VERSION ""

NS_ :

BS_:

BU_: SCCM RF_HUB PTS ORC OCM IC HCP HALF ETM ESM ESC EPS ECM EBCM DIAGNOST DASM CBC AirSusp TCM DTCM ELSDM

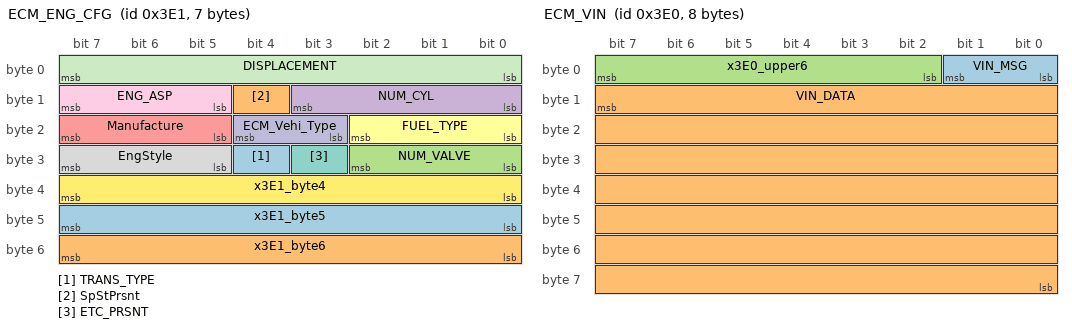
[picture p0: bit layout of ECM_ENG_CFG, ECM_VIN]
BO_ 993 ECM_ENG_CFG: 7 ECM
 SG_ TRANS_TYPE : 28|1@1+ (1,0) [0|0] "" Vector__XXX
 SG_ SpStPrsnt : 12|1@1+ (1,0) [0|0] ""  PTS,HALF,ESC,EPS,CBC
 SG_ NUM_VALVE : 24|3@1+ (1,0) [0|6] "valve-per-cylinder" Vector__XXX
 SG_ NUM_CYL : 8|4@1+ (1,0) [0|14] "cylinders"  IC,HALF,ESC
 SG_ Manufacture : 21|3@1+ (1,0) [0|0] "" Vector__XXX
 SG_ FUEL_TYPE : 16|3@1+ (1,0) [0|0] ""  ORC,IC,ESC,CBC
 SG_ ETC_PRSNT : 27|1@1+ (1,0) [0|0] "" Vector__XXX
 SG_ EngStyle : 29|3@1+ (1,0) [0|0] ""  ESC,CBC
 SG_ ENG_ASP : 13|3@1+ (1,0) [0|0] ""  ESC
 SG_ ECM_Vehi_Type : 19|2@1+ (1,0) [0|0] "" Vector__XXX
 SG_ DISPLACEMENT : 0|8@1+ (0.1,0) [0|25] "liters"  ORC,HALF,ESC
 SG_ x3E1_byte4 : 32|8@1+ (1,0) [0|0] "" Vector__XXX
 SG_ x3E1_byte5 : 40|8@1+ (1,0) [0|0] "" Vector__XXX
 SG_ x3E1_byte6 : 48|8@1+ (1,0) [0|0] "" Vector__XXX

BO_ 992 ECM_VIN: 8 ECM
 SG_ VIN_MSG : 0|2@1+ (1,0) [0|0] ""  EBCM,HCP,ETM,HALF,OCM,ORC,ESM,DASM,ESC,SCCM,EPS,PTS,IC,CBC,RF_HUB
 SG_ VIN_DATA : 15|56@0+ (1,0) [0|0] ""  SCCM,RF_HUB,PTS,ORC,OCM,IC,HCP,HALF,ETM,ESM,ESC,EPS,EBCM,DASM,CBC
 SG_ x3E0_upper6 : 2|6@1+ (1,0) [0|0] "" Vector__XXX

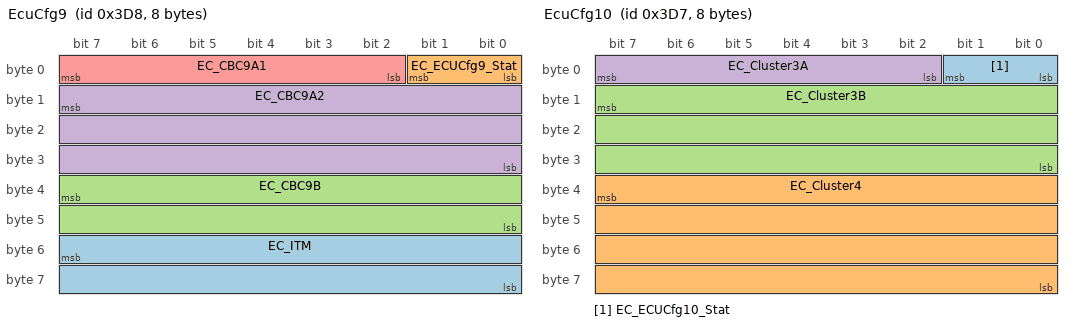
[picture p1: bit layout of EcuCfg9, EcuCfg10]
BO_ 984 EcuCfg9: 8 CBC
 SG_ EC_ITM : 55|16@0+ (1,0) [0|0] ""  RF_HUB
 SG_ EC_ECUCfg9_Stat : 0|2@1+ (1,0) [0|0] ""  RF_HUB
 SG_ EC_CBC9B : 39|16@0+ (1,0) [0|0] ""  RF_HUB
 SG_ EC_CBC9A2 : 15|24@0+ (1,0) [0|0] ""  RF_HUB
 SG_ EC_CBC9A1 : 2|6@1+ (1,0) [0|0] ""  RF_HUB

BO_ 983 EcuCfg10: 8 CBC
 SG_ EC_ECUCfg10_Stat : 0|2@1+ (1,0) [0|0] ""  IC,RF_HUB
 SG_ EC_Cluster4 : 39|32@0+ (1,0) [0|0] ""  RF_HUB
 SG_ EC_Cluster3B : 15|24@0+ (1,0) [0|0] ""  RF_HUB
 SG_ EC_Cluster3A : 2|6@1+ (1,0) [0|0] ""  RF_HUB

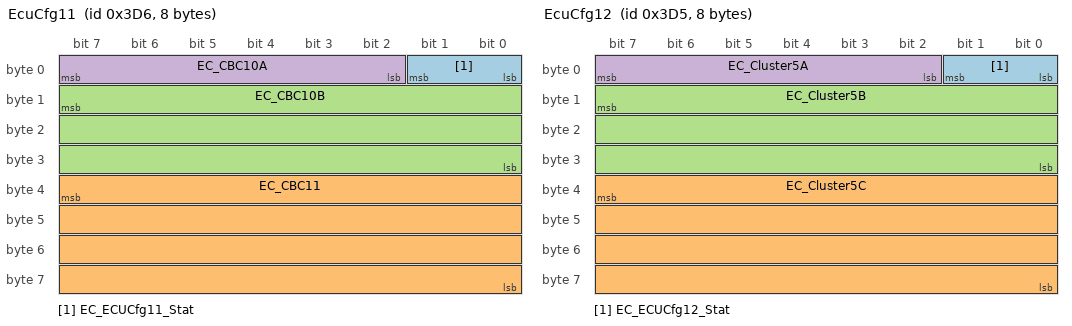
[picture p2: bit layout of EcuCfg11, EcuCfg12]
BO_ 982 EcuCfg11: 8 CBC
 SG_ EC_ECUCfg11_Stat : 0|2@1+ (1,0) [0|0] ""  RF_HUB
 SG_ EC_CBC11 : 39|32@0+ (1,0) [0|0] ""  RF_HUB
 SG_ EC_CBC10B : 15|24@0+ (1,0) [0|0] ""  RF_HUB
 SG_ EC_CBC10A : 2|6@1+ (1,0) [0|0] ""  RF_HUB

BO_ 981 EcuCfg12: 8 CBC
 SG_ EC_ECUCfg12_Stat : 0|2@1+ (1,0) [0|0] ""  IC,RF_HUB
 SG_ EC_Cluster5C : 39|32@0+ (1,0) [0|0] ""  RF_HUB
 SG_ EC_Cluster5B : 15|24@0+ (1,0) [0|0] ""  RF_HUB
 SG_ EC_Cluster5A : 2|6@1+ (1,0) [0|0] ""  RF_HUB

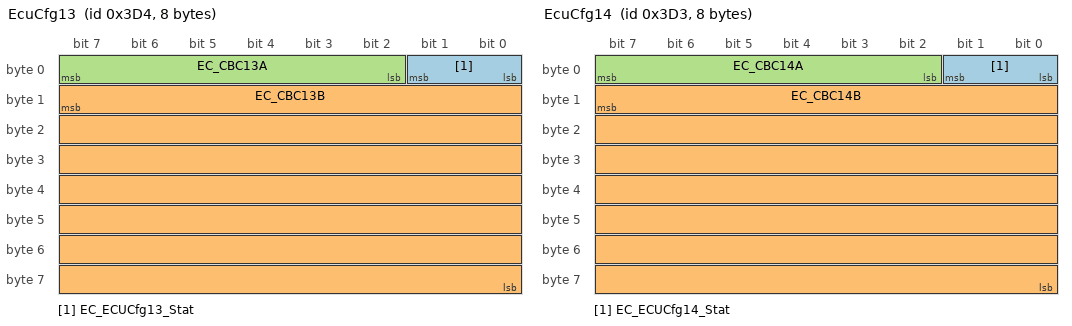
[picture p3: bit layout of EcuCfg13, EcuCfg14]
BO_ 980 EcuCfg13: 8 CBC
 SG_ EC_ECUCfg13_Stat : 0|2@1+ (1,0) [0|0] ""  RF_HUB
 SG_ EC_CBC13B : 15|56@0+ (1,0) [0|0] ""  RF_HUB
 SG_ EC_CBC13A : 2|6@1+ (1,0) [0|0] ""  RF_HUB

BO_ 979 EcuCfg14: 8 CBC
 SG_ EC_ECUCfg14_Stat : 0|2@1+ (1,0) [0|0] ""  RF_HUB
 SG_ EC_CBC14B : 15|56@0+ (1,0) [0|0] ""  RF_HUB
 SG_ EC_CBC14A : 2|6@1+ (1,0) [0|0] ""  RF_HUB

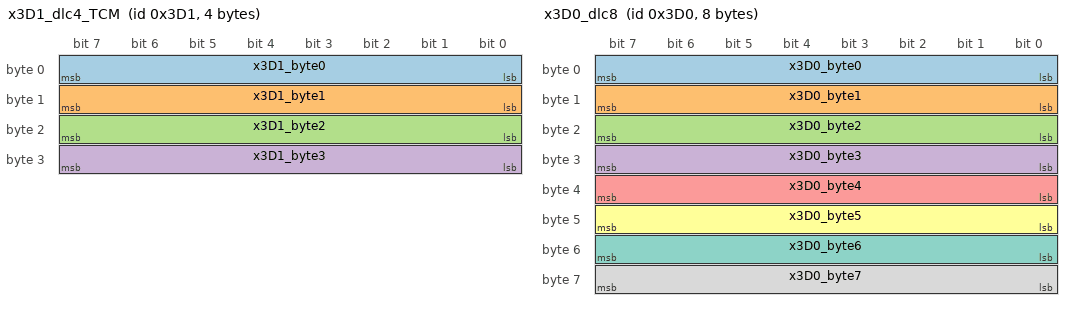
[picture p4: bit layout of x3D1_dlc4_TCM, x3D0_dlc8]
BO_ 977 x3D1_dlc4_TCM: 4 TCM
 SG_ x3D1_byte0 : 0|8@1+ (1,0) [0|255] "" Vector__XXX
 SG_ x3D1_byte1 : 8|8@1+ (1,0) [0|255] "" Vector__XXX
 SG_ x3D1_byte2 : 16|8@1+ (1,0) [0|255] "" Vector__XXX
 SG_ x3D1_byte3 : 24|8@1+ (1,0) [0|255] "" Vector__XXX

BO_ 976 x3D0_dlc8: 8 Vector__XXX
 SG_ x3D0_byte0 : 0|8@1+ (1,0) [0|255] "" Vector__XXX
 SG_ x3D0_byte1 : 8|8@1+ (1,0) [0|255] "" Vector__XXX
 SG_ x3D0_byte2 : 16|8@1+ (1,0) [0|255] "" Vector__XXX
 SG_ x3D0_byte3 : 24|8@1+ (1,0) [0|255] "" Vector__XXX
 SG_ x3D0_byte4 : 32|8@1+ (1,0) [0|255] "" Vector__XXX
 SG_ x3D0_byte5 : 40|8@1+ (1,0) [0|255] "" Vector__XXX
 SG_ x3D0_byte6 : 48|8@1+ (1,0) [0|255] "" Vector__XXX
 SG_ x3D0_byte7 : 56|8@1+ (1,0) [0|255] "" Vector__XXX

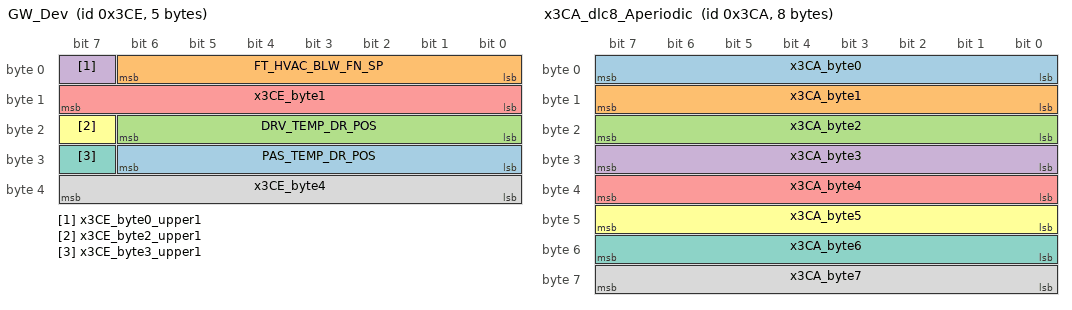
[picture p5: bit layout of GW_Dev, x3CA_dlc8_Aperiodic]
BO_ 974 GW_Dev: 5 CBC
 SG_ PAS_TEMP_DR_POS : 24|7@1+ (1,0) [0|100] "%"  HCP
 SG_ FT_HVAC_BLW_FN_SP : 0|7@1+ (1,0) [0|100] "Bars"  ECM
 SG_ DRV_TEMP_DR_POS : 16|7@1+ (1,0) [0|100] "%"  HCP,ECM
 SG_ x3CE_byte0_upper1 : 7|1@1+ (1,0) [0|1] "" Vector__XXX
 SG_ x3CE_byte1 : 8|8@1+ (1,0) [0|255] "" Vector__XXX
 SG_ x3CE_byte2_upper1 : 23|1@1+ (1,0) [0|1] "" Vector__XXX
 SG_ x3CE_byte3_upper1 : 31|1@1+ (1,0) [0|1] "" Vector__XXX
 SG_ x3CE_byte4 : 32|8@1+ (1,0) [0|255] "" Vector__XXX

BO_ 973 x3CD_dlc8_IC: 8 IC
 SG_ x3CD_byte0_lower6 : 0|6@1+ (1,0) [0|63] "" Vector__XXX
 SG_ x3CD_byte1 : 8|8@1+ (1,0) [0|255] "" Vector__XXX
 SG_ x3CD_byte2 : 16|8@1+ (1,0) [0|255] "" Vector__XXX
 SG_ x3CD_byte3 : 24|8@1+ (1,0) [0|255] "" Vector__XXX
 SG_ x3CD_byte4 : 32|8@1+ (1,0) [0|255] "" Vector__XXX
 SG_ x3CD_byte5 : 40|8@1+ (1,0) [0|255] "" Vector__XXX
 SG_ x3CD_byte6 : 48|8@1+ (1,0) [0|255] "" Vector__XXX
 SG_ x3CD_byte7 : 56|8@1+ (1,0) [0|255] "" Vector__XXX
 SG_ x3CD_IC_RedBRAKELampOn : 7|1@1+ (1,0) [0|1] "Bool" Vector__XXX
 SG_ x3CD_byte0_upper1 : 8|1@1+ (1,0) [0|1] "" Vector__XXX

BO_ 970 x3CA_dlc8_Aperiodic: 8 Vector__XXX
 SG_ x3CA_byte0 : 0|8@1+ (1,0) [0|255] "" Vector__XXX
 SG_ x3CA_byte1 : 8|8@1+ (1,0) [0|255] "" Vector__XXX
 SG_ x3CA_byte2 : 16|8@1+ (1,0) [0|255] "" Vector__XXX
 SG_ x3CA_byte3 : 24|8@1+ (1,0) [0|255] "" Vector__XXX
 SG_ x3CA_byte4 : 32|8@1+ (1,0) [0|255] "" Vector__XXX
 SG_ x3CA_byte5 : 40|8@1+ (1,0) [0|255] "" Vector__XXX
 SG_ x3CA_byte6 : 48|8@1+ (1,0) [0|255] "" Vector__XXX
 SG_ x3CA_byte7 : 56|8@1+ (1,0) [0|255] "" Vector__XXX

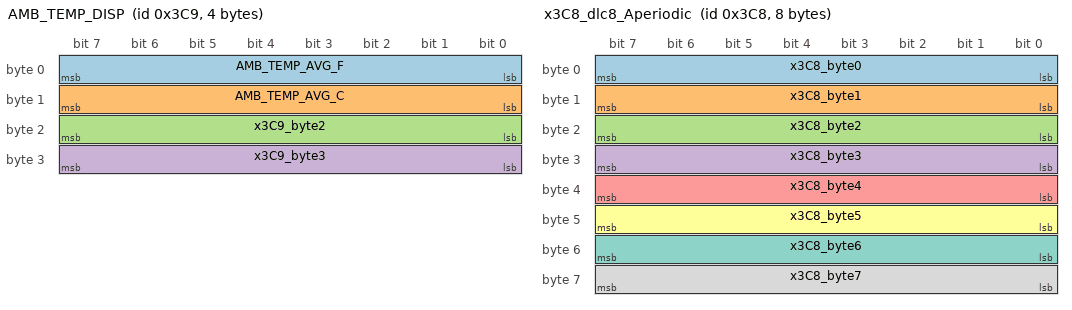
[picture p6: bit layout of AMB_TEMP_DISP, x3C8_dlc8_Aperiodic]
BO_ 969 AMB_TEMP_DISP: 4 CBC
 SG_ AMB_TEMP_AVG_F : 0|8@1+ (1,-40) [-40|210] "°F"  IC,HCP
 SG_ AMB_TEMP_AVG_C : 8|8@1+ (1,-40) [-40|210] "°C"  IC,ETM
 SG_ x3C9_byte2 : 16|8@1+ (1,0) [0|255] "" Vector__XXX
 SG_ x3C9_byte3 : 24|8@1+ (1,0) [0|255] "" Vector__XXX

BO_ 968 x3C8_dlc8_Aperiodic: 8 Vector__XXX
 SG_ x3C8_byte0 : 0|8@1+ (1,0) [0|255] "" Vector__XXX
 SG_ x3C8_byte1 : 8|8@1+ (1,0) [0|255] "" Vector__XXX
 SG_ x3C8_byte2 : 16|8@1+ (1,0) [0|255] "" Vector__XXX
 SG_ x3C8_byte3 : 24|8@1+ (1,0) [0|255] "" Vector__XXX
 SG_ x3C8_byte4 : 32|8@1+ (1,0) [0|255] "" Vector__XXX
 SG_ x3C8_byte5 : 40|8@1+ (1,0) [0|255] "" Vector__XXX
 SG_ x3C8_byte6 : 48|8@1+ (1,0) [0|255] "" Vector__XXX
 SG_ x3C8_byte7 : 56|8@1+ (1,0) [0|255] "" Vector__XXX

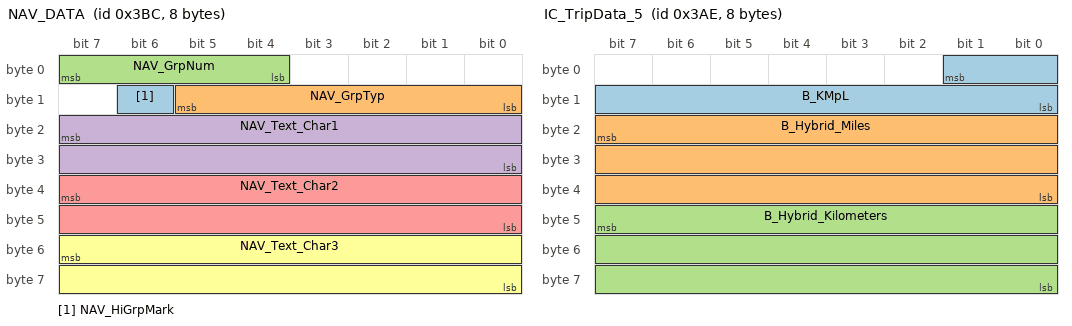
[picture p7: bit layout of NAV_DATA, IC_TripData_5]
BO_ 956 NAV_DATA: 8 CBC
 SG_ NAV_HiGrpMark : 14|1@1+ (1,0) [0|0] ""  IC
 SG_ NAV_GrpTyp : 8|6@1+ (1,0) [0|40] "Text"  IC
 SG_ NAV_GrpNum : 4|4@1+ (1,1) [1|16] "Group"  IC
 SG_ NAV_Text_Char1 : 23|16@0+ (1,0) [0|65535] "ascii" Vector__XXX
 SG_ NAV_Text_Char2 : 39|16@0+ (1,0) [0|65535] "ascii" Vector__XXX
 SG_ NAV_Text_Char3 : 55|16@0+ (1,0) [0|65535] "ascii" Vector__XXX

BO_ 948 VehCfgCSM2: 8 CBC
 SG_ VC_WHL_ALGN_CSO : 13|1@1+ (1,0) [0|0] ""  RF_HUB
 SG_ VC_VehCfgCSO2_Stat : 0|2@1+ (1,0) [0|0] ""  RF_HUB,IC
 SG_ VC_US_METRIC_CSO : 12|1@1+ (1,0) [0|0] ""  RF_HUB
 SG_ VC_TRNS_MD_CSO : 11|1@1+ (1,0) [0|0] ""  RF_HUB
 SG_ VC_TRLR_TYPE_CSO : 10|1@1+ (1,0) [0|0] ""  RF_HUB
 SG_ VC_TRLR_NAME_CSO : 9|1@1+ (1,0) [0|0] ""  RF_HUB
 SG_ VC_TRLR_CSO : 8|1@1+ (1,0) [0|0] ""  RF_HUB
 SG_ VC_TORQUE_CSO : 7|1@1+ (1,0) [0|0] ""  RF_HUB
 SG_ VC_TLT_MRR_CSO : 6|1@1+ (1,0) [0|0] ""  RF_HUB
 SG_ VC_TEMP_CSO : 15|1@1+ (1,0) [0|0] ""  RF_HUB
 SG_ VC_TEEN_SLD_DR_CHM_CSO : 38|1@1+ (1,0) [0|0] ""  RF_HUB
 SG_ VC_TEEN_SLD_DR_ALRT_CSO : 35|1@1+ (1,0) [0|0] ""  RF_HUB
 SG_ VC_TEEN_RR_PRK_VOL_CSO : 27|1@1+ (1,0) [0|0] ""  RF_HUB
 SG_ VC_TEEN_RAIN_WPR_CSO : 32|1@1+ (1,0) [0|0] ""  RF_HUB
 SG_ VC_TEEN_PRK_ASST_CSO : 25|1@1+ (1,0) [0|0] ""  RF_HUB
 SG_ VC_TEEN_PLG_CHIME_CSO : 36|1@1+ (1,0) [0|0] ""  RF_HUB
 SG_ VC_TEEN_MAX_SPEED_CSO : 28|1@1+ (1,0) [0|0] ""  RF_HUB
 SG_ VC_TEEN_LGHT_WPR_CSO : 34|1@1+ (1,0) [0|0] ""  RF_HUB
 SG_ VC_TEEN_FUEL_WRN_CSO : 29|1@1+ (1,0) [0|0] ""  RF_HUB
 SG_ VC_TEEN_FUEL_POPUP_CSO : 30|1@1+ (1,0) [0|0] ""  RF_HUB
 SG_ VC_TEEN_FT_PRK_VOL_CSO : 26|1@1+ (1,0) [0|0] ""  RF_HUB
 SG_ VC_TEEN_FCW_SENS_CSO : 23|1@1+ (1,0) [0|0] ""  RF_HUB
 SG_ VC_TEEN_FCW_BRK_CSO : 24|1@1+ (1,0) [0|0] ""  RF_HUB
 SG_ VC_TEEN_BLIND_SPOT_CSO : 31|1@1+ (1,0) [0|0] ""  RF_HUB
 SG_ VC_TEEN_AUTO_HB_CSO : 33|1@1+ (1,0) [0|0] ""  RF_HUB
 SG_ VC_SVC_GRIDLINES_CSO : 20|1@1+ (1,0) [0|0] ""  RF_HUB
 SG_ VC_SVC_DELAY_CSO : 21|1@1+ (1,0) [0|0] ""  RF_HUB
 SG_ VC_SPEED_WARNING_CSO : 41|2@1+ (1,0) [0|0] ""  RF_HUB
 SG_ VC_SPEED_CSO : 5|1@1+ (1,0) [0|0] ""  RF_HUB
 SG_ VC_SLD_DR_CHM_CSO : 37|1@1+ (1,0) [0|0] ""  RF_HUB
 SG_ VC_SLD_DR_ALRT_CSO : 22|1@1+ (1,0) [0|0] ""  RF_HUB
 SG_ VC_RKE_UNLK_CSO : 4|1@1+ (1,0) [0|0] ""  RF_HUB
 SG_ VC_RKE_MEM_CSO : 3|1@1+ (1,0) [0|0] ""  RF_HUB
 SG_ VC_REAR_CMRA_DLY_CSO : 2|1@1+ (1,0) [0|0] ""  RF_HUB
 SG_ VC_RDY_DRV_CSO : 55|1@1+ (1,0) [0|0] ""  RF_HUB
 SG_ VC_PWR_FLD_MRR_CSO : 17|1@1+ (1,0) [0|0] ""  RF_HUB
 SG_ VC_PRK_ASST_TYPE_CSO : 44|1@1+ (1,0) [0|0] ""  RF_HUB
 SG_ VC_PADDLE_SHIFT_CSO : 39|1@1+ (1,0) [0|0] ""  RF_HUB
 SG_ VC_LDW_ON_CSO : 43|1@1+ (1,0) [0|0] ""  RF_HUB
 SG_ VC_HOLD_N_GO_CSO : 16|1@1+ (1,0) [0|0] ""  RF_HUB
 SG_ VC_HANDS_FREE_SLDR_CSO : 19|1@1+ (1,0) [0|0] ""  RF_HUB
 SG_ VC_HANDS_FREE_LFT_CSO : 18|1@1+ (1,0) [0|0] ""  RF_HUB
 SG_ VC_FUEL_SAV_CSO : 14|1@1+ (1,0) [0|0] ""  RF_HUB
 SG_ VC_FLSH_LMP_SLDR_CSO : 40|1@1+ (1,0) [0|0] ""  RF_HUB
 SG_ VC_FCW_SW_CSO : 47|1@1+ (1,0) [0|0] ""  RF_HUB
 SG_ VC_EPB_ON_CSO : 45|1@1+ (1,0) [0|0] ""  RF_HUB
 SG_ VC_AIRBAG_ON_CSO : 46|1@1+ (1,0) [0|0] ""  RF_HUB
 SG_ x3B4_byte6_lower7 : 48|7@1+ (1,0) [0|127] "" Vector__XXX
 SG_ x3B4_byte7 : 56|8@1+ (1,0) [0|255] "" Vector__XXX

BO_ 947 VehCfgCSM1: 8 CBC
 SG_ VC_VehCfgCSO1_Stat : 0|2@1+ (1,0) [0|0] ""  RF_HUB,IC
 SG_ VC_REAR_CMRA_CSO : 63|1@1+ (1,0) [0|0] ""  RF_HUB
 SG_ VC_RAIN_WPR_CSO : 62|1@1+ (1,0) [0|0] ""  RF_HUB
 SG_ VC_PTO_CSO : 61|1@1+ (1,0) [0|0] ""  RF_HUB
 SG_ VC_PRK_RR_VOL_CSO : 6|1@1+ (1,0) [0|0] ""  RF_HUB
 SG_ VC_PRK_FT_VOL_CSO : 5|1@1+ (1,0) [0|0] ""  RF_HUB
 SG_ VC_PRK_AST_CSO : 2|2@1+ (1,0) [0|0] ""  RF_HUB
 SG_ VC_PRK_AST_BRK_CSO : 4|1@1+ (1,0) [0|0] ""  RF_HUB
 SG_ VC_PRESSURE_CSO : 60|1@1+ (1,0) [0|0] ""  RF_HUB
 SG_ VC_POWER_CSO : 59|1@1+ (1,0) [0|0] ""  RF_HUB
 SG_ VC_POLICE_PE_CSO : 23|1@1+ (1,0) [0|0] ""  RF_HUB
 SG_ VC_PLG_CHM_CSO : 58|1@1+ (1,0) [0|0] ""  RF_HUB
 SG_ VC_PER_SHFT_RPM_CSO : 57|1@1+ (1,0) [0|0] ""  RF_HUB
 SG_ VC_PER_SHFT_ENBL_CSO : 56|1@1+ (1,0) [0|0] ""  RF_HUB
 SG_ VC_PE_CSO : 55|1@1+ (1,0) [0|0] ""  RF_HUB
 SG_ VC_NAV_TRN_CSO : 54|1@1+ (1,0) [0|0] ""  RF_HUB
 SG_ VC_LGHT_RMT_LWR_CSO : 53|1@1+ (1,0) [0|0] ""  RF_HUB
 SG_ VC_LDW_WRN_CSO : 52|1@1+ (1,0) [0|0] ""  RF_HUB
 SG_ VC_LDW_TRQ_CSO : 51|1@1+ (1,0) [0|0] ""  RF_HUB
 SG_ VC_ILL_APPRCH_CSO : 50|1@1+ (1,0) [0|0] ""  RF_HUB
 SG_ VC_HSA_CSO : 49|1@1+ (1,0) [0|0] ""  RF_HUB
 SG_ VC_HRN_RMT_ST_CSO : 13|1@1+ (1,0) [0|0] ""  RF_HUB
 SG_ VC_HRN_RMT_LWR_CSO : 14|1@1+ (1,0) [0|0] ""  RF_HUB
 SG_ VC_HRN_RMT_LK_CSO : 11|2@1+ (1,0) [0|0] ""  RF_HUB
 SG_ VC_HL_WPR_CSO : 48|1@1+ (1,0) [0|0] ""  RF_HUB
 SG_ VC_HL_OFF_DLY_CSO : 47|1@1+ (1,0) [0|0] ""  RF_HUB
 SG_ VC_HL_DRP_CSO : 46|1@1+ (1,0) [0|0] ""  RF_HUB
 SG_ VC_FLSH_LMP_LK_CSO : 45|1@1+ (1,0) [0|0] ""  RF_HUB
 SG_ VC_FCW_CSO : 8|2@1+ (1,0) [0|0] ""  RF_HUB
 SG_ VC_FCW_BRK_CSO : 10|1@1+ (1,0) [0|0] ""  RF_HUB
 SG_ VC_EPS_CSO : 7|1@1+ (1,0) [0|0] ""  RF_HUB
 SG_ VC_EPB_SERV_CSO : 44|1@1+ (1,0) [0|0] ""  RF_HUB
 SG_ VC_ENTRY_EXIT_CSO : 43|1@1+ (1,0) [0|0] ""  RF_HUB
 SG_ VC_EASY_EXIT_CSO : 42|1@1+ (1,0) [0|0] ""  RF_HUB
 SG_ VC_DRL_CSO : 41|1@1+ (1,0) [0|0] ""  RF_HUB
 SG_ VC_DR_UNLK_CSO : 40|1@1+ (1,0) [0|0] ""  RF_HUB
 SG_ VC_DR_LK_CSO : 39|1@1+ (1,0) [0|0] ""  RF_HUB
 SG_ VC_DISTANCE_CSO : 38|1@1+ (1,0) [0|0] ""  RF_HUB
 SG_ VC_DCS_CSO : 16|2@1+ (1,0) [0|0] ""  RF_HUB
 SG_ VC_CONS_CSO : 37|1@1+ (1,0) [0|0] ""  RF_HUB
 SG_ VC_CMRA_GRDLNS_CSO : 20|2@1+ (1,0) [0|0] ""  RF_HUB
 SG_ VC_CMP_VAR_CSO : 36|1@1+ (1,0) [0|0] ""  RF_HUB
 SG_ VC_CMP_CAL_CSO : 35|1@1+ (1,0) [0|0] ""  RF_HUB
 SG_ VC_CLK_DSP_CSO : 34|1@1+ (1,0) [0|0] ""  RF_HUB
 SG_ VC_CHMSL_LINE_CSO : 15|1@1+ (1,0) [0|0] ""  RF_HUB
 SG_ VC_CAPACITY_CSO : 33|1@1+ (1,0) [0|0] ""  RF_HUB
 SG_ VC_BLIND_SPOT_CSO : 32|1@1+ (1,0) [0|0] ""  RF_HUB
 SG_ VC_AUX_SWS_CSO : 18|2@1+ (1,0) [0|0] ""  RF_HUB
 SG_ VC_AUTO_PRK_CSO : 31|1@1+ (1,0) [0|0] ""  RF_HUB
 SG_ VC_AUTO_HB_CSO : 30|1@1+ (1,0) [0|0] ""  RF_HUB
 SG_ VC_AUTO_AERO_CSO : 29|1@1+ (1,0) [0|0] ""  RF_HUB
 SG_ VC_ASCM_WRN_CSO : 28|1@1+ (1,0) [0|0] ""  RF_HUB
 SG_ VC_ASCM_TJ_CSO : 27|1@1+ (1,0) [0|0] ""  RF_HUB
 SG_ VC_AMB_DMR_CSO : 26|1@1+ (1,0) [0|0] ""  RF_HUB
 SG_ VC_AFLS_CSO : 25|1@1+ (1,0) [0|0] ""  RF_HUB
 SG_ VC_ACC_DLY_CSO : 24|1@1+ (1,0) [0|0] ""  RF_HUB
 SG_ x3B3_byte2_middle1 : 22|1@1+ (1,0) [0|1] "" Vector__XXX

BO_ 943 IC_TripData_6: 8 IC
 SG_ B_Total_Dist_Miles : 23|24@0+ (0.1,0) [0|9999.9] "Mile"  ETM
 SG_ B_Total_Dist_Kilometers : 47|24@0+ (0.1,0) [0|16093.3] "km"  ETM

BO_ 942 IC_TripData_5: 8 IC
 SG_ B_KMpL : 1|10@0+ (0.1,0) [0|99.9] "kmpl"  ETM
 SG_ B_Hybrid_Miles : 23|24@0+ (0.1,0) [0|9999.9] "Mile"  ETM
 SG_ B_Hybrid_Kilometers : 47|24@0+ (0.1,0) [0|16093.3] "km"  ETM

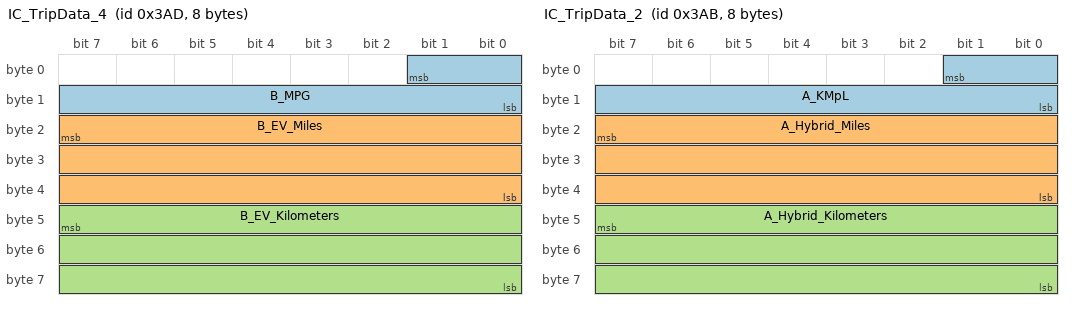
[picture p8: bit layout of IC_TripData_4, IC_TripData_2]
BO_ 941 IC_TripData_4: 8 IC
 SG_ B_MPG : 1|10@0+ (0.1,0) [0|99.9] "MPG"  ETM
 SG_ B_EV_Miles : 23|24@0+ (0.1,0) [0|9999.9] "Mile"  ETM
 SG_ B_EV_Kilometers : 47|24@0+ (0.1,0) [0|16093.3] "km"  ETM

BO_ 940 IC_TripData_3: 8 IC
 SG_ A_Total_Dist_Miles : 23|24@0+ (0.1,0) [0|9999.9] "Mile"  ETM
 SG_ A_Total_Dist_Kilometers : 47|24@0+ (0.1,0) [0|16093.3] "km"  ETM

BO_ 939 IC_TripData_2: 8 IC
 SG_ A_KMpL : 1|10@0+ (0.1,0) [0|99.9] "kmpl"  ETM
 SG_ A_Hybrid_Miles : 23|24@0+ (0.1,0) [0|9999.9] "Mile"  ETM
 SG_ A_Hybrid_Kilometers : 47|24@0+ (0.1,0) [0|16093.3] "km"  ETM

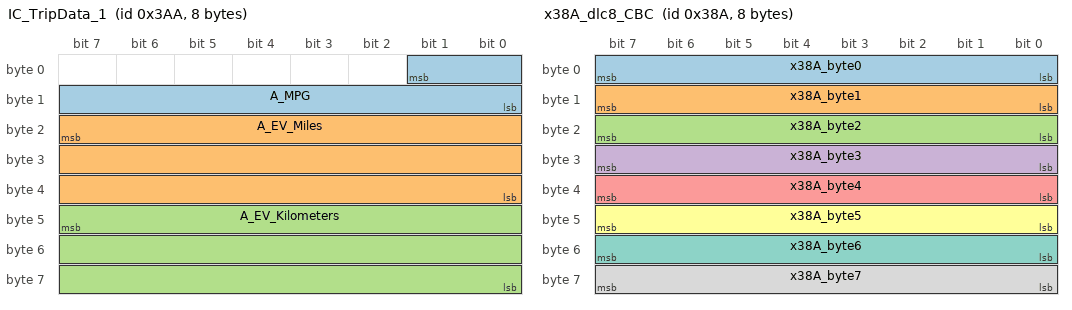
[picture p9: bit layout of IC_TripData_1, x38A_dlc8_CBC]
BO_ 938 IC_TripData_1: 8 IC
 SG_ A_MPG : 1|10@0+ (0.1,0) [0|99.9] "MPG"  ETM
 SG_ A_EV_Miles : 23|24@0+ (0.1,0) [0|9999.9] "Mile"  ETM
 SG_ A_EV_Kilometers : 47|24@0+ (0.1,0) [0|16093.3] "km"  ETM

BO_ 937 CBC_CFG1: 8 CBC
 SG_ SOUND_RS : 52|1@1+ (1,0) [0|0] "" Vector__XXX
 SG_ SOUND_LK_1ST_2ND : 56|2@1+ (1,0) [0|0] "" Vector__XXX
 SG_ SOUND_LK : 1|1@1+ (1,0) [0|0] "" Vector__XXX
 SG_ ILL_APRCH_TIME : 8|8@1+ (1,0) [0|254] "sec" Vector__XXX
 SG_ HL_WPR : 3|1@1+ (1,0) [0|0] "" Vector__XXX
 SG_ HL_DLY_TIME : 16|8@1+ (1,0) [0|254] "sec" Vector__XXX
 SG_ FLASH_LK : 2|1@1+ (1,0) [0|0] "" Vector__XXX
 SG_ DRL_ON : 40|1@1+ (1,0) [0|0] "" Vector__XXX
 SG_ CFG_AUTO_WPR : 7|1@1+ (1,0) [0|0] "" Vector__XXX
 SG_ x3A9_byte0_lower1 : 0|1@1+ (1,0) [0|1] "" Vector__XXX
 SG_ x3A9_byte0_middle3 : 4|3@1+ (1,0) [0|7] "" Vector__XXX
 SG_ x3A9_byte3 : 24|8@1+ (1,0) [0|255] "" Vector__XXX
 SG_ x3A9_byte4 : 32|8@1+ (1,0) [0|255] "" Vector__XXX
 SG_ x3A9_byte5_upper7 : 41|7@1+ (1,0) [0|127] "" Vector__XXX
 SG_ x3A9_byte6_lower4 : 48|4@1+ (1,0) [0|15] "" Vector__XXX
 SG_ x3A9_byte6_upper3 : 53|3@1+ (1,0) [0|7] "" Vector__XXX
 SG_ x3A9_byte7_upper6 : 58|6@1+ (1,0) [0|63] "" Vector__XXX

BO_ 924 x39C_RFHUB_A3: 8 RF_HUB
 SG_ MsgServPEKG : 2|2@1+ (1,0) [0|0] "" Vector__XXX
 SG_ MsgNotInPark : 6|2@1+ (1,0) [0|0] ""  IC
 SG_ MsgKG2 : 14|2@1+ (1,0) [0|0] ""  IC
 SG_ MsgKG1 : 12|2@1+ (1,0) [0|0] ""  IC
 SG_ MsgFobNotFnd : 4|2@1+ (1,0) [0|0] ""  IC
 SG_ MsgFobBattLow : 0|2@1+ (1,0) [0|0] ""  IC
 SG_ FOBinTRUNK : 19|1@1+ (1,0) [0|0] "" Vector__XXX
 SG_ FOBinINT : 20|1@1+ (1,0) [0|0] ""  CBC
 SG_ FOB_SrchRslt : 16|2@1+ (1,0) [0|0] ""  CBC
 SG_ FOB_SrchFLT : 18|1@1+ (1,0) [0|0] ""  CBC
 SG_ FOB_ExtRT : 21|1@1+ (1,0) [0|0] ""  CBC
 SG_ FOB_ExtRR : 23|1@1+ (1,0) [0|0] ""  CBC
 SG_ FOB_ExtLT : 22|1@1+ (1,0) [0|0] ""  CBC
 SG_ x39C_byte3 : 24|8@1+ (1,0) [0|255] "" Vector__XXX
 SG_ x39C_byte4 : 32|8@1+ (1,0) [0|255] "" Vector__XXX
 SG_ x39C_byte5 : 40|8@1+ (1,0) [0|255] "" Vector__XXX
 SG_ x39C_byte6 : 48|8@1+ (1,0) [0|255] "" Vector__XXX
 SG_ x39C_byte7 : 56|8@1+ (1,0) [0|255] "" Vector__XXX
 SG_ x39C_byte1_lower4 : 8|4@1+ (1,0) [0|15] "" Vector__XXX

BO_ 906 x38A_dlc8_CBC: 8 CBC
 SG_ x38A_byte0 : 0|8@1+ (1,0) [0|255] "" Vector__XXX
 SG_ x38A_byte1 : 8|8@1+ (1,0) [0|255] "" Vector__XXX
 SG_ x38A_byte2 : 16|8@1+ (1,0) [0|255] "" Vector__XXX
 SG_ x38A_byte3 : 24|8@1+ (1,0) [0|255] "" Vector__XXX
 SG_ x38A_byte4 : 32|8@1+ (1,0) [0|255] "" Vector__XXX
 SG_ x38A_byte5 : 40|8@1+ (1,0) [0|255] "" Vector__XXX
 SG_ x38A_byte6 : 48|8@1+ (1,0) [0|255] "" Vector__XXX
 SG_ x38A_byte7 : 56|8@1+ (1,0) [0|255] "" Vector__XXX

BO_ 897 VehCfg7: 8 CBC
 SG_ VC_VehCfg7_Stat : 0|2@1+ (1,0) [0|0] ""  RF_HUB,PTS,ORC,IC,HALF,ECM,DASM
 SG_ VC_TSBM_Prsnt : 39|1@1+ (1,0) [0|0] ""  RF_HUB
 SG_ VC_TrnsDrvMdPrsnt : 3|1@1+ (1,0) [0|0] ""  RF_HUB
 SG_ VC_TransType : 8|6@1+ (1,0) [0|0] ""  RF_HUB,IC,ESC
 SG_ VC_Trans_N_Hold_Prsnt : 23|1@1+ (1,0) [0|0] ""  RF_HUB
 SG_ VC_Trans_Equipped : 28|1@1+ (1,0) [0|0] ""  RF_HUB,PTS,ORC,IC,HALF,ESC,EPS
 SG_ VC_TPMS_Configuration : 32|3@1+ (1,0) [0|0] ""  RF_HUB,IC
 SG_ VC_TeenKey : 16|1@1+ (1,0) [0|0] ""  RF_HUB,PTS,IC,ECM,DASM
 SG_ VC_SVC_Prsnt : 17|1@1+ (1,0) [0|0] ""  RF_HUB
 SG_ VC_SuspPrsnt : 21|1@1+ (1,0) [0|0] ""  RF_HUB
 SG_ VC_SUNR_Prsnt : 47|1@1+ (1,0) [0|0] ""  RF_HUB
 SG_ VC_STP_PRSNT : 6|1@1+ (1,0) [0|0] ""  RF_HUB
 SG_ VC_RedKey : 24|1@1+ (1,0) [0|0] ""  RF_HUB
 SG_ VC_PdlsMdPrsnt : 4|1@1+ (1,0) [0|0] ""  RF_HUB
 SG_ VC_PBTyp : 29|3@1+ (1,0) [0|0] ""  RF_HUB,PTS,ORC,ESC
 SG_ VC_LDW : 2|1@1+ (1,0) [0|0] ""  RF_HUB,ORC,IC,HALF
 SG_ VC_HybridType : 36|3@1+ (1,0) [0|0] ""  RF_HUB,PTS,ORC,ESC,EPS,ECM,DASM
 SG_ VC_FullSpeedRange_FCW : 18|1@1+ (1,0) [0|0] ""  RF_HUB,HALF,ESC,DASM
 SG_ VC_eShifter_Prsnt : 7|1@1+ (1,0) [0|0] ""  RF_HUB,ESC
 SG_ VC_DST_Present : 5|1@1+ (1,0) [0|0] ""  RF_HUB,ESC,EPS
 SG_ VC_DampingPrsnt : 22|1@1+ (1,0) [0|0] ""  RF_HUB
 SG_ VC_AxleLockerPrsnt : 26|2@1+ (1,0) [0|0] ""  RF_HUB
 SG_ VC_AS_ERS : 14|2@1+ (1,0) [0|0] ""  RF_HUB
 SG_ VC_ACC_Type : 19|2@1+ (1,0) [0|0] ""  RF_HUB,PTS,ORC,IC,HALF,ESC,ECM,DASM
 SG_ VC_ABSM : 25|1@1+ (1,0) [0|0] ""  RF_HUB
 SG_ x381_byte4_middle1 : 35|1@1+ (1,0) [0|1] "" Vector__XXX
 SG_ x381_byte5_lower7 : 40|7@1+ (1,0) [0|127] "" Vector__XXX
 SG_ x381_byte6 : 48|8@1+ (1,0) [0|255] "" Vector__XXX
 SG_ x381_byte7 : 56|8@1+ (1,0) [0|255] "" Vector__XXX

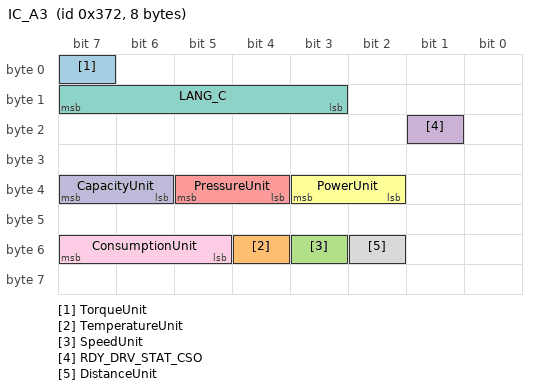
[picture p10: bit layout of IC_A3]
BO_ 882 IC_A3: 8 IC
 SG_ TorqueUnit : 7|1@1+ (1,0) [0|0] ""  CBC
 SG_ TemperatureUnit : 52|1@1+ (1,0) [0|0] ""  CBC
 SG_ SpeedUnit : 51|1@1+ (1,0) [0|0] ""  ECM,DASM,CBC
 SG_ RDY_DRV_STAT_CSO : 17|1@1+ (1,0) [0|0] ""  CBC
 SG_ PressureUnit : 36|2@1+ (1,0) [0|0] ""  CBC
 SG_ PowerUnit : 34|2@1+ (1,0) [0|0] ""  CBC
 SG_ LANG_C : 11|5@1+ (1,0) [0|0] ""  CBC
 SG_ DistanceUnit : 50|1@1+ (1,0) [0|0] ""  CBC
 SG_ ConsumptionUnit : 53|3@1+ (1,0) [0|0] ""  CBC
 SG_ CapacityUnit : 38|2@1+ (1,0) [0|0] ""  CBC

CM_ SG_ 993 TRANS_TYPE "Transmission type; [0] = manual, [1] = automatic";
CM_ SG_ 993 SpStPrsnt "Stop start feature present";
CM_ SG_ 993 NUM_VALVE "Number of valves per cylinder";
CM_ SG_ 993 NUM_CYL "Number of engine cylinders";
CM_ SG_ 993 Manufacture "Engine manufacture";
CM_ SG_ 993 FUEL_TYPE "Fuel type";
CM_ SG_ 993 ETC_PRSNT "Electronic throttle control";
CM_ SG_ 993 EngStyle "Engine output version";
CM_ SG_ 993 ENG_ASP "Engine aspiration method";
CM_ SG_ 993 ECM_Vehi_Type "Engine vehicle type";
CM_ SG_ 993 DISPLACEMENT "Engine displacement";
CM_ SG_ 992 VIN_MSG "VIN Message Information";
CM_ SG_ 992 VIN_DATA "VIN Digits (8 bit ascii encoded) - see Signal Description Doc for details";
CM_ SG_ 984 EC_ITM "ITM ecu configuration";
CM_ SG_ 984 EC_ECUCfg9_Stat "ECU Configuration messages status 9";
CM_ SG_ 984 EC_CBC9B "CBC configuration 9B";
CM_ SG_ 984 EC_CBC9A2 "CBC configuration 9A2";
CM_ SG_ 984 EC_CBC9A1 "CBC configuration 9A1";
CM_ SG_ 983 EC_ECUCfg10_Stat "ECU Configuration messages status 10";
CM_ SG_ 983 EC_Cluster4 "Instrument cluster ecu configuration 4";
CM_ SG_ 983 EC_Cluster3B "Instrument cluster ecu configuration 3B";
CM_ SG_ 983 EC_Cluster3A "Instrument cluster ecu configuration 3A";
CM_ SG_ 982 EC_ECUCfg11_Stat "ECU Configuration messages status 11";
CM_ SG_ 982 EC_CBC11 "CBC ecu configuration 11";
CM_ SG_ 982 EC_CBC10B "CBC ecu configuration 10B";
CM_ SG_ 982 EC_CBC10A "CBC ecu configuration 10A";
CM_ SG_ 981 EC_ECUCfg12_Stat "ECU Configuration messages status 12";
CM_ SG_ 981 EC_Cluster5C "Instrument cluster ecu configuration 5C";
CM_ SG_ 981 EC_Cluster5B "Instrument cluster ecu configuration 5B";
CM_ SG_ 981 EC_Cluster5A "Instrument cluster ecu configuration 5A";
CM_ SG_ 980 EC_ECUCfg13_Stat "ECU Configuration messages status 13";
CM_ SG_ 980 EC_CBC13B "CBC ecu configuration 13B";
CM_ SG_ 980 EC_CBC13A "CBC ecu configuration 13A";
CM_ SG_ 979 EC_ECUCfg14_Stat "ECU Configuration messages status 14";
CM_ SG_ 979 EC_CBC14B "CBC ecu configuration 14B";
CM_ SG_ 979 EC_CBC14A "CBC ecu configuration 14A";
CM_ BO_ 977 "Tx Rate: 493ms, Std Dev: 60.2ms";
CM_ BO_ 976 "Tx Rate: 493ms, Std Dev: 60.2ms";
CM_ SG_ 974 PAS_TEMP_DR_POS "Passenger temperature door postion";
CM_ SG_ 974 FT_HVAC_BLW_FN_SP "Front HVAC blower fan speed status in 'bars'";
CM_ SG_ 974 DRV_TEMP_DR_POS "Driver temperature door postion";
CM_ BO_ 973 "Tx Rate: 1778ms, Std Dev: 613.1ms";
CM_ SG_ 973 x3CD_IC_RedBRAKELampOn "indicates the brake lamp is on on the cluster, though it doesn't say what's causing it to be on (parking brake, brake fault, etc)";
CM_ BO_ 970 "Tx Rate: NaNms, Std Dev: NaNms";
CM_ SG_ 969 AMB_TEMP_AVG_F "Ambient temperature average - in degrees Fahrenheit";
CM_ SG_ 969 AMB_TEMP_AVG_C "Ambient temperature average - in degrees Celsius";
CM_ BO_ 968 "Tx Rate: NaNms, Std Dev: NaNms";
CM_ BO_ 956 "Only TX'ed when navigation is active";
CM_ SG_ 956 NAV_HiGrpMark "NAV high group mark. This is 1 for the first payload of characters, then zero for the following";
CM_ SG_ 956 NAV_GrpTyp "NAV group type. 1 = text???";
CM_ SG_ 956 NAV_GrpNum "NAV group number. Starts at a high value and counts down each time some characters are sent. This will be zero at the last payload of text characters.";
CM_ SG_ 956 NAV_Text_Char1 "New Eagle reverse engineered this for NAV_GrpTyp == 1 only. Not sure if this structure changes for other NAV groups";
CM_ SG_ 956 NAV_Text_Char2 "New Eagle reverse engineered this for NAV_GrpTyp == 1 only. Not sure if this structure changes for other NAV groups";
CM_ SG_ 956 NAV_Text_Char3 "New Eagle reverse engineered this for NAV_GrpTyp == 1 only. Not sure if this structure changes for other NAV groups";
CM_ SG_ 948 VC_WHL_ALGN_CSO "Wheel alignment customer settings menu; Present = [1]";
CM_ SG_ 948 VC_VehCfgCSO2_Stat "Configuration message CSO2 status";
CM_ SG_ 948 VC_US_METRIC_CSO "US metric customer settings menu; Present = [1]";
CM_ SG_ 948 VC_TRNS_MD_CSO "Transport mode customer settings menu; Present = [1]";
CM_ SG_ 948 VC_TRLR_TYPE_CSO "Trailer type customer settings menu; Present = [1]";
CM_ SG_ 948 VC_TRLR_NAME_CSO "Trailer name customer settings menu; Present = [1]";
CM_ SG_ 948 VC_TRLR_CSO "Trailer selected customer settings menu; Present = [1]";
CM_ SG_ 948 VC_TORQUE_CSO "Torque unit customer settings menu; Present = [1]";
CM_ SG_ 948 VC_TLT_MRR_CSO "Tilt mirror in reverse customer settings menu; Present = [1]";
CM_ SG_ 948 VC_TEMP_CSO "Temperature Unit settings menu; Present = [1]";
CM_ SG_ 948 VC_TEEN_SLD_DR_CHM_CSO "Teen key sliding door chime customer setting menu present: Present = 1";
CM_ SG_ 948 VC_TEEN_SLD_DR_ALRT_CSO "Teen key sliding door alert customer setting menu: Present = 1";
CM_ SG_ 948 VC_TEEN_RR_PRK_VOL_CSO "Teen key rear park assist chime volume customer setting menu: Present = 1";
CM_ SG_ 948 VC_TEEN_RAIN_WPR_CSO "Teen key rain sensitive wiper customer setting menu: Present = 1";
CM_ SG_ 948 VC_TEEN_PRK_ASST_CSO "Teen key park assist customer setting menu: Present = 1";
CM_ SG_ 948 VC_TEEN_PLG_CHIME_CSO "Teen key power lift gate chime customer setting menu: Present = 1";
CM_ SG_ 948 VC_TEEN_MAX_SPEED_CSO "Teen key max speed customer setting menu: Present = 1";
CM_ SG_ 948 VC_TEEN_LGHT_WPR_CSO "Teen key lights on with wipers customer setting menu: Present = 1";
CM_ SG_ 948 VC_TEEN_FUEL_WRN_CSO "Teen key early fuel warning customer setting menu: Present = 1";
CM_ SG_ 948 VC_TEEN_FUEL_POPUP_CSO "Teen key fuel pop-up customer setting menu: Present = 1";
CM_ SG_ 948 VC_TEEN_FT_PRK_VOL_CSO "Teen key front park assist chime volume customer setting menu: Present = 1";
CM_ SG_ 948 VC_TEEN_FCW_SENS_CSO "Teen key FCW sensitivity customer setting menu: Present = 1";
CM_ SG_ 948 VC_TEEN_FCW_BRK_CSO "Teen key FCW braking customer setting menu: Present = 1";
CM_ SG_ 948 VC_TEEN_BLIND_SPOT_CSO "Teen key blind spot customer setting menu: Present = 1";
CM_ SG_ 948 VC_TEEN_AUTO_HB_CSO "Teen key automatic highbeam customer setting menu: Present = 1";
CM_ SG_ 948 VC_SVC_GRIDLINES_CSO "Surround view camera gridlines customer setting menu: Present = 1";
CM_ SG_ 948 VC_SVC_DELAY_CSO "Surround view camera delay customer setting menu: Present = 1";
CM_ SG_ 948 VC_SPEED_WARNING_CSO "Speed warning  customer setting";
CM_ SG_ 948 VC_SPEED_CSO "Speed unit customer settings menu; Present = [1]";
CM_ SG_ 948 VC_SLD_DR_CHM_CSO "Sliding door chime customer setting menu present: Present = 1";
CM_ SG_ 948 VC_SLD_DR_ALRT_CSO "Sliding door alert customer setting menu: Present = 1";
CM_ SG_ 948 VC_RKE_UNLK_CSO "RKE unlock customer settings menu; Present = [1]";
CM_ SG_ 948 VC_RKE_MEM_CSO "RKE linked to memory customer settings menu; Present = [1]";
CM_ SG_ 948 VC_REAR_CMRA_DLY_CSO "Rear view camera delay customer settings menu; Present = [1]";
CM_ SG_ 948 VC_RDY_DRV_CSO "Disable ready to drive popup customer settings menu. Present = 1";
CM_ SG_ 948 VC_PWR_FLD_MRR_CSO "Power folding mirror customer setting menu: Present = 1";
CM_ SG_ 948 VC_PRK_ASST_TYPE_CSO "Park assist type customer setting menu present. Present = 1.";
CM_ SG_ 948 VC_PADDLE_SHIFT_CSO "Paddle shifter customer setting menu present.  Present = [1]";
CM_ SG_ 948 VC_LDW_ON_CSO "LDW on/off customer setting menu present.  Present = 1.";
CM_ SG_ 948 VC_HOLD_N_GO_CSO "Hold and go customer setting menu: Present = 1";
CM_ SG_ 948 VC_HANDS_FREE_SLDR_CSO "Hands free sliding door customer setting menu: Present = 1";
CM_ SG_ 948 VC_HANDS_FREE_LFT_CSO "Hands free liftgate customer setting menu: Present = 1";
CM_ SG_ 948 VC_FUEL_SAV_CSO "Fuel Saver settings menu; Present = [1]";
CM_ SG_ 948 VC_FLSH_LMP_SLDR_CSO "Flash lamps with sliding door customer settings menu; Present = [1]";
CM_ SG_ 948 VC_FCW_SW_CSO "FCW Switch customer setting menu present.  Present = 1";
CM_ SG_ 948 VC_EPB_ON_CSO "EPB on/off customer setting menu present. Present = 1.";
CM_ SG_ 948 VC_AIRBAG_ON_CSO "Passenger airbag on/off customer setting menu present. Present = 1.";
CM_ SG_ 947 VC_VehCfgCSO1_Stat "Configuration message CSO1 status";
CM_ SG_ 947 VC_REAR_CMRA_CSO "Rear camera customer settings menu; Present = [1]";
CM_ SG_ 947 VC_RAIN_WPR_CSO "Rain sensitive wipers customer settings menu; Present = [1]";
CM_ SG_ 947 VC_PTO_CSO "Power take off customer settings menu; Present = [1]";
CM_ SG_ 947 VC_PRK_RR_VOL_CSO "Park assist rear volume customer settings menu; Present = [1]";
CM_ SG_ 947 VC_PRK_FT_VOL_CSO "Park assist front volume customer settings menu; Present = [1]";
CM_ SG_ 947 VC_PRK_AST_CSO "Park assist customer settings menu";
CM_ SG_ 947 VC_PRK_AST_BRK_CSO "Park assist brake customer settings menu; Present = [1]";
CM_ SG_ 947 VC_PRESSURE_CSO "Pressure unit customer settings menu; Present = [1]";
CM_ SG_ 947 VC_POWER_CSO "Power unit customer settings menu; Present = [1]";
CM_ SG_ 947 VC_POLICE_PE_CSO "Police passive entry settings menu; Present = [1]";
CM_ SG_ 947 VC_PLG_CHM_CSO "Power liftgate chime customer settings menu; Present = [1]";
CM_ SG_ 947 VC_PER_SHFT_RPM_CSO "Performance shift rpm customer settings menu; Present = [1]";
CM_ SG_ 947 VC_PER_SHFT_ENBL_CSO "Performance shift enable customer settings menu; Present = [1]";
CM_ SG_ 947 VC_PE_CSO "Passive entry customer settings menu; Present = [1]";
CM_ SG_ 947 VC_NAV_TRN_CSO "Nav turn by turn customer settings menu; Present = [1]";
CM_ SG_ 947 VC_LGHT_RMT_LWR_CSO "Flash lights with remote lower customer settings menu; Present = [1]";
CM_ SG_ 947 VC_LDW_WRN_CSO "Lane departure warning customer settings menu; Present = [1]";
CM_ SG_ 947 VC_LDW_TRQ_CSO "Lane departure torque customer settings menu; Present = [1]";
CM_ SG_ 947 VC_ILL_APPRCH_CSO "Illuminated approach customer settings menu; Present = [1]";
CM_ SG_ 947 VC_HSA_CSO "Hill start assist customer settings menu; Present = [1]";
CM_ SG_ 947 VC_HRN_RMT_ST_CSO "Sound horn with remote start customer settings menu; Present = [1]";
CM_ SG_ 947 VC_HRN_RMT_LWR_CSO "Sound horn with remote lower customer settings menu; Present = [1]";
CM_ SG_ 947 VC_HRN_RMT_LK_CSO "Sound horn with remote lock customer settings menu";
CM_ SG_ 947 VC_HL_WPR_CSO "Headlamps on with wiper customer settings menu; Present = [1]";
CM_ SG_ 947 VC_HL_OFF_DLY_CSO "Headlamp off delay customer settings menu; Present = [1]";
CM_ SG_ 947 VC_HL_DRP_CSO "Headlamp drop customer settings menu; Present = [1]";
CM_ SG_ 947 VC_FLSH_LMP_LK_CSO "Flash lamps with lock customer settings menu; Present = [1]";
CM_ SG_ 947 VC_FCW_CSO "Forward collision warning customer settings menu";
CM_ SG_ 947 VC_FCW_BRK_CSO "Forward collision mitigation braking customer settings menu; Present = [1]";
CM_ SG_ 947 VC_EPS_CSO "Electric power steering customer settings menu; Present = [1]";
CM_ SG_ 947 VC_EPB_SERV_CSO "EPB service mode customer settings menu; Present = [1]";
CM_ SG_ 947 VC_ENTRY_EXIT_CSO "Auto entry exit mode customer settings menu; Present = [1]";
CM_ SG_ 947 VC_EASY_EXIT_CSO "Easy exit seat customer settings menu; Present = [1]";
CM_ SG_ 947 VC_DRL_CSO "Daytime running lights customer settings menu; Present = [1]";
CM_ SG_ 947 VC_DR_UNLK_CSO "Auto door unlock customer settings menu; Present = [1]";
CM_ SG_ 947 VC_DR_LK_CSO "Auto door lock customer settings menu; Present = [1]";
CM_ SG_ 947 VC_DISTANCE_CSO "Distance unit customer settings menu; Present = [1]";
CM_ SG_ 947 VC_DCS_CSO "Auto on driver comfort customer settings menu";
CM_ SG_ 947 VC_CONS_CSO "Consumption unit customer settings menu; Present = [1]";
CM_ SG_ 947 VC_CMRA_GRDLNS_CSO "Rear view camera gridlines customer settings menu";
CM_ SG_ 947 VC_CMP_VAR_CSO "Compass variance customer settings menu; Present = [1]";
CM_ SG_ 947 VC_CMP_CAL_CSO "Compass calibration customer settings menu; Present = [1]";
CM_ SG_ 947 VC_CLK_DSP_CSO "Clock display customer settings menu; Present = [1]";
CM_ SG_ 947 VC_CHMSL_LINE_CSO "CHMSL line menu; Present = [1]";
CM_ SG_ 947 VC_CAPACITY_CSO "Capacity unit customer settings menu; Present = [1]";
CM_ SG_ 947 VC_BLIND_SPOT_CSO "Blind spot alert customer settings menu; Present = [1]";
CM_ SG_ 947 VC_AUX_SWS_CSO "Auxiliary switches customer settings menu";
CM_ SG_ 947 VC_AUTO_PRK_CSO "Auto park customer settings menu; Present = [1]";
CM_ SG_ 947 VC_AUTO_HB_CSO "Auto high beam customer settings menu; Present = [1]";
CM_ SG_ 947 VC_AUTO_AERO_CSO "Automatic aero mode customer settings menu; Present = [1]";
CM_ SG_ 947 VC_ASCM_WRN_CSO "Air suspension warning customer settings menu; Present = [1]";
CM_ SG_ 947 VC_ASCM_TJ_CSO "Tire jack mode customer settings menu; Present = [1]";
CM_ SG_ 947 VC_AMB_DMR_CSO "Ambient dimmer customer settings menu; Present = [1]";
CM_ SG_ 947 VC_AFLS_CSO "Adaptive front light system customer settings menu; Present = [1]";
CM_ SG_ 947 VC_ACC_DLY_CSO "Power accessory delay customer settings menu; Present = [1]";
CM_ SG_ 943 B_Total_Dist_Miles "Trip B total distance in US miles";
CM_ SG_ 943 B_Total_Dist_Kilometers "Trip B total distance in kilometers";
CM_ SG_ 942 B_KMpL "Trip B Combined fuel economy in Km/L";
CM_ SG_ 942 B_Hybrid_Miles "Trip B hybrid distance in US miles";
CM_ SG_ 942 B_Hybrid_Kilometers "Trip B hybrid distance in kilometers";
CM_ SG_ 941 B_MPG "Trip B Combined fuel economy in US MPG";
CM_ SG_ 941 B_EV_Miles "Trip B EV distance in US miles";
CM_ SG_ 941 B_EV_Kilometers "Trip B EV distance in kilometers";
CM_ SG_ 940 A_Total_Dist_Miles "Trip A total distance in US miles";
CM_ SG_ 940 A_Total_Dist_Kilometers "Trip A total distance in kilometers";
CM_ SG_ 939 A_KMpL "Trip A Combined fuel economy in Km/L";
CM_ SG_ 939 A_Hybrid_Miles "Trip A hybrid distance in US miles";
CM_ SG_ 939 A_Hybrid_Kilometers "Trip A hybrid distance in kilometers";
CM_ SG_ 938 A_MPG "Trip A Combined fuel economy in US MPG";
CM_ SG_ 938 A_EV_Miles "Trip A EV distance in US miles";
CM_ SG_ 938 A_EV_Kilometers "Trip A EV distance in kilometers";
CM_ SG_ 937 SOUND_RS "Sound horn on Remote Start ; no = [0], yes = [1]";
CM_ SG_ 937 SOUND_LK_1ST_2ND "Sound horn on lock status";
CM_ SG_ 937 SOUND_LK "Sound horn on lock; no = [0], yes = [1]";
CM_ SG_ 937 ILL_APRCH_TIME "Illuminated approach time";
CM_ SG_ 937 HL_WPR "Headlamp on with wiper; no = [0], yes =[1]";
CM_ SG_ 937 HL_DLY_TIME "Headlamp delay time";
CM_ SG_ 937 FLASH_LK "Flash lamps with lock; no = [0], yes = [1]";
CM_ SG_ 937 DRL_ON "Daytime running lamps on; enabled = [1]";
CM_ SG_ 937 CFG_AUTO_WPR "Auto wiper configuration; no = [0], yes =[1]";
CM_ BO_ 924 "May not be right. Had to manually change the Pacifica DBC from 3 to 8. but pacifica can logs are DLC 8 too";
CM_ SG_ 924 MsgServPEKG "Service the Keyless System.";
CM_ SG_ 924 MsgNotInPark "Vehicle was not in Park.";
CM_ SG_ 924 MsgKG2 "Place holder for future.";
CM_ SG_ 924 MsgKG1 "Place holder for future.";
CM_ SG_ 924 MsgFobNotFnd "FOB Not Detected.";
CM_ SG_ 924 MsgFobBattLow "Indicates battery low on FOBIK last used for RKE purposes";
CM_ SG_ 924 FOBinTRUNK "FOB is in zone trunk";
CM_ SG_ 924 FOBinINT "FOB is in zone interior";
CM_ SG_ 924 FOB_SrchRslt "FOB search result";
CM_ SG_ 924 FOB_SrchFLT "FOB search fault";
CM_ SG_ 924 FOB_ExtRT "FOB is in zone exterior right";
CM_ SG_ 924 FOB_ExtRR "FOB is in zone exterior rear";
CM_ SG_ 924 FOB_ExtLT "FOB is in zone exterior left";
CM_ BO_ 906 "Tx Rate: 1882ms, Std Dev: 485.1ms";
CM_ SG_ 897 VC_VehCfg7_Stat "Configuration messages status 7";
CM_ SG_ 897 VC_TSBM_Prsnt "TSBM LIN slave is present; True = [1]";
CM_ SG_ 897 VC_TrnsDrvMdPrsnt "Transmission drive mode feature; present = [1]";
CM_ SG_ 897 VC_TransType "Automatic transmission type";
CM_ SG_ 897 VC_Trans_N_Hold_Prsnt "Transmission neutral hold feature; present = [1]";
CM_ SG_ 897 VC_Trans_Equipped "Transmission equipped: 0 = Automatic & 1 = Manual";
CM_ SG_ 897 VC_TPMS_Configuration "TPMS configuration";
CM_ SG_ 897 VC_TeenKey "TeenKey feature is present; Present = [1]";
CM_ SG_ 897 VC_SVC_Prsnt "Surround view camera; present = [1]";
CM_ SG_ 897 VC_SuspPrsnt "NetCfg_ASCM contains suspension; present = [1]";
CM_ SG_ 897 VC_SUNR_Prsnt "Sunroof is present; True = 1";
CM_ SG_ 897 VC_STP_PRSNT "Super trac pack present; True = [1]";
CM_ SG_ 897 VC_RedKey "RedKey feature is present; Present = [1]";
CM_ SG_ 897 VC_PdlsMdPrsnt "Paddles lock-out feature; present = [1]";
CM_ SG_ 897 VC_PBTyp "Park brake type";
CM_ SG_ 897 VC_LDW "Lane Departure Warning present; present = [1]";
CM_ SG_ 897 VC_HybridType "Identify the kind of hybrid vehicle";
CM_ SG_ 897 VC_FullSpeedRange_FCW "Full speed range forward collision warning plus system present; Present = 1";
CM_ SG_ 897 VC_eShifter_Prsnt "e-shifter present; present = [1]";
CM_ SG_ 897 VC_DST_Present "Dynamic steering torque present; True = [1]";
CM_ SG_ 897 VC_DampingPrsnt "NetCfg_ASCM contains active damping; present = [1]";
CM_ SG_ 897 VC_AxleLockerPrsnt "Axle locker configuration";
CM_ SG_ 897 VC_AS_ERS "Shift feature autostick / electronic range select status";
CM_ SG_ 897 VC_ACC_Type "Type of adaptive cruise control (ACC) system present";
CM_ SG_ 897 VC_ABSM "Active Blind Spot present; present = [1]";
CM_ SG_ 882 TorqueUnit "Torque units; Foot Pounds (ft-lb) = [1]";
CM_ SG_ 882 TemperatureUnit "Temperature units; Farenheit = [1]";
CM_ SG_ 882 SpeedUnit "Speed (speedometer) units; Miles = [1]";
CM_ SG_ 882 RDY_DRV_STAT_CSO "Ready to drive popup status enable/disable; Disabled = [1]";
CM_ SG_ 882 PressureUnit "Pressure units";
CM_ SG_ 882 PowerUnit "Power units";
CM_ SG_ 882 LANG_C "Language preference (5 bit)";
CM_ SG_ 882 DistanceUnit "Distance (odometer) units; Miles = [1]";
CM_ SG_ 882 ConsumptionUnit "Fuel consumption units";
CM_ SG_ 882 CapacityUnit "Fuel capacity units";
BA_DEF_ SG_  "GenSigTimeout_CBC" INT 0 65535;
BA_DEF_ SG_  "GenSigTimeout_EPS" INT 0 65535;
BA_DEF_ SG_  "GenSigTimeout_ESM" INT 0 65535;
BA_DEF_ SG_  "GenSigTimeout_ETM" INT 0 65535;
BA_DEF_ SG_  "GenSigTimeout_HaLF" INT 0 65535;
BA_DEF_ SG_  "GenSigTimeout_IC" INT 0 65535;
BA_DEF_ SG_  "GenSigTimeout_OCM" INT 0 65535;
BA_DEF_ SG_  "GenSigTimeout_ORC" INT 0 65535;
BA_DEF_ SG_  "GenSigTimeout_PTS" INT 0 65535;
BA_DEF_ SG_  "GenSigTimeout_RF_HUB" INT 0 65535;
BA_DEF_ SG_  "GenSigTimeout_SCCM" INT 0 65535;
BA_DEF_ BO_  "GenMsgStartValue" STRING ;
BA_DEF_ SG_  "GenSigSNA" STRING ;
BA_DEF_ SG_  "RID" STRING ;
BA_DEF_ SG_  "FlexKomIsMotorola" ENUM  "nein","ja";
BA_DEF_ SG_  "FlexKomSigLaenge" INT 0 64;
BA_DEF_ SG_  "FlexKomSigStartPos" INT 0 63;
BA_DEF_ SG_  "FlexKomComment" STRING ;
BA_DEF_ SG_  "FlexKomSigName" STRING ;
BA_DEF_ SG_  "FlexKomSID" INT 0 2147483647;
BA_DEF_ SG_  "GenSigStartValue" HEX 0 -1;
BA_DEF_ SG_  "FlexKomSigStartValue" STRING ;
BA_DEF_ SG_  "GenSigCycleTime" INT 0 65535;
BA_DEF_ SG_  "GenSigSendType" ENUM  "cyclicX","spontanX","cyclicIfActiveX","spontanWithDelay","cyclicAndSpontanX","cyclicAndSpontanWithDelay","spontanWithRepitition","cyclicIfActiveAndSpontanWD","cyclicIfActiveFast","cyclicWithRepeatOnDemand","none";
BA_DEF_ BO_  "GenMsgNrOfRepetitions" INT 0 65535;
BA_DEF_ BO_  "GenMsgDelayTime" INT 0 65535;
BA_DEF_ BO_  "GenMsgStartDelayTime" INT 0 65535;
BA_DEF_ BO_  "GenMsgCycleTime" INT 0 65535;
BA_DEF_ BO_  "GenMsgSendType" ENUM  "cyclicX","spontanX","cyclicIfActiveX","spontanWithDelay","cyclicAndSpontanX","cyclicAndSpontanWithDelay","spontanWithRepitition","cyclicIfActiveAndSpontanWD","cyclicIfActiveFast","cyclicWithRepeatOnDemand","none";
BA_DEF_ BO_  "DiagResponse" ENUM  "nein","ja";
BA_DEF_ BO_  "DiagRequest" ENUM  "nein","ja";
BA_DEF_ BO_  "DiagState" ENUM  "nein","ja";
BA_DEF_ BO_  "App-Botschaft" ENUM  "nein","ja";
BA_DEF_ BO_  "NWM-Botschaft" ENUM  "nein","ja";
BA_DEF_DEF_  "GenSigTimeout_CBC" 0;
BA_DEF_DEF_  "GenSigTimeout_EPS" 0;
BA_DEF_DEF_  "GenSigTimeout_ESM" 0;
BA_DEF_DEF_  "GenSigTimeout_ETM" 0;
BA_DEF_DEF_  "GenSigTimeout_HaLF" 0;
BA_DEF_DEF_  "GenSigTimeout_IC" 0;
BA_DEF_DEF_  "GenSigTimeout_OCM" 0;
BA_DEF_DEF_  "GenSigTimeout_ORC" 0;
BA_DEF_DEF_  "GenSigTimeout_PTS" 0;
BA_DEF_DEF_  "GenSigTimeout_RF_HUB" 0;
BA_DEF_DEF_  "GenSigTimeout_SCCM" 0;
BA_DEF_DEF_  "GenMsgStartValue" "";
BA_DEF_DEF_  "GenSigSNA" "";
BA_DEF_DEF_  "RID" "";
BA_DEF_DEF_  "FlexKomIsMotorola" "nein";
BA_DEF_DEF_  "FlexKomSigLaenge" 0;
BA_DEF_DEF_  "FlexKomSigStartPos" 0;
BA_DEF_DEF_  "FlexKomComment" "";
BA_DEF_DEF_  "FlexKomSigName" "";
BA_DEF_DEF_  "FlexKomSID" 0;
BA_DEF_DEF_  "GenSigStartValue" 0;
BA_DEF_DEF_  "FlexKomSigStartValue" "";
BA_DEF_DEF_  "GenSigCycleTime" 0;
BA_DEF_DEF_  "GenSigSendType" "cyclicX";
BA_DEF_DEF_  "GenMsgNrOfRepetitions" 0;
BA_DEF_DEF_  "GenMsgDelayTime" 0;
BA_DEF_DEF_  "GenMsgStartDelayTime" 0;
BA_DEF_DEF_  "GenMsgCycleTime" 0;
BA_DEF_DEF_  "GenMsgSendType" "cyclicX";
BA_DEF_DEF_  "DiagResponse" "nein";
BA_DEF_DEF_  "DiagRequest" "nein";
BA_DEF_DEF_  "DiagState" "nein";
BA_DEF_DEF_  "App-Botschaft" "nein";
BA_DEF_DEF_  "NWM-Botschaft" "nein";
BA_ "GenMsgStartValue" BO_ 993 "FFEFE7E71F0000h";
BA_ "GenMsgNrOfRepetitions" BO_ 993 2;
BA_ "GenMsgDelayTime" BO_ 993 20;
BA_ "GenMsgCycleTime" BO_ 993 100;
BA_ "GenSigSNA" SG_ 993 TRANS_TYPE "0h";
BA_ "FlexKomIsMotorola" SG_ 993 TRANS_TYPE 1;
BA_ "FlexKomComment" SG_ 993 TRANS_TYPE "Engine Configuration Information";
BA_ "FlexKomSigName" SG_ 993 TRANS_TYPE "ENG_CFG";
BA_ "FlexKomSigLaenge" SG_ 993 TRANS_TYPE 32;
BA_ "FlexKomSigStartPos" SG_ 993 TRANS_TYPE 7;
BA_ "FlexKomSID" SG_ 993 TRANS_TYPE 617;
BA_ "GenSigTimeout_ORC" SG_ 993 TRANS_TYPE 350;
BA_ "GenSigTimeout_IC" SG_ 993 TRANS_TYPE 1050;
BA_ "FlexKomSigStartValue" SG_ 993 TRANS_TYPE "FFEFE7E7h";
BA_ "GenSigCycleTime" SG_ 993 TRANS_TYPE 100;
BA_ "GenSigSNA" SG_ 993 SpStPrsnt "0h";
BA_ "FlexKomIsMotorola" SG_ 993 SpStPrsnt 1;
BA_ "FlexKomComment" SG_ 993 SpStPrsnt "Engine Configuration Information";
BA_ "FlexKomSigName" SG_ 993 SpStPrsnt "ENG_CFG";
BA_ "FlexKomSigLaenge" SG_ 993 SpStPrsnt 32;
BA_ "FlexKomSigStartPos" SG_ 993 SpStPrsnt 7;
BA_ "FlexKomSID" SG_ 993 SpStPrsnt 617;
BA_ "GenSigTimeout_ORC" SG_ 993 SpStPrsnt 350;
BA_ "GenSigTimeout_EPS" SG_ 993 SpStPrsnt 1050;
BA_ "GenSigTimeout_IC" SG_ 993 SpStPrsnt 1050;
BA_ "FlexKomSigStartValue" SG_ 993 SpStPrsnt "FFEFE7E7h";
BA_ "GenSigCycleTime" SG_ 993 SpStPrsnt 100;
BA_ "GenSigSNA" SG_ 993 NUM_VALVE "7h";
BA_ "FlexKomIsMotorola" SG_ 993 NUM_VALVE 1;
BA_ "FlexKomComment" SG_ 993 NUM_VALVE "Engine Configuration Information";
BA_ "FlexKomSigName" SG_ 993 NUM_VALVE "ENG_CFG";
BA_ "FlexKomSigLaenge" SG_ 993 NUM_VALVE 32;
BA_ "FlexKomSigStartPos" SG_ 993 NUM_VALVE 7;
BA_ "FlexKomSID" SG_ 993 NUM_VALVE 617;
BA_ "GenSigStartValue" SG_ 993 NUM_VALVE 7;
BA_ "FlexKomSigStartValue" SG_ 993 NUM_VALVE "FFEFE7E7h";
BA_ "GenSigCycleTime" SG_ 993 NUM_VALVE 100;
BA_ "GenSigSNA" SG_ 993 NUM_CYL "Fh";
BA_ "FlexKomIsMotorola" SG_ 993 NUM_CYL 1;
BA_ "FlexKomComment" SG_ 993 NUM_CYL "Engine Configuration Information";
BA_ "FlexKomSigName" SG_ 993 NUM_CYL "ENG_CFG";
BA_ "FlexKomSigLaenge" SG_ 993 NUM_CYL 32;
BA_ "FlexKomSigStartPos" SG_ 993 NUM_CYL 7;
BA_ "FlexKomSID" SG_ 993 NUM_CYL 617;
BA_ "GenSigStartValue" SG_ 993 NUM_CYL 15;
BA_ "FlexKomSigStartValue" SG_ 993 NUM_CYL "FFEFE7E7h";
BA_ "GenSigCycleTime" SG_ 993 NUM_CYL 100;
BA_ "GenSigSNA" SG_ 993 Manufacture "7h";
BA_ "FlexKomIsMotorola" SG_ 993 Manufacture 1;
BA_ "FlexKomComment" SG_ 993 Manufacture "Engine Configuration Information";
BA_ "FlexKomSigName" SG_ 993 Manufacture "ENG_CFG";
BA_ "FlexKomSigLaenge" SG_ 993 Manufacture 32;
BA_ "FlexKomSigStartPos" SG_ 993 Manufacture 7;
BA_ "FlexKomSID" SG_ 993 Manufacture 617;
BA_ "GenSigStartValue" SG_ 993 Manufacture 7;
BA_ "FlexKomSigStartValue" SG_ 993 Manufacture "FFEFE7E7h";
BA_ "GenSigCycleTime" SG_ 993 Manufacture 100;
BA_ "GenSigSNA" SG_ 993 FUEL_TYPE "7h";
BA_ "FlexKomIsMotorola" SG_ 993 FUEL_TYPE 1;
BA_ "FlexKomComment" SG_ 993 FUEL_TYPE "Engine Configuration Information";
BA_ "FlexKomSigName" SG_ 993 FUEL_TYPE "ENG_CFG";
BA_ "FlexKomSigLaenge" SG_ 993 FUEL_TYPE 32;
BA_ "FlexKomSigStartPos" SG_ 993 FUEL_TYPE 7;
BA_ "FlexKomSID" SG_ 993 FUEL_TYPE 617;
BA_ "GenSigTimeout_ORC" SG_ 993 FUEL_TYPE 350;
BA_ "GenSigTimeout_IC" SG_ 993 FUEL_TYPE 1050;
BA_ "GenSigTimeout_CBC" SG_ 993 FUEL_TYPE 1050;
BA_ "GenSigStartValue" SG_ 993 FUEL_TYPE 7;
BA_ "FlexKomSigStartValue" SG_ 993 FUEL_TYPE "FFEFE7E7h";
BA_ "GenSigCycleTime" SG_ 993 FUEL_TYPE 100;
BA_ "GenSigSNA" SG_ 993 ETC_PRSNT "0h";
BA_ "FlexKomIsMotorola" SG_ 993 ETC_PRSNT 1;
BA_ "FlexKomComment" SG_ 993 ETC_PRSNT "Engine Configuration Information";
BA_ "FlexKomSigName" SG_ 993 ETC_PRSNT "ENG_CFG";
BA_ "FlexKomSigLaenge" SG_ 993 ETC_PRSNT 32;
BA_ "FlexKomSigStartPos" SG_ 993 ETC_PRSNT 7;
BA_ "FlexKomSID" SG_ 993 ETC_PRSNT 617;
BA_ "GenSigTimeout_IC" SG_ 993 ETC_PRSNT 1050;
BA_ "FlexKomSigStartValue" SG_ 993 ETC_PRSNT "FFEFE7E7h";
BA_ "GenSigCycleTime" SG_ 993 ETC_PRSNT 100;
BA_ "GenSigSNA" SG_ 993 EngStyle "7h";
BA_ "FlexKomIsMotorola" SG_ 993 EngStyle 1;
BA_ "FlexKomComment" SG_ 993 EngStyle "Engine Configuration Information";
BA_ "FlexKomSigName" SG_ 993 EngStyle "ENG_CFG";
BA_ "FlexKomSigLaenge" SG_ 993 EngStyle 32;
BA_ "FlexKomSigStartPos" SG_ 993 EngStyle 7;
BA_ "FlexKomSID" SG_ 993 EngStyle 617;
BA_ "GenSigTimeout_CBC" SG_ 993 EngStyle 1050;
BA_ "GenSigStartValue" SG_ 993 EngStyle 7;
BA_ "FlexKomSigStartValue" SG_ 993 EngStyle "FFEFE7E7h";
BA_ "GenSigCycleTime" SG_ 993 EngStyle 100;
BA_ "GenSigSNA" SG_ 993 ENG_ASP "7h";
BA_ "FlexKomIsMotorola" SG_ 993 ENG_ASP 1;
BA_ "FlexKomComment" SG_ 993 ENG_ASP "Engine Configuration Information";
BA_ "FlexKomSigName" SG_ 993 ENG_ASP "ENG_CFG";
BA_ "FlexKomSigLaenge" SG_ 993 ENG_ASP 32;
BA_ "FlexKomSigStartPos" SG_ 993 ENG_ASP 7;
BA_ "FlexKomSID" SG_ 993 ENG_ASP 617;
BA_ "GenSigTimeout_ETM" SG_ 993 ENG_ASP 1050;
BA_ "GenSigStartValue" SG_ 993 ENG_ASP 7;
BA_ "FlexKomSigStartValue" SG_ 993 ENG_ASP "FFEFE7E7h";
BA_ "GenSigCycleTime" SG_ 993 ENG_ASP 100;
BA_ "GenSigSNA" SG_ 993 ECM_Vehi_Type "3h";
BA_ "FlexKomIsMotorola" SG_ 993 ECM_Vehi_Type 1;
BA_ "FlexKomComment" SG_ 993 ECM_Vehi_Type "Engine Configuration Information";
BA_ "FlexKomSigName" SG_ 993 ECM_Vehi_Type "ENG_CFG";
BA_ "FlexKomSigLaenge" SG_ 993 ECM_Vehi_Type 32;
BA_ "FlexKomSigStartPos" SG_ 993 ECM_Vehi_Type 7;
BA_ "FlexKomSID" SG_ 993 ECM_Vehi_Type 617;
BA_ "GenSigTimeout_IC" SG_ 993 ECM_Vehi_Type 1050;
BA_ "FlexKomSigStartValue" SG_ 993 ECM_Vehi_Type "FFEFE7E7h";
BA_ "GenSigCycleTime" SG_ 993 ECM_Vehi_Type 100;
BA_ "GenSigSNA" SG_ 993 DISPLACEMENT "FFh";
BA_ "FlexKomIsMotorola" SG_ 993 DISPLACEMENT 1;
BA_ "FlexKomComment" SG_ 993 DISPLACEMENT "Engine Configuration Information";
BA_ "FlexKomSigName" SG_ 993 DISPLACEMENT "ENG_CFG";
BA_ "FlexKomSigLaenge" SG_ 993 DISPLACEMENT 32;
BA_ "FlexKomSigStartPos" SG_ 993 DISPLACEMENT 7;
BA_ "FlexKomSID" SG_ 993 DISPLACEMENT 617;
BA_ "GenSigTimeout_ETM" SG_ 993 DISPLACEMENT 1050;
BA_ "GenSigTimeout_ORC" SG_ 993 DISPLACEMENT 350;
BA_ "GenSigTimeout_EPS" SG_ 993 DISPLACEMENT 1050;
BA_ "GenSigTimeout_IC" SG_ 993 DISPLACEMENT 1050;
BA_ "GenSigTimeout_CBC" SG_ 993 DISPLACEMENT 1050;
BA_ "GenSigStartValue" SG_ 993 DISPLACEMENT 255;
BA_ "FlexKomSigStartValue" SG_ 993 DISPLACEMENT "FFEFE7E7h";
BA_ "GenSigCycleTime" SG_ 993 DISPLACEMENT 100;
BA_ "GenMsgStartValue" BO_ 992 "0300000000000000h";
BA_ "GenMsgNrOfRepetitions" BO_ 992 2;
BA_ "GenMsgDelayTime" BO_ 992 20;
BA_ "GenMsgCycleTime" BO_ 992 100;
BA_ "GenSigSNA" SG_ 992 VIN_MSG "3h";
BA_ "FlexKomIsMotorola" SG_ 992 VIN_MSG 1;
BA_ "FlexKomComment" SG_ 992 VIN_MSG "Vin Information";
BA_ "FlexKomSigName" SG_ 992 VIN_MSG "VIN_INFO";
BA_ "FlexKomSigLaenge" SG_ 992 VIN_MSG 64;
BA_ "FlexKomSigStartPos" SG_ 992 VIN_MSG 7;
BA_ "FlexKomSID" SG_ 992 VIN_MSG 430;
BA_ "GenSigTimeout_OCM" SG_ 992 VIN_MSG 5050;
BA_ "GenSigTimeout_ORC" SG_ 992 VIN_MSG 350;
BA_ "GenSigTimeout_ESM" SG_ 992 VIN_MSG 1050;
BA_ "GenSigTimeout_SCCM" SG_ 992 VIN_MSG 1050;
BA_ "GenSigTimeout_EPS" SG_ 992 VIN_MSG 1050;
BA_ "GenSigTimeout_IC" SG_ 992 VIN_MSG 1050;
BA_ "GenSigTimeout_RF_HUB" SG_ 992 VIN_MSG 1050;
BA_ "GenSigStartValue" SG_ 992 VIN_MSG 3;
BA_ "FlexKomSigStartValue" SG_ 992 VIN_MSG "0300000000000000h";
BA_ "GenSigCycleTime" SG_ 992 VIN_MSG 100;
BA_ "GenSigSNA" SG_ 992 VIN_DATA "0h";
BA_ "FlexKomIsMotorola" SG_ 992 VIN_DATA 1;
BA_ "FlexKomComment" SG_ 992 VIN_DATA "Vin Information";
BA_ "FlexKomSigName" SG_ 992 VIN_DATA "VIN_INFO";
BA_ "FlexKomSigLaenge" SG_ 992 VIN_DATA 64;
BA_ "FlexKomSigStartPos" SG_ 992 VIN_DATA 7;
BA_ "FlexKomSID" SG_ 992 VIN_DATA 430;
BA_ "GenSigTimeout_OCM" SG_ 992 VIN_DATA 5050;
BA_ "GenSigTimeout_ORC" SG_ 992 VIN_DATA 350;
BA_ "GenSigTimeout_ESM" SG_ 992 VIN_DATA 1050;
BA_ "GenSigTimeout_SCCM" SG_ 992 VIN_DATA 1050;
BA_ "GenSigTimeout_EPS" SG_ 992 VIN_DATA 1050;
BA_ "GenSigTimeout_IC" SG_ 992 VIN_DATA 1050;
BA_ "FlexKomSigStartValue" SG_ 992 VIN_DATA "0300000000000000h";
BA_ "GenSigCycleTime" SG_ 992 VIN_DATA 100;
BA_ "GenMsgStartDelayTime" BO_ 984 90;
BA_ "GenMsgStartValue" BO_ 984 "0300000000000000h";
BA_ "GenMsgNrOfRepetitions" BO_ 984 2;
BA_ "GenMsgDelayTime" BO_ 984 20;
BA_ "GenMsgCycleTime" BO_ 984 2000;
BA_ "GenSigSNA" SG_ 984 EC_ITM "0h";
BA_ "FlexKomIsMotorola" SG_ 984 EC_ITM 1;
BA_ "FlexKomComment" SG_ 984 EC_ITM "ITM ecu configuration";
BA_ "FlexKomSigName" SG_ 984 EC_ITM "EC_ITM";
BA_ "FlexKomSigLaenge" SG_ 984 EC_ITM 16;
BA_ "FlexKomSigStartPos" SG_ 984 EC_ITM 55;
BA_ "FlexKomSID" SG_ 984 EC_ITM 1219;
BA_ "FlexKomSigStartValue" SG_ 984 EC_ITM "0000h";
BA_ "GenSigCycleTime" SG_ 984 EC_ITM 2000;
BA_ "GenSigSNA" SG_ 984 EC_ECUCfg9_Stat "3h";
BA_ "FlexKomIsMotorola" SG_ 984 EC_ECUCfg9_Stat 1;
BA_ "FlexKomComment" SG_ 984 EC_ECUCfg9_Stat "ECU Configuration messages status 9";
BA_ "FlexKomSigName" SG_ 984 EC_ECUCfg9_Stat "EC_ECUCfg9_Stat";
BA_ "FlexKomSigLaenge" SG_ 984 EC_ECUCfg9_Stat 2;
BA_ "FlexKomSigStartPos" SG_ 984 EC_ECUCfg9_Stat 1;
BA_ "FlexKomSID" SG_ 984 EC_ECUCfg9_Stat 1215;
BA_ "GenSigStartValue" SG_ 984 EC_ECUCfg9_Stat 3;
BA_ "FlexKomSigStartValue" SG_ 984 EC_ECUCfg9_Stat "03h";
BA_ "GenSigCycleTime" SG_ 984 EC_ECUCfg9_Stat 2000;
BA_ "GenSigSNA" SG_ 984 EC_CBC9B "0h";
BA_ "FlexKomIsMotorola" SG_ 984 EC_CBC9B 1;
BA_ "FlexKomComment" SG_ 984 EC_CBC9B "CBC configuration 9B";
BA_ "FlexKomSigName" SG_ 984 EC_CBC9B "EC_CBC9B";
BA_ "FlexKomSigLaenge" SG_ 984 EC_CBC9B 16;
BA_ "FlexKomSigStartPos" SG_ 984 EC_CBC9B 39;
BA_ "FlexKomSID" SG_ 984 EC_CBC9B 1422;
BA_ "FlexKomSigStartValue" SG_ 984 EC_CBC9B "0000h";
BA_ "GenSigCycleTime" SG_ 984 EC_CBC9B 2000;
BA_ "GenSigSNA" SG_ 984 EC_CBC9A2 "0h";
BA_ "FlexKomIsMotorola" SG_ 984 EC_CBC9A2 1;
BA_ "FlexKomComment" SG_ 984 EC_CBC9A2 "CBC configuration 9A";
BA_ "FlexKomSigName" SG_ 984 EC_CBC9A2 "EC_CBC9A";
BA_ "FlexKomSigLaenge" SG_ 984 EC_CBC9A2 32;
BA_ "FlexKomSigStartPos" SG_ 984 EC_CBC9A2 7;
BA_ "FlexKomSID" SG_ 984 EC_CBC9A2 1421;
BA_ "FlexKomSigStartValue" SG_ 984 EC_CBC9A2 "00000000h";
BA_ "GenSigCycleTime" SG_ 984 EC_CBC9A2 2000;
BA_ "GenSigSNA" SG_ 984 EC_CBC9A1 "0h";
BA_ "FlexKomIsMotorola" SG_ 984 EC_CBC9A1 1;
BA_ "FlexKomComment" SG_ 984 EC_CBC9A1 "CBC configuration 9A";
BA_ "FlexKomSigName" SG_ 984 EC_CBC9A1 "EC_CBC9A";
BA_ "FlexKomSigLaenge" SG_ 984 EC_CBC9A1 32;
BA_ "FlexKomSigStartPos" SG_ 984 EC_CBC9A1 7;
BA_ "FlexKomSID" SG_ 984 EC_CBC9A1 1421;
BA_ "FlexKomSigStartValue" SG_ 984 EC_CBC9A1 "00000000h";
BA_ "GenSigCycleTime" SG_ 984 EC_CBC9A1 2000;
BA_ "GenMsgStartDelayTime" BO_ 983 100;
BA_ "GenMsgStartValue" BO_ 983 "0300000000000000h";
BA_ "GenMsgNrOfRepetitions" BO_ 983 2;
BA_ "GenMsgDelayTime" BO_ 983 20;
BA_ "GenMsgCycleTime" BO_ 983 2000;
BA_ "GenMsgSendType" BO_ 983 5;
BA_ "GenSigSNA" SG_ 983 EC_ECUCfg10_Stat "3h";
BA_ "FlexKomIsMotorola" SG_ 983 EC_ECUCfg10_Stat 1;
BA_ "FlexKomComment" SG_ 983 EC_ECUCfg10_Stat "ECU Configuration messages status 10";
BA_ "FlexKomSigName" SG_ 983 EC_ECUCfg10_Stat "EC_ECUCfg10_Stat";
BA_ "FlexKomSigLaenge" SG_ 983 EC_ECUCfg10_Stat 2;
BA_ "FlexKomSigStartPos" SG_ 983 EC_ECUCfg10_Stat 1;
BA_ "FlexKomSID" SG_ 983 EC_ECUCfg10_Stat 1303;
BA_ "GenSigTimeout_IC" SG_ 983 EC_ECUCfg10_Stat 21000;
BA_ "GenSigStartValue" SG_ 983 EC_ECUCfg10_Stat 3;
BA_ "FlexKomSigStartValue" SG_ 983 EC_ECUCfg10_Stat "03h";
BA_ "GenSigCycleTime" SG_ 983 EC_ECUCfg10_Stat 2000;
BA_ "GenSigSendType" SG_ 983 EC_ECUCfg10_Stat 5;
BA_ "GenSigSNA" SG_ 983 EC_Cluster4 "0h";
BA_ "FlexKomIsMotorola" SG_ 983 EC_Cluster4 1;
BA_ "FlexKomComment" SG_ 983 EC_Cluster4 "Instrument cluster ecu configuration 4";
BA_ "FlexKomSigName" SG_ 983 EC_Cluster4 "EC_Cluster4";
BA_ "FlexKomSigLaenge" SG_ 983 EC_Cluster4 32;
BA_ "FlexKomSigStartPos" SG_ 983 EC_Cluster4 39;
BA_ "FlexKomSID" SG_ 983 EC_Cluster4 1306;
BA_ "GenSigTimeout_IC" SG_ 983 EC_Cluster4 21000;
BA_ "FlexKomSigStartValue" SG_ 983 EC_Cluster4 "00000000h";
BA_ "GenSigCycleTime" SG_ 983 EC_Cluster4 2000;
BA_ "GenSigSendType" SG_ 983 EC_Cluster4 5;
BA_ "GenSigSNA" SG_ 983 EC_Cluster3B "0h";
BA_ "FlexKomIsMotorola" SG_ 983 EC_Cluster3B 1;
BA_ "FlexKomComment" SG_ 983 EC_Cluster3B "Instrument cluster ecu configuration 3";
BA_ "FlexKomSigName" SG_ 983 EC_Cluster3B "EC_Cluster3";
BA_ "FlexKomSigLaenge" SG_ 983 EC_Cluster3B 32;
BA_ "FlexKomSigStartPos" SG_ 983 EC_Cluster3B 7;
BA_ "FlexKomSID" SG_ 983 EC_Cluster3B 1307;
BA_ "GenSigTimeout_IC" SG_ 983 EC_Cluster3B 21000;
BA_ "FlexKomSigStartValue" SG_ 983 EC_Cluster3B "00000000h";
BA_ "GenSigCycleTime" SG_ 983 EC_Cluster3B 2000;
BA_ "GenSigSendType" SG_ 983 EC_Cluster3B 5;
BA_ "GenSigSNA" SG_ 983 EC_Cluster3A "0h";
BA_ "FlexKomIsMotorola" SG_ 983 EC_Cluster3A 1;
BA_ "FlexKomComment" SG_ 983 EC_Cluster3A "Instrument cluster ecu configuration 3";
BA_ "FlexKomSigName" SG_ 983 EC_Cluster3A "EC_Cluster3";
BA_ "FlexKomSigLaenge" SG_ 983 EC_Cluster3A 32;
BA_ "FlexKomSigStartPos" SG_ 983 EC_Cluster3A 7;
BA_ "FlexKomSID" SG_ 983 EC_Cluster3A 1307;
BA_ "GenSigTimeout_IC" SG_ 983 EC_Cluster3A 21000;
BA_ "FlexKomSigStartValue" SG_ 983 EC_Cluster3A "00000000h";
BA_ "GenSigCycleTime" SG_ 983 EC_Cluster3A 2000;
BA_ "GenSigSendType" SG_ 983 EC_Cluster3A 5;
BA_ "GenMsgStartDelayTime" BO_ 982 130;
BA_ "GenMsgStartValue" BO_ 982 "0300000000000000h";
BA_ "GenMsgNrOfRepetitions" BO_ 982 2;
BA_ "GenMsgDelayTime" BO_ 982 20;
BA_ "GenMsgCycleTime" BO_ 982 2000;
BA_ "GenSigSNA" SG_ 982 EC_ECUCfg11_Stat "3h";
BA_ "FlexKomIsMotorola" SG_ 982 EC_ECUCfg11_Stat 1;
BA_ "FlexKomComment" SG_ 982 EC_ECUCfg11_Stat "ECU Configuration messages status 11";
BA_ "FlexKomSigName" SG_ 982 EC_ECUCfg11_Stat "EC_ECUCfg11_Stat";
BA_ "FlexKomSigLaenge" SG_ 982 EC_ECUCfg11_Stat 2;
BA_ "FlexKomSigStartPos" SG_ 982 EC_ECUCfg11_Stat 1;
BA_ "FlexKomSID" SG_ 982 EC_ECUCfg11_Stat 1708;
BA_ "GenSigStartValue" SG_ 982 EC_ECUCfg11_Stat 3;
BA_ "FlexKomSigStartValue" SG_ 982 EC_ECUCfg11_Stat "03h";
BA_ "GenSigCycleTime" SG_ 982 EC_ECUCfg11_Stat 2000;
BA_ "GenSigSNA" SG_ 982 EC_CBC11 "0h";
BA_ "FlexKomIsMotorola" SG_ 982 EC_CBC11 1;
BA_ "FlexKomComment" SG_ 982 EC_CBC11 "CBC ecu configuration 11";
BA_ "FlexKomSigName" SG_ 982 EC_CBC11 "EC_CBC11";
BA_ "FlexKomSigLaenge" SG_ 982 EC_CBC11 32;
BA_ "FlexKomSigStartPos" SG_ 982 EC_CBC11 39;
BA_ "FlexKomSID" SG_ 982 EC_CBC11 1710;
BA_ "FlexKomSigStartValue" SG_ 982 EC_CBC11 "00000000h";
BA_ "GenSigCycleTime" SG_ 982 EC_CBC11 2000;
BA_ "GenSigSNA" SG_ 982 EC_CBC10B "0h";
BA_ "FlexKomIsMotorola" SG_ 982 EC_CBC10B 1;
BA_ "FlexKomComment" SG_ 982 EC_CBC10B "CBC ecu configuration 10";
BA_ "FlexKomSigName" SG_ 982 EC_CBC10B "EC_CBC10";
BA_ "FlexKomSigLaenge" SG_ 982 EC_CBC10B 32;
BA_ "FlexKomSigStartPos" SG_ 982 EC_CBC10B 7;
BA_ "FlexKomSID" SG_ 982 EC_CBC10B 1709;
BA_ "FlexKomSigStartValue" SG_ 982 EC_CBC10B "00000000h";
BA_ "GenSigCycleTime" SG_ 982 EC_CBC10B 2000;
BA_ "GenSigSNA" SG_ 982 EC_CBC10A "0h";
BA_ "FlexKomIsMotorola" SG_ 982 EC_CBC10A 1;
BA_ "FlexKomComment" SG_ 982 EC_CBC10A "CBC ecu configuration 10";
BA_ "FlexKomSigName" SG_ 982 EC_CBC10A "EC_CBC10";
BA_ "FlexKomSigLaenge" SG_ 982 EC_CBC10A 32;
BA_ "FlexKomSigStartPos" SG_ 982 EC_CBC10A 7;
BA_ "FlexKomSID" SG_ 982 EC_CBC10A 1709;
BA_ "FlexKomSigStartValue" SG_ 982 EC_CBC10A "00000000h";
BA_ "GenSigCycleTime" SG_ 982 EC_CBC10A 2000;
BA_ "GenMsgStartDelayTime" BO_ 981 120;
BA_ "GenMsgStartValue" BO_ 981 "0300000000000000h";
BA_ "GenMsgNrOfRepetitions" BO_ 981 2;
BA_ "GenMsgDelayTime" BO_ 981 20;
BA_ "GenMsgCycleTime" BO_ 981 2000;
BA_ "GenMsgSendType" BO_ 981 5;
BA_ "GenSigSNA" SG_ 981 EC_ECUCfg12_Stat "3h";
BA_ "FlexKomIsMotorola" SG_ 981 EC_ECUCfg12_Stat 1;
BA_ "FlexKomComment" SG_ 981 EC_ECUCfg12_Stat "ECU Configuration messages status 12";
BA_ "FlexKomSigName" SG_ 981 EC_ECUCfg12_Stat "EC_ECUCfg12_Stat";
BA_ "FlexKomSigLaenge" SG_ 981 EC_ECUCfg12_Stat 2;
BA_ "FlexKomSigStartPos" SG_ 981 EC_ECUCfg12_Stat 1;
BA_ "FlexKomSID" SG_ 981 EC_ECUCfg12_Stat 1834;
BA_ "GenSigTimeout_IC" SG_ 981 EC_ECUCfg12_Stat 21000;
BA_ "GenSigTimeout_RF_HUB" SG_ 981 EC_ECUCfg12_Stat 21000;
BA_ "GenSigStartValue" SG_ 981 EC_ECUCfg12_Stat 3;
BA_ "FlexKomSigStartValue" SG_ 981 EC_ECUCfg12_Stat "03h";
BA_ "GenSigCycleTime" SG_ 981 EC_ECUCfg12_Stat 2000;
BA_ "GenSigSendType" SG_ 981 EC_ECUCfg12_Stat 5;
BA_ "GenSigSNA" SG_ 981 EC_Cluster5C "0h";
BA_ "FlexKomIsMotorola" SG_ 981 EC_Cluster5C 1;
BA_ "FlexKomComment" SG_ 981 EC_Cluster5C "Instrument cluster ecu configuration 5";
BA_ "FlexKomSigName" SG_ 981 EC_Cluster5C "EC_Cluster5";
BA_ "FlexKomSigLaenge" SG_ 981 EC_Cluster5C 64;
BA_ "FlexKomSigStartPos" SG_ 981 EC_Cluster5C 7;
BA_ "FlexKomSID" SG_ 981 EC_Cluster5C 1835;
BA_ "GenSigTimeout_IC" SG_ 981 EC_Cluster5C 21000;
BA_ "GenSigTimeout_RF_HUB" SG_ 981 EC_Cluster5C 21000;
BA_ "FlexKomSigStartValue" SG_ 981 EC_Cluster5C "0000000000000000h";
BA_ "GenSigCycleTime" SG_ 981 EC_Cluster5C 2000;
BA_ "GenSigSendType" SG_ 981 EC_Cluster5C 5;
BA_ "GenSigSNA" SG_ 981 EC_Cluster5B "0h";
BA_ "FlexKomIsMotorola" SG_ 981 EC_Cluster5B 1;
BA_ "FlexKomComment" SG_ 981 EC_Cluster5B "Instrument cluster ecu configuration 5";
BA_ "FlexKomSigName" SG_ 981 EC_Cluster5B "EC_Cluster5";
BA_ "FlexKomSigLaenge" SG_ 981 EC_Cluster5B 64;
BA_ "FlexKomSigStartPos" SG_ 981 EC_Cluster5B 7;
BA_ "FlexKomSID" SG_ 981 EC_Cluster5B 1835;
BA_ "GenSigTimeout_IC" SG_ 981 EC_Cluster5B 21000;
BA_ "GenSigTimeout_RF_HUB" SG_ 981 EC_Cluster5B 21000;
BA_ "FlexKomSigStartValue" SG_ 981 EC_Cluster5B "0000000000000000h";
BA_ "GenSigCycleTime" SG_ 981 EC_Cluster5B 2000;
BA_ "GenSigSendType" SG_ 981 EC_Cluster5B 5;
BA_ "GenSigSNA" SG_ 981 EC_Cluster5A "0h";
BA_ "FlexKomIsMotorola" SG_ 981 EC_Cluster5A 1;
BA_ "FlexKomComment" SG_ 981 EC_Cluster5A "Instrument cluster ecu configuration 5";
BA_ "FlexKomSigName" SG_ 981 EC_Cluster5A "EC_Cluster5";
BA_ "FlexKomSigLaenge" SG_ 981 EC_Cluster5A 64;
BA_ "FlexKomSigStartPos" SG_ 981 EC_Cluster5A 7;
BA_ "FlexKomSID" SG_ 981 EC_Cluster5A 1835;
BA_ "GenSigTimeout_IC" SG_ 981 EC_Cluster5A 21000;
BA_ "GenSigTimeout_RF_HUB" SG_ 981 EC_Cluster5A 21000;
BA_ "FlexKomSigStartValue" SG_ 981 EC_Cluster5A "0000000000000000h";
BA_ "GenSigCycleTime" SG_ 981 EC_Cluster5A 2000;
BA_ "GenSigSendType" SG_ 981 EC_Cluster5A 5;
BA_ "GenMsgStartDelayTime" BO_ 980 130;
BA_ "GenMsgStartValue" BO_ 980 "0300000000000000h";
BA_ "GenMsgNrOfRepetitions" BO_ 980 2;
BA_ "GenMsgDelayTime" BO_ 980 20;
BA_ "GenMsgCycleTime" BO_ 980 2000;
BA_ "GenSigSNA" SG_ 980 EC_ECUCfg13_Stat "3h";
BA_ "FlexKomIsMotorola" SG_ 980 EC_ECUCfg13_Stat 1;
BA_ "FlexKomComment" SG_ 980 EC_ECUCfg13_Stat "ECU Configuration messages status 13";
BA_ "FlexKomSigName" SG_ 980 EC_ECUCfg13_Stat "EC_ECUCfg13_Stat";
BA_ "FlexKomSigLaenge" SG_ 980 EC_ECUCfg13_Stat 2;
BA_ "FlexKomSigStartPos" SG_ 980 EC_ECUCfg13_Stat 1;
BA_ "FlexKomSID" SG_ 980 EC_ECUCfg13_Stat 1868;
BA_ "GenSigStartValue" SG_ 980 EC_ECUCfg13_Stat 3;
BA_ "FlexKomSigStartValue" SG_ 980 EC_ECUCfg13_Stat "03h";
BA_ "GenSigCycleTime" SG_ 980 EC_ECUCfg13_Stat 2000;
BA_ "GenSigSNA" SG_ 980 EC_CBC13B "0h";
BA_ "FlexKomIsMotorola" SG_ 980 EC_CBC13B 1;
BA_ "FlexKomComment" SG_ 980 EC_CBC13B "CBC ecu configuration 13";
BA_ "FlexKomSigName" SG_ 980 EC_CBC13B "EC_CBC13";
BA_ "FlexKomSigLaenge" SG_ 980 EC_CBC13B 64;
BA_ "FlexKomSigStartPos" SG_ 980 EC_CBC13B 7;
BA_ "FlexKomSID" SG_ 980 EC_CBC13B 1990;
BA_ "FlexKomSigStartValue" SG_ 980 EC_CBC13B "0000000000000000h";
BA_ "GenSigCycleTime" SG_ 980 EC_CBC13B 2000;
BA_ "GenSigSNA" SG_ 980 EC_CBC13A "0h";
BA_ "FlexKomIsMotorola" SG_ 980 EC_CBC13A 1;
BA_ "FlexKomComment" SG_ 980 EC_CBC13A "CBC ecu configuration 13";
BA_ "FlexKomSigName" SG_ 980 EC_CBC13A "EC_CBC13";
BA_ "FlexKomSigLaenge" SG_ 980 EC_CBC13A 64;
BA_ "FlexKomSigStartPos" SG_ 980 EC_CBC13A 7;
BA_ "FlexKomSID" SG_ 980 EC_CBC13A 1990;
BA_ "FlexKomSigStartValue" SG_ 980 EC_CBC13A "0000000000000000h";
BA_ "GenSigCycleTime" SG_ 980 EC_CBC13A 2000;
BA_ "GenMsgStartDelayTime" BO_ 979 130;
BA_ "GenMsgStartValue" BO_ 979 "0300000000000000h";
BA_ "GenMsgNrOfRepetitions" BO_ 979 2;
BA_ "GenMsgDelayTime" BO_ 979 20;
BA_ "GenMsgCycleTime" BO_ 979 2000;
BA_ "GenSigSNA" SG_ 979 EC_ECUCfg14_Stat "3h";
BA_ "FlexKomIsMotorola" SG_ 979 EC_ECUCfg14_Stat 1;
BA_ "FlexKomComment" SG_ 979 EC_ECUCfg14_Stat "ECU Configuration messages status 14";
BA_ "FlexKomSigName" SG_ 979 EC_ECUCfg14_Stat "EC_ECUCfg14_Stat";
BA_ "FlexKomSigLaenge" SG_ 979 EC_ECUCfg14_Stat 2;
BA_ "FlexKomSigStartPos" SG_ 979 EC_ECUCfg14_Stat 1;
BA_ "FlexKomSID" SG_ 979 EC_ECUCfg14_Stat 1950;
BA_ "GenSigStartValue" SG_ 979 EC_ECUCfg14_Stat 3;
BA_ "FlexKomSigStartValue" SG_ 979 EC_ECUCfg14_Stat "03h";
BA_ "GenSigCycleTime" SG_ 979 EC_ECUCfg14_Stat 2000;
BA_ "GenSigSNA" SG_ 979 EC_CBC14B "0h";
BA_ "FlexKomIsMotorola" SG_ 979 EC_CBC14B 1;
BA_ "FlexKomComment" SG_ 979 EC_CBC14B "CBC ecu configuration 14";
BA_ "FlexKomSigName" SG_ 979 EC_CBC14B "EC_CBC14";
BA_ "FlexKomSigLaenge" SG_ 979 EC_CBC14B 64;
BA_ "FlexKomSigStartPos" SG_ 979 EC_CBC14B 7;
BA_ "FlexKomSID" SG_ 979 EC_CBC14B 1951;
BA_ "FlexKomSigStartValue" SG_ 979 EC_CBC14B "0000000000000000h";
BA_ "GenSigCycleTime" SG_ 979 EC_CBC14B 2000;
BA_ "GenSigSNA" SG_ 979 EC_CBC14A "0h";
BA_ "FlexKomIsMotorola" SG_ 979 EC_CBC14A 1;
BA_ "FlexKomComment" SG_ 979 EC_CBC14A "CBC ecu configuration 14";
BA_ "FlexKomSigName" SG_ 979 EC_CBC14A "EC_CBC14";
BA_ "FlexKomSigLaenge" SG_ 979 EC_CBC14A 64;
BA_ "FlexKomSigStartPos" SG_ 979 EC_CBC14A 7;
BA_ "FlexKomSID" SG_ 979 EC_CBC14A 1951;
BA_ "FlexKomSigStartValue" SG_ 979 EC_CBC14A "0000000000000000h";
BA_ "GenSigCycleTime" SG_ 979 EC_CBC14A 2000;
BA_ "GenMsgStartDelayTime" BO_ 974 70;
BA_ "GenMsgStartValue" BO_ 974 "7F0F7F7F7Fh";
BA_ "GenMsgNrOfRepetitions" BO_ 974 2;
BA_ "GenMsgDelayTime" BO_ 974 20;
BA_ "GenMsgCycleTime" BO_ 974 1000;
BA_ "GenMsgSendType" BO_ 974 5;
BA_ "GenSigSendType" SG_ 974 PAS_TEMP_DR_POS 5;
BA_ "GenSigCycleTime" SG_ 974 PAS_TEMP_DR_POS 1000;
BA_ "FlexKomSigStartValue" SG_ 974 PAS_TEMP_DR_POS "7F0F7F7F7Fh";
BA_ "GenSigStartValue" SG_ 974 PAS_TEMP_DR_POS 127;
BA_ "FlexKomSID" SG_ 974 PAS_TEMP_DR_POS 1445;
BA_ "FlexKomSigStartPos" SG_ 974 PAS_TEMP_DR_POS 7;
BA_ "FlexKomSigLaenge" SG_ 974 PAS_TEMP_DR_POS 40;
BA_ "FlexKomSigName" SG_ 974 PAS_TEMP_DR_POS "GW_Dev";
BA_ "FlexKomIsMotorola" SG_ 974 PAS_TEMP_DR_POS 1;
BA_ "GenSigSNA" SG_ 974 PAS_TEMP_DR_POS "7Fh";
BA_ "FlexKomComment" SG_ 974 PAS_TEMP_DR_POS "Temporary development packet - route signals from ";
BA_ "GenSigSNA" SG_ 974 FT_HVAC_BLW_FN_SP "7Fh";
BA_ "FlexKomIsMotorola" SG_ 974 FT_HVAC_BLW_FN_SP 1;
BA_ "FlexKomComment" SG_ 974 FT_HVAC_BLW_FN_SP "Temporary development packet - route signals from ";
BA_ "FlexKomSigName" SG_ 974 FT_HVAC_BLW_FN_SP "GW_Dev";
BA_ "FlexKomSigLaenge" SG_ 974 FT_HVAC_BLW_FN_SP 40;
BA_ "FlexKomSigStartPos" SG_ 974 FT_HVAC_BLW_FN_SP 7;
BA_ "FlexKomSID" SG_ 974 FT_HVAC_BLW_FN_SP 1445;
BA_ "GenSigTimeout_IC" SG_ 974 FT_HVAC_BLW_FN_SP 10500;
BA_ "GenSigStartValue" SG_ 974 FT_HVAC_BLW_FN_SP 127;
BA_ "FlexKomSigStartValue" SG_ 974 FT_HVAC_BLW_FN_SP "7F0F7F7F7Fh";
BA_ "GenSigCycleTime" SG_ 974 FT_HVAC_BLW_FN_SP 1000;
BA_ "GenSigSendType" SG_ 974 FT_HVAC_BLW_FN_SP 5;
BA_ "GenSigSNA" SG_ 974 DRV_TEMP_DR_POS "7Fh";
BA_ "FlexKomIsMotorola" SG_ 974 DRV_TEMP_DR_POS 1;
BA_ "FlexKomComment" SG_ 974 DRV_TEMP_DR_POS "Temporary development packet - route signals from ";
BA_ "FlexKomSigName" SG_ 974 DRV_TEMP_DR_POS "GW_Dev";
BA_ "FlexKomSigLaenge" SG_ 974 DRV_TEMP_DR_POS 40;
BA_ "FlexKomSigStartPos" SG_ 974 DRV_TEMP_DR_POS 7;
BA_ "FlexKomSID" SG_ 974 DRV_TEMP_DR_POS 1445;
BA_ "GenSigStartValue" SG_ 974 DRV_TEMP_DR_POS 127;
BA_ "FlexKomSigStartValue" SG_ 974 DRV_TEMP_DR_POS "7F0F7F7F7Fh";
BA_ "GenSigCycleTime" SG_ 974 DRV_TEMP_DR_POS 1000;
BA_ "GenSigSendType" SG_ 974 DRV_TEMP_DR_POS 5;
BA_ "GenMsgStartValue" BO_ 969 "FFFF0000h";
BA_ "GenMsgNrOfRepetitions" BO_ 969 2;
BA_ "GenMsgDelayTime" BO_ 969 20;
BA_ "GenMsgCycleTime" BO_ 969 1000;
BA_ "GenSigSNA" SG_ 969 AMB_TEMP_AVG_F "FFh";
BA_ "FlexKomIsMotorola" SG_ 969 AMB_TEMP_AVG_F 1;
BA_ "FlexKomComment" SG_ 969 AMB_TEMP_AVG_F "Ambient temperature average - in degrees Fahrenhei";
BA_ "FlexKomSigName" SG_ 969 AMB_TEMP_AVG_F "AMB_TEMP_AVG_F";
BA_ "FlexKomSigLaenge" SG_ 969 AMB_TEMP_AVG_F 8;
BA_ "FlexKomSigStartPos" SG_ 969 AMB_TEMP_AVG_F 7;
BA_ "FlexKomSID" SG_ 969 AMB_TEMP_AVG_F 1428;
BA_ "GenSigTimeout_IC" SG_ 969 AMB_TEMP_AVG_F 10500;
BA_ "GenSigStartValue" SG_ 969 AMB_TEMP_AVG_F 255;
BA_ "FlexKomSigStartValue" SG_ 969 AMB_TEMP_AVG_F "FFh";
BA_ "GenSigCycleTime" SG_ 969 AMB_TEMP_AVG_F 1000;
BA_ "GenSigSNA" SG_ 969 AMB_TEMP_AVG_C "FFh";
BA_ "FlexKomIsMotorola" SG_ 969 AMB_TEMP_AVG_C 1;
BA_ "FlexKomComment" SG_ 969 AMB_TEMP_AVG_C "Ambient temperature average - in degrees Celsius";
BA_ "FlexKomSigName" SG_ 969 AMB_TEMP_AVG_C "AMB_TEMP_AVG_C";
BA_ "FlexKomSigLaenge" SG_ 969 AMB_TEMP_AVG_C 8;
BA_ "FlexKomSigStartPos" SG_ 969 AMB_TEMP_AVG_C 15;
BA_ "FlexKomSID" SG_ 969 AMB_TEMP_AVG_C 1427;
BA_ "GenSigTimeout_IC" SG_ 969 AMB_TEMP_AVG_C 10500;
BA_ "GenSigStartValue" SG_ 969 AMB_TEMP_AVG_C 255;
BA_ "FlexKomSigStartValue" SG_ 969 AMB_TEMP_AVG_C "FFh";
BA_ "GenSigCycleTime" SG_ 969 AMB_TEMP_AVG_C 1000;
BA_ "GenMsgStartValue" BO_ 956 "0000000000000000h";
BA_ "GenMsgNrOfRepetitions" BO_ 956 2;
BA_ "GenMsgDelayTime" BO_ 956 20;
BA_ "GenMsgCycleTime" BO_ 956 1000;
BA_ "GenMsgSendType" BO_ 956 5;
BA_ "GenSigSNA" SG_ 956 NAV_HiGrpMark "0h";
BA_ "FlexKomIsMotorola" SG_ 956 NAV_HiGrpMark 1;
BA_ "FlexKomComment" SG_ 956 NAV_HiGrpMark "Text data packet transfer from NAV";
BA_ "FlexKomSigName" SG_ 956 NAV_HiGrpMark "NAV_DATA";
BA_ "FlexKomSigLaenge" SG_ 956 NAV_HiGrpMark 64;
BA_ "FlexKomSigStartPos" SG_ 956 NAV_HiGrpMark 7;
BA_ "FlexKomSID" SG_ 956 NAV_HiGrpMark 576;
BA_ "FlexKomSigStartValue" SG_ 956 NAV_HiGrpMark "0000000000000000h";
BA_ "GenSigCycleTime" SG_ 956 NAV_HiGrpMark 1000;
BA_ "GenSigSendType" SG_ 956 NAV_HiGrpMark 5;
BA_ "GenSigSNA" SG_ 956 NAV_GrpTyp "3Fh";
BA_ "FlexKomIsMotorola" SG_ 956 NAV_GrpTyp 1;
BA_ "FlexKomComment" SG_ 956 NAV_GrpTyp "Text data packet transfer from NAV";
BA_ "FlexKomSigName" SG_ 956 NAV_GrpTyp "NAV_DATA";
BA_ "FlexKomSigLaenge" SG_ 956 NAV_GrpTyp 64;
BA_ "FlexKomSigStartPos" SG_ 956 NAV_GrpTyp 7;
BA_ "FlexKomSID" SG_ 956 NAV_GrpTyp 576;
BA_ "FlexKomSigStartValue" SG_ 956 NAV_GrpTyp "0000000000000000h";
BA_ "GenSigCycleTime" SG_ 956 NAV_GrpTyp 1000;
BA_ "GenSigSendType" SG_ 956 NAV_GrpTyp 5;
BA_ "GenSigSNA" SG_ 956 NAV_GrpNum "0h";
BA_ "FlexKomIsMotorola" SG_ 956 NAV_GrpNum 1;
BA_ "FlexKomComment" SG_ 956 NAV_GrpNum "Text data packet transfer from NAV";
BA_ "FlexKomSigName" SG_ 956 NAV_GrpNum "NAV_DATA";
BA_ "FlexKomSigLaenge" SG_ 956 NAV_GrpNum 64;
BA_ "FlexKomSigStartPos" SG_ 956 NAV_GrpNum 7;
BA_ "FlexKomSID" SG_ 956 NAV_GrpNum 576;
BA_ "FlexKomSigStartValue" SG_ 956 NAV_GrpNum "0000000000000000h";
BA_ "GenSigCycleTime" SG_ 956 NAV_GrpNum 1000;
BA_ "GenSigSendType" SG_ 956 NAV_GrpNum 5;
BA_ "GenMsgStartDelayTime" BO_ 948 70;
BA_ "GenMsgStartValue" BO_ 948 "0300000000000000h";
BA_ "GenMsgNrOfRepetitions" BO_ 948 2;
BA_ "GenMsgDelayTime" BO_ 948 20;
BA_ "GenMsgCycleTime" BO_ 948 2000;
BA_ "GenMsgSendType" BO_ 948 5;
BA_ "GenSigSNA" SG_ 948 VC_WHL_ALGN_CSO "0h";
BA_ "FlexKomIsMotorola" SG_ 948 VC_WHL_ALGN_CSO 1;
BA_ "FlexKomComment" SG_ 948 VC_WHL_ALGN_CSO "Vehicle configuration - customer settings menu 2 P";
BA_ "FlexKomSigName" SG_ 948 VC_WHL_ALGN_CSO "VehCfgCSM2_Pkt";
BA_ "FlexKomSigLaenge" SG_ 948 VC_WHL_ALGN_CSO 64;
BA_ "FlexKomSigStartPos" SG_ 948 VC_WHL_ALGN_CSO 7;
BA_ "FlexKomSID" SG_ 948 VC_WHL_ALGN_CSO 2007;
BA_ "GenSigTimeout_IC" SG_ 948 VC_WHL_ALGN_CSO 21000;
BA_ "FlexKomSigStartValue" SG_ 948 VC_WHL_ALGN_CSO "0300000000000000h";
BA_ "GenSigCycleTime" SG_ 948 VC_WHL_ALGN_CSO 2000;
BA_ "GenSigSendType" SG_ 948 VC_WHL_ALGN_CSO 5;
BA_ "GenSigSNA" SG_ 948 VC_VehCfgCSO2_Stat "3h";
BA_ "FlexKomIsMotorola" SG_ 948 VC_VehCfgCSO2_Stat 1;
BA_ "FlexKomComment" SG_ 948 VC_VehCfgCSO2_Stat "Vehicle configuration - customer settings menu 2 P";
BA_ "FlexKomSigName" SG_ 948 VC_VehCfgCSO2_Stat "VehCfgCSM2_Pkt";
BA_ "FlexKomSigLaenge" SG_ 948 VC_VehCfgCSO2_Stat 64;
BA_ "FlexKomSigStartPos" SG_ 948 VC_VehCfgCSO2_Stat 7;
BA_ "FlexKomSID" SG_ 948 VC_VehCfgCSO2_Stat 2007;
BA_ "GenSigTimeout_IC" SG_ 948 VC_VehCfgCSO2_Stat 21000;
BA_ "GenSigStartValue" SG_ 948 VC_VehCfgCSO2_Stat 3;
BA_ "FlexKomSigStartValue" SG_ 948 VC_VehCfgCSO2_Stat "0300000000000000h";
BA_ "GenSigCycleTime" SG_ 948 VC_VehCfgCSO2_Stat 2000;
BA_ "GenSigSendType" SG_ 948 VC_VehCfgCSO2_Stat 5;
BA_ "GenSigSNA" SG_ 948 VC_US_METRIC_CSO "0h";
BA_ "FlexKomIsMotorola" SG_ 948 VC_US_METRIC_CSO 1;
BA_ "FlexKomComment" SG_ 948 VC_US_METRIC_CSO "Vehicle configuration - customer settings menu 2 P";
BA_ "FlexKomSigName" SG_ 948 VC_US_METRIC_CSO "VehCfgCSM2_Pkt";
BA_ "FlexKomSigLaenge" SG_ 948 VC_US_METRIC_CSO 64;
BA_ "FlexKomSigStartPos" SG_ 948 VC_US_METRIC_CSO 7;
BA_ "FlexKomSID" SG_ 948 VC_US_METRIC_CSO 2007;
BA_ "GenSigTimeout_IC" SG_ 948 VC_US_METRIC_CSO 21000;
BA_ "FlexKomSigStartValue" SG_ 948 VC_US_METRIC_CSO "0300000000000000h";
BA_ "GenSigCycleTime" SG_ 948 VC_US_METRIC_CSO 2000;
BA_ "GenSigSendType" SG_ 948 VC_US_METRIC_CSO 5;
BA_ "GenSigSNA" SG_ 948 VC_TRNS_MD_CSO "0h";
BA_ "FlexKomIsMotorola" SG_ 948 VC_TRNS_MD_CSO 1;
BA_ "FlexKomComment" SG_ 948 VC_TRNS_MD_CSO "Vehicle configuration - customer settings menu 2 P";
BA_ "FlexKomSigName" SG_ 948 VC_TRNS_MD_CSO "VehCfgCSM2_Pkt";
BA_ "FlexKomSigLaenge" SG_ 948 VC_TRNS_MD_CSO 64;
BA_ "FlexKomSigStartPos" SG_ 948 VC_TRNS_MD_CSO 7;
BA_ "FlexKomSID" SG_ 948 VC_TRNS_MD_CSO 2007;
BA_ "GenSigTimeout_IC" SG_ 948 VC_TRNS_MD_CSO 21000;
BA_ "FlexKomSigStartValue" SG_ 948 VC_TRNS_MD_CSO "0300000000000000h";
BA_ "GenSigCycleTime" SG_ 948 VC_TRNS_MD_CSO 2000;
BA_ "GenSigSendType" SG_ 948 VC_TRNS_MD_CSO 5;
BA_ "GenSigSNA" SG_ 948 VC_TRLR_TYPE_CSO "0h";
BA_ "FlexKomIsMotorola" SG_ 948 VC_TRLR_TYPE_CSO 1;
BA_ "FlexKomComment" SG_ 948 VC_TRLR_TYPE_CSO "Vehicle configuration - customer settings menu 2 P";
BA_ "FlexKomSigName" SG_ 948 VC_TRLR_TYPE_CSO "VehCfgCSM2_Pkt";
BA_ "FlexKomSigLaenge" SG_ 948 VC_TRLR_TYPE_CSO 64;
BA_ "FlexKomSigStartPos" SG_ 948 VC_TRLR_TYPE_CSO 7;
BA_ "FlexKomSID" SG_ 948 VC_TRLR_TYPE_CSO 2007;
BA_ "GenSigTimeout_IC" SG_ 948 VC_TRLR_TYPE_CSO 21000;
BA_ "FlexKomSigStartValue" SG_ 948 VC_TRLR_TYPE_CSO "0300000000000000h";
BA_ "GenSigCycleTime" SG_ 948 VC_TRLR_TYPE_CSO 2000;
BA_ "GenSigSendType" SG_ 948 VC_TRLR_TYPE_CSO 5;
BA_ "GenSigSNA" SG_ 948 VC_TRLR_NAME_CSO "0h";
BA_ "FlexKomIsMotorola" SG_ 948 VC_TRLR_NAME_CSO 1;
BA_ "FlexKomComment" SG_ 948 VC_TRLR_NAME_CSO "Vehicle configuration - customer settings menu 2 P";
BA_ "FlexKomSigName" SG_ 948 VC_TRLR_NAME_CSO "VehCfgCSM2_Pkt";
BA_ "FlexKomSigLaenge" SG_ 948 VC_TRLR_NAME_CSO 64;
BA_ "FlexKomSigStartPos" SG_ 948 VC_TRLR_NAME_CSO 7;
BA_ "FlexKomSID" SG_ 948 VC_TRLR_NAME_CSO 2007;
BA_ "GenSigTimeout_IC" SG_ 948 VC_TRLR_NAME_CSO 21000;
BA_ "FlexKomSigStartValue" SG_ 948 VC_TRLR_NAME_CSO "0300000000000000h";
BA_ "GenSigCycleTime" SG_ 948 VC_TRLR_NAME_CSO 2000;
BA_ "GenSigSendType" SG_ 948 VC_TRLR_NAME_CSO 5;
BA_ "GenSigSNA" SG_ 948 VC_TRLR_CSO "0h";
BA_ "FlexKomIsMotorola" SG_ 948 VC_TRLR_CSO 1;
BA_ "FlexKomComment" SG_ 948 VC_TRLR_CSO "Vehicle configuration - customer settings menu 2 P";
BA_ "FlexKomSigName" SG_ 948 VC_TRLR_CSO "VehCfgCSM2_Pkt";
BA_ "FlexKomSigLaenge" SG_ 948 VC_TRLR_CSO 64;
BA_ "FlexKomSigStartPos" SG_ 948 VC_TRLR_CSO 7;
BA_ "FlexKomSID" SG_ 948 VC_TRLR_CSO 2007;
BA_ "GenSigTimeout_IC" SG_ 948 VC_TRLR_CSO 21000;
BA_ "FlexKomSigStartValue" SG_ 948 VC_TRLR_CSO "0300000000000000h";
BA_ "GenSigCycleTime" SG_ 948 VC_TRLR_CSO 2000;
BA_ "GenSigSendType" SG_ 948 VC_TRLR_CSO 5;
BA_ "GenSigSNA" SG_ 948 VC_TORQUE_CSO "0h";
BA_ "FlexKomIsMotorola" SG_ 948 VC_TORQUE_CSO 1;
BA_ "FlexKomComment" SG_ 948 VC_TORQUE_CSO "Vehicle configuration - customer settings menu 2 P";
BA_ "FlexKomSigName" SG_ 948 VC_TORQUE_CSO "VehCfgCSM2_Pkt";
BA_ "FlexKomSigLaenge" SG_ 948 VC_TORQUE_CSO 64;
BA_ "FlexKomSigStartPos" SG_ 948 VC_TORQUE_CSO 7;
BA_ "FlexKomSID" SG_ 948 VC_TORQUE_CSO 2007;
BA_ "GenSigTimeout_IC" SG_ 948 VC_TORQUE_CSO 21000;
BA_ "FlexKomSigStartValue" SG_ 948 VC_TORQUE_CSO "0300000000000000h";
BA_ "GenSigCycleTime" SG_ 948 VC_TORQUE_CSO 2000;
BA_ "GenSigSendType" SG_ 948 VC_TORQUE_CSO 5;
BA_ "GenSigSNA" SG_ 948 VC_TLT_MRR_CSO "0h";
BA_ "FlexKomIsMotorola" SG_ 948 VC_TLT_MRR_CSO 1;
BA_ "FlexKomComment" SG_ 948 VC_TLT_MRR_CSO "Vehicle configuration - customer settings menu 2 P";
BA_ "FlexKomSigName" SG_ 948 VC_TLT_MRR_CSO "VehCfgCSM2_Pkt";
BA_ "FlexKomSigLaenge" SG_ 948 VC_TLT_MRR_CSO 64;
BA_ "FlexKomSigStartPos" SG_ 948 VC_TLT_MRR_CSO 7;
BA_ "FlexKomSID" SG_ 948 VC_TLT_MRR_CSO 2007;
BA_ "GenSigTimeout_IC" SG_ 948 VC_TLT_MRR_CSO 21000;
BA_ "FlexKomSigStartValue" SG_ 948 VC_TLT_MRR_CSO "0300000000000000h";
BA_ "GenSigCycleTime" SG_ 948 VC_TLT_MRR_CSO 2000;
BA_ "GenSigSendType" SG_ 948 VC_TLT_MRR_CSO 5;
BA_ "GenSigSNA" SG_ 948 VC_TEMP_CSO "0h";
BA_ "FlexKomIsMotorola" SG_ 948 VC_TEMP_CSO 1;
BA_ "FlexKomComment" SG_ 948 VC_TEMP_CSO "Vehicle configuration - customer settings menu 2 P";
BA_ "FlexKomSigName" SG_ 948 VC_TEMP_CSO "VehCfgCSM2_Pkt";
BA_ "FlexKomSigLaenge" SG_ 948 VC_TEMP_CSO 64;
BA_ "FlexKomSigStartPos" SG_ 948 VC_TEMP_CSO 7;
BA_ "FlexKomSID" SG_ 948 VC_TEMP_CSO 2007;
BA_ "FlexKomSigStartValue" SG_ 948 VC_TEMP_CSO "0300000000000000h";
BA_ "GenSigCycleTime" SG_ 948 VC_TEMP_CSO 2000;
BA_ "GenSigSendType" SG_ 948 VC_TEMP_CSO 5;
BA_ "GenSigSNA" SG_ 948 VC_TEEN_SLD_DR_CHM_CSO "0h";
BA_ "FlexKomIsMotorola" SG_ 948 VC_TEEN_SLD_DR_CHM_CSO 1;
BA_ "FlexKomComment" SG_ 948 VC_TEEN_SLD_DR_CHM_CSO "Vehicle configuration - customer settings menu 2 P";
BA_ "FlexKomSigName" SG_ 948 VC_TEEN_SLD_DR_CHM_CSO "VehCfgCSM2_Pkt";
BA_ "FlexKomSigLaenge" SG_ 948 VC_TEEN_SLD_DR_CHM_CSO 64;
BA_ "FlexKomSigStartPos" SG_ 948 VC_TEEN_SLD_DR_CHM_CSO 7;
BA_ "FlexKomSID" SG_ 948 VC_TEEN_SLD_DR_CHM_CSO 2007;
BA_ "GenSigTimeout_IC" SG_ 948 VC_TEEN_SLD_DR_CHM_CSO 21000;
BA_ "FlexKomSigStartValue" SG_ 948 VC_TEEN_SLD_DR_CHM_CSO "0300000000000000h";
BA_ "GenSigCycleTime" SG_ 948 VC_TEEN_SLD_DR_CHM_CSO 2000;
BA_ "GenSigSendType" SG_ 948 VC_TEEN_SLD_DR_CHM_CSO 5;
BA_ "GenSigSNA" SG_ 948 VC_TEEN_SLD_DR_ALRT_CSO "0h";
BA_ "FlexKomIsMotorola" SG_ 948 VC_TEEN_SLD_DR_ALRT_CSO 1;
BA_ "FlexKomComment" SG_ 948 VC_TEEN_SLD_DR_ALRT_CSO "Vehicle configuration - customer settings menu 2 P";
BA_ "FlexKomSigName" SG_ 948 VC_TEEN_SLD_DR_ALRT_CSO "VehCfgCSM2_Pkt";
BA_ "FlexKomSigLaenge" SG_ 948 VC_TEEN_SLD_DR_ALRT_CSO 64;
BA_ "FlexKomSigStartPos" SG_ 948 VC_TEEN_SLD_DR_ALRT_CSO 7;
BA_ "FlexKomSID" SG_ 948 VC_TEEN_SLD_DR_ALRT_CSO 2007;
BA_ "GenSigTimeout_IC" SG_ 948 VC_TEEN_SLD_DR_ALRT_CSO 21000;
BA_ "FlexKomSigStartValue" SG_ 948 VC_TEEN_SLD_DR_ALRT_CSO "0300000000000000h";
BA_ "GenSigCycleTime" SG_ 948 VC_TEEN_SLD_DR_ALRT_CSO 2000;
BA_ "GenSigSendType" SG_ 948 VC_TEEN_SLD_DR_ALRT_CSO 5;
BA_ "GenSigSNA" SG_ 948 VC_TEEN_RR_PRK_VOL_CSO "0h";
BA_ "FlexKomIsMotorola" SG_ 948 VC_TEEN_RR_PRK_VOL_CSO 1;
BA_ "FlexKomComment" SG_ 948 VC_TEEN_RR_PRK_VOL_CSO "Vehicle configuration - customer settings menu 2 P";
BA_ "FlexKomSigName" SG_ 948 VC_TEEN_RR_PRK_VOL_CSO "VehCfgCSM2_Pkt";
BA_ "FlexKomSigLaenge" SG_ 948 VC_TEEN_RR_PRK_VOL_CSO 64;
BA_ "FlexKomSigStartPos" SG_ 948 VC_TEEN_RR_PRK_VOL_CSO 7;
BA_ "FlexKomSID" SG_ 948 VC_TEEN_RR_PRK_VOL_CSO 2007;
BA_ "GenSigTimeout_IC" SG_ 948 VC_TEEN_RR_PRK_VOL_CSO 21000;
BA_ "FlexKomSigStartValue" SG_ 948 VC_TEEN_RR_PRK_VOL_CSO "0300000000000000h";
BA_ "GenSigCycleTime" SG_ 948 VC_TEEN_RR_PRK_VOL_CSO 2000;
BA_ "GenSigSendType" SG_ 948 VC_TEEN_RR_PRK_VOL_CSO 5;
BA_ "GenSigSNA" SG_ 948 VC_TEEN_RAIN_WPR_CSO "0h";
BA_ "FlexKomIsMotorola" SG_ 948 VC_TEEN_RAIN_WPR_CSO 1;
BA_ "FlexKomComment" SG_ 948 VC_TEEN_RAIN_WPR_CSO "Vehicle configuration - customer settings menu 2 P";
BA_ "FlexKomSigName" SG_ 948 VC_TEEN_RAIN_WPR_CSO "VehCfgCSM2_Pkt";
BA_ "FlexKomSigLaenge" SG_ 948 VC_TEEN_RAIN_WPR_CSO 64;
BA_ "FlexKomSigStartPos" SG_ 948 VC_TEEN_RAIN_WPR_CSO 7;
BA_ "FlexKomSID" SG_ 948 VC_TEEN_RAIN_WPR_CSO 2007;
BA_ "GenSigTimeout_IC" SG_ 948 VC_TEEN_RAIN_WPR_CSO 21000;
BA_ "FlexKomSigStartValue" SG_ 948 VC_TEEN_RAIN_WPR_CSO "0300000000000000h";
BA_ "GenSigCycleTime" SG_ 948 VC_TEEN_RAIN_WPR_CSO 2000;
BA_ "GenSigSendType" SG_ 948 VC_TEEN_RAIN_WPR_CSO 5;
BA_ "GenSigSNA" SG_ 948 VC_TEEN_PRK_ASST_CSO "0h";
BA_ "FlexKomIsMotorola" SG_ 948 VC_TEEN_PRK_ASST_CSO 1;
BA_ "FlexKomComment" SG_ 948 VC_TEEN_PRK_ASST_CSO "Vehicle configuration - customer settings menu 2 P";
BA_ "FlexKomSigName" SG_ 948 VC_TEEN_PRK_ASST_CSO "VehCfgCSM2_Pkt";
BA_ "FlexKomSigLaenge" SG_ 948 VC_TEEN_PRK_ASST_CSO 64;
BA_ "FlexKomSigStartPos" SG_ 948 VC_TEEN_PRK_ASST_CSO 7;
BA_ "FlexKomSID" SG_ 948 VC_TEEN_PRK_ASST_CSO 2007;
BA_ "GenSigTimeout_IC" SG_ 948 VC_TEEN_PRK_ASST_CSO 21000;
BA_ "FlexKomSigStartValue" SG_ 948 VC_TEEN_PRK_ASST_CSO "0300000000000000h";
BA_ "GenSigCycleTime" SG_ 948 VC_TEEN_PRK_ASST_CSO 2000;
BA_ "GenSigSendType" SG_ 948 VC_TEEN_PRK_ASST_CSO 5;
BA_ "GenSigSNA" SG_ 948 VC_TEEN_PLG_CHIME_CSO "0h";
BA_ "FlexKomIsMotorola" SG_ 948 VC_TEEN_PLG_CHIME_CSO 1;
BA_ "FlexKomComment" SG_ 948 VC_TEEN_PLG_CHIME_CSO "Vehicle configuration - customer settings menu 2 P";
BA_ "FlexKomSigName" SG_ 948 VC_TEEN_PLG_CHIME_CSO "VehCfgCSM2_Pkt";
BA_ "FlexKomSigLaenge" SG_ 948 VC_TEEN_PLG_CHIME_CSO 64;
BA_ "FlexKomSigStartPos" SG_ 948 VC_TEEN_PLG_CHIME_CSO 7;
BA_ "FlexKomSID" SG_ 948 VC_TEEN_PLG_CHIME_CSO 2007;
BA_ "GenSigTimeout_IC" SG_ 948 VC_TEEN_PLG_CHIME_CSO 21000;
BA_ "FlexKomSigStartValue" SG_ 948 VC_TEEN_PLG_CHIME_CSO "0300000000000000h";
BA_ "GenSigCycleTime" SG_ 948 VC_TEEN_PLG_CHIME_CSO 2000;
BA_ "GenSigSendType" SG_ 948 VC_TEEN_PLG_CHIME_CSO 5;
BA_ "GenSigSNA" SG_ 948 VC_TEEN_MAX_SPEED_CSO "0h";
BA_ "FlexKomIsMotorola" SG_ 948 VC_TEEN_MAX_SPEED_CSO 1;
BA_ "FlexKomComment" SG_ 948 VC_TEEN_MAX_SPEED_CSO "Vehicle configuration - customer settings menu 2 P";
BA_ "FlexKomSigName" SG_ 948 VC_TEEN_MAX_SPEED_CSO "VehCfgCSM2_Pkt";
BA_ "FlexKomSigLaenge" SG_ 948 VC_TEEN_MAX_SPEED_CSO 64;
BA_ "FlexKomSigStartPos" SG_ 948 VC_TEEN_MAX_SPEED_CSO 7;
BA_ "FlexKomSID" SG_ 948 VC_TEEN_MAX_SPEED_CSO 2007;
BA_ "GenSigTimeout_IC" SG_ 948 VC_TEEN_MAX_SPEED_CSO 21000;
BA_ "FlexKomSigStartValue" SG_ 948 VC_TEEN_MAX_SPEED_CSO "0300000000000000h";
BA_ "GenSigCycleTime" SG_ 948 VC_TEEN_MAX_SPEED_CSO 2000;
BA_ "GenSigSendType" SG_ 948 VC_TEEN_MAX_SPEED_CSO 5;
BA_ "GenSigSNA" SG_ 948 VC_TEEN_LGHT_WPR_CSO "0h";
BA_ "FlexKomIsMotorola" SG_ 948 VC_TEEN_LGHT_WPR_CSO 1;
BA_ "FlexKomComment" SG_ 948 VC_TEEN_LGHT_WPR_CSO "Vehicle configuration - customer settings menu 2 P";
BA_ "FlexKomSigName" SG_ 948 VC_TEEN_LGHT_WPR_CSO "VehCfgCSM2_Pkt";
BA_ "FlexKomSigLaenge" SG_ 948 VC_TEEN_LGHT_WPR_CSO 64;
BA_ "FlexKomSigStartPos" SG_ 948 VC_TEEN_LGHT_WPR_CSO 7;
BA_ "FlexKomSID" SG_ 948 VC_TEEN_LGHT_WPR_CSO 2007;
BA_ "GenSigTimeout_IC" SG_ 948 VC_TEEN_LGHT_WPR_CSO 21000;
BA_ "FlexKomSigStartValue" SG_ 948 VC_TEEN_LGHT_WPR_CSO "0300000000000000h";
BA_ "GenSigCycleTime" SG_ 948 VC_TEEN_LGHT_WPR_CSO 2000;
BA_ "GenSigSendType" SG_ 948 VC_TEEN_LGHT_WPR_CSO 5;
BA_ "GenSigSNA" SG_ 948 VC_TEEN_FUEL_WRN_CSO "0h";
BA_ "FlexKomIsMotorola" SG_ 948 VC_TEEN_FUEL_WRN_CSO 1;
BA_ "FlexKomComment" SG_ 948 VC_TEEN_FUEL_WRN_CSO "Vehicle configuration - customer settings menu 2 P";
BA_ "FlexKomSigName" SG_ 948 VC_TEEN_FUEL_WRN_CSO "VehCfgCSM2_Pkt";
BA_ "FlexKomSigLaenge" SG_ 948 VC_TEEN_FUEL_WRN_CSO 64;
BA_ "FlexKomSigStartPos" SG_ 948 VC_TEEN_FUEL_WRN_CSO 7;
BA_ "FlexKomSID" SG_ 948 VC_TEEN_FUEL_WRN_CSO 2007;
BA_ "GenSigTimeout_IC" SG_ 948 VC_TEEN_FUEL_WRN_CSO 21000;
BA_ "FlexKomSigStartValue" SG_ 948 VC_TEEN_FUEL_WRN_CSO "0300000000000000h";
BA_ "GenSigCycleTime" SG_ 948 VC_TEEN_FUEL_WRN_CSO 2000;
BA_ "GenSigSendType" SG_ 948 VC_TEEN_FUEL_WRN_CSO 5;
BA_ "GenSigSNA" SG_ 948 VC_TEEN_FUEL_POPUP_CSO "0h";
BA_ "FlexKomIsMotorola" SG_ 948 VC_TEEN_FUEL_POPUP_CSO 1;
BA_ "FlexKomComment" SG_ 948 VC_TEEN_FUEL_POPUP_CSO "Vehicle configuration - customer settings menu 2 P";
BA_ "FlexKomSigName" SG_ 948 VC_TEEN_FUEL_POPUP_CSO "VehCfgCSM2_Pkt";
BA_ "FlexKomSigLaenge" SG_ 948 VC_TEEN_FUEL_POPUP_CSO 64;
BA_ "FlexKomSigStartPos" SG_ 948 VC_TEEN_FUEL_POPUP_CSO 7;
BA_ "FlexKomSID" SG_ 948 VC_TEEN_FUEL_POPUP_CSO 2007;
BA_ "GenSigTimeout_IC" SG_ 948 VC_TEEN_FUEL_POPUP_CSO 21000;
BA_ "FlexKomSigStartValue" SG_ 948 VC_TEEN_FUEL_POPUP_CSO "0300000000000000h";
BA_ "GenSigCycleTime" SG_ 948 VC_TEEN_FUEL_POPUP_CSO 2000;
BA_ "GenSigSendType" SG_ 948 VC_TEEN_FUEL_POPUP_CSO 5;
BA_ "GenSigSNA" SG_ 948 VC_TEEN_FT_PRK_VOL_CSO "0h";
BA_ "FlexKomIsMotorola" SG_ 948 VC_TEEN_FT_PRK_VOL_CSO 1;
BA_ "FlexKomComment" SG_ 948 VC_TEEN_FT_PRK_VOL_CSO "Vehicle configuration - customer settings menu 2 P";
BA_ "FlexKomSigName" SG_ 948 VC_TEEN_FT_PRK_VOL_CSO "VehCfgCSM2_Pkt";
BA_ "FlexKomSigLaenge" SG_ 948 VC_TEEN_FT_PRK_VOL_CSO 64;
BA_ "FlexKomSigStartPos" SG_ 948 VC_TEEN_FT_PRK_VOL_CSO 7;
BA_ "FlexKomSID" SG_ 948 VC_TEEN_FT_PRK_VOL_CSO 2007;
BA_ "GenSigTimeout_IC" SG_ 948 VC_TEEN_FT_PRK_VOL_CSO 21000;
BA_ "FlexKomSigStartValue" SG_ 948 VC_TEEN_FT_PRK_VOL_CSO "0300000000000000h";
BA_ "GenSigCycleTime" SG_ 948 VC_TEEN_FT_PRK_VOL_CSO 2000;
BA_ "GenSigSendType" SG_ 948 VC_TEEN_FT_PRK_VOL_CSO 5;
BA_ "GenSigSNA" SG_ 948 VC_TEEN_FCW_SENS_CSO "0h";
BA_ "FlexKomIsMotorola" SG_ 948 VC_TEEN_FCW_SENS_CSO 1;
BA_ "FlexKomComment" SG_ 948 VC_TEEN_FCW_SENS_CSO "Vehicle configuration - customer settings menu 2 P";
BA_ "FlexKomSigName" SG_ 948 VC_TEEN_FCW_SENS_CSO "VehCfgCSM2_Pkt";
BA_ "FlexKomSigLaenge" SG_ 948 VC_TEEN_FCW_SENS_CSO 64;
BA_ "FlexKomSigStartPos" SG_ 948 VC_TEEN_FCW_SENS_CSO 7;
BA_ "FlexKomSID" SG_ 948 VC_TEEN_FCW_SENS_CSO 2007;
BA_ "GenSigTimeout_IC" SG_ 948 VC_TEEN_FCW_SENS_CSO 21000;
BA_ "FlexKomSigStartValue" SG_ 948 VC_TEEN_FCW_SENS_CSO "0300000000000000h";
BA_ "GenSigCycleTime" SG_ 948 VC_TEEN_FCW_SENS_CSO 2000;
BA_ "GenSigSendType" SG_ 948 VC_TEEN_FCW_SENS_CSO 5;
BA_ "GenSigSNA" SG_ 948 VC_TEEN_FCW_BRK_CSO "0h";
BA_ "FlexKomIsMotorola" SG_ 948 VC_TEEN_FCW_BRK_CSO 1;
BA_ "FlexKomComment" SG_ 948 VC_TEEN_FCW_BRK_CSO "Vehicle configuration - customer settings menu 2 P";
BA_ "FlexKomSigName" SG_ 948 VC_TEEN_FCW_BRK_CSO "VehCfgCSM2_Pkt";
BA_ "FlexKomSigLaenge" SG_ 948 VC_TEEN_FCW_BRK_CSO 64;
BA_ "FlexKomSigStartPos" SG_ 948 VC_TEEN_FCW_BRK_CSO 7;
BA_ "FlexKomSID" SG_ 948 VC_TEEN_FCW_BRK_CSO 2007;
BA_ "GenSigTimeout_IC" SG_ 948 VC_TEEN_FCW_BRK_CSO 21000;
BA_ "FlexKomSigStartValue" SG_ 948 VC_TEEN_FCW_BRK_CSO "0300000000000000h";
BA_ "GenSigCycleTime" SG_ 948 VC_TEEN_FCW_BRK_CSO 2000;
BA_ "GenSigSendType" SG_ 948 VC_TEEN_FCW_BRK_CSO 5;
BA_ "GenSigSNA" SG_ 948 VC_TEEN_BLIND_SPOT_CSO "0h";
BA_ "FlexKomIsMotorola" SG_ 948 VC_TEEN_BLIND_SPOT_CSO 1;
BA_ "FlexKomComment" SG_ 948 VC_TEEN_BLIND_SPOT_CSO "Vehicle configuration - customer settings menu 2 P";
BA_ "FlexKomSigName" SG_ 948 VC_TEEN_BLIND_SPOT_CSO "VehCfgCSM2_Pkt";
BA_ "FlexKomSigLaenge" SG_ 948 VC_TEEN_BLIND_SPOT_CSO 64;
BA_ "FlexKomSigStartPos" SG_ 948 VC_TEEN_BLIND_SPOT_CSO 7;
BA_ "FlexKomSID" SG_ 948 VC_TEEN_BLIND_SPOT_CSO 2007;
BA_ "GenSigTimeout_IC" SG_ 948 VC_TEEN_BLIND_SPOT_CSO 21000;
BA_ "FlexKomSigStartValue" SG_ 948 VC_TEEN_BLIND_SPOT_CSO "0300000000000000h";
BA_ "GenSigCycleTime" SG_ 948 VC_TEEN_BLIND_SPOT_CSO 2000;
BA_ "GenSigSendType" SG_ 948 VC_TEEN_BLIND_SPOT_CSO 5;
BA_ "GenSigSNA" SG_ 948 VC_TEEN_AUTO_HB_CSO "0h";
BA_ "FlexKomIsMotorola" SG_ 948 VC_TEEN_AUTO_HB_CSO 1;
BA_ "FlexKomComment" SG_ 948 VC_TEEN_AUTO_HB_CSO "Vehicle configuration - customer settings menu 2 P";
BA_ "FlexKomSigName" SG_ 948 VC_TEEN_AUTO_HB_CSO "VehCfgCSM2_Pkt";
BA_ "FlexKomSigLaenge" SG_ 948 VC_TEEN_AUTO_HB_CSO 64;
BA_ "FlexKomSigStartPos" SG_ 948 VC_TEEN_AUTO_HB_CSO 7;
BA_ "FlexKomSID" SG_ 948 VC_TEEN_AUTO_HB_CSO 2007;
BA_ "GenSigTimeout_IC" SG_ 948 VC_TEEN_AUTO_HB_CSO 21000;
BA_ "FlexKomSigStartValue" SG_ 948 VC_TEEN_AUTO_HB_CSO "0300000000000000h";
BA_ "GenSigCycleTime" SG_ 948 VC_TEEN_AUTO_HB_CSO 2000;
BA_ "GenSigSendType" SG_ 948 VC_TEEN_AUTO_HB_CSO 5;
BA_ "GenSigSNA" SG_ 948 VC_SVC_GRIDLINES_CSO "0h";
BA_ "FlexKomIsMotorola" SG_ 948 VC_SVC_GRIDLINES_CSO 1;
BA_ "FlexKomComment" SG_ 948 VC_SVC_GRIDLINES_CSO "Vehicle configuration - customer settings menu 2 P";
BA_ "FlexKomSigName" SG_ 948 VC_SVC_GRIDLINES_CSO "VehCfgCSM2_Pkt";
BA_ "FlexKomSigLaenge" SG_ 948 VC_SVC_GRIDLINES_CSO 64;
BA_ "FlexKomSigStartPos" SG_ 948 VC_SVC_GRIDLINES_CSO 7;
BA_ "FlexKomSID" SG_ 948 VC_SVC_GRIDLINES_CSO 2007;
BA_ "GenSigTimeout_IC" SG_ 948 VC_SVC_GRIDLINES_CSO 21000;
BA_ "FlexKomSigStartValue" SG_ 948 VC_SVC_GRIDLINES_CSO "0300000000000000h";
BA_ "GenSigCycleTime" SG_ 948 VC_SVC_GRIDLINES_CSO 2000;
BA_ "GenSigSendType" SG_ 948 VC_SVC_GRIDLINES_CSO 5;
BA_ "GenSigSNA" SG_ 948 VC_SVC_DELAY_CSO "0h";
BA_ "FlexKomIsMotorola" SG_ 948 VC_SVC_DELAY_CSO 1;
BA_ "FlexKomComment" SG_ 948 VC_SVC_DELAY_CSO "Vehicle configuration - customer settings menu 2 P";
BA_ "FlexKomSigName" SG_ 948 VC_SVC_DELAY_CSO "VehCfgCSM2_Pkt";
BA_ "FlexKomSigLaenge" SG_ 948 VC_SVC_DELAY_CSO 64;
BA_ "FlexKomSigStartPos" SG_ 948 VC_SVC_DELAY_CSO 7;
BA_ "FlexKomSID" SG_ 948 VC_SVC_DELAY_CSO 2007;
BA_ "GenSigTimeout_IC" SG_ 948 VC_SVC_DELAY_CSO 21000;
BA_ "FlexKomSigStartValue" SG_ 948 VC_SVC_DELAY_CSO "0300000000000000h";
BA_ "GenSigCycleTime" SG_ 948 VC_SVC_DELAY_CSO 2000;
BA_ "GenSigSendType" SG_ 948 VC_SVC_DELAY_CSO 5;
BA_ "GenSigSendType" SG_ 948 VC_SPEED_WARNING_CSO 5;
BA_ "GenSigCycleTime" SG_ 948 VC_SPEED_WARNING_CSO 2000;
BA_ "FlexKomSigStartValue" SG_ 948 VC_SPEED_WARNING_CSO "0300000000000000h";
BA_ "GenSigTimeout_IC" SG_ 948 VC_SPEED_WARNING_CSO 21000;
BA_ "FlexKomSID" SG_ 948 VC_SPEED_WARNING_CSO 2007;
BA_ "FlexKomSigStartPos" SG_ 948 VC_SPEED_WARNING_CSO 7;
BA_ "FlexKomSigLaenge" SG_ 948 VC_SPEED_WARNING_CSO 64;
BA_ "FlexKomSigName" SG_ 948 VC_SPEED_WARNING_CSO "VehCfgCSM2_Pkt";
BA_ "FlexKomIsMotorola" SG_ 948 VC_SPEED_WARNING_CSO 1;
BA_ "GenSigSNA" SG_ 948 VC_SPEED_WARNING_CSO "0h";
BA_ "FlexKomComment" SG_ 948 VC_SPEED_WARNING_CSO "Vehicle configuration - customer settings menu 2 P";
BA_ "GenSigSNA" SG_ 948 VC_SPEED_CSO "0h";
BA_ "FlexKomIsMotorola" SG_ 948 VC_SPEED_CSO 1;
BA_ "FlexKomComment" SG_ 948 VC_SPEED_CSO "Vehicle configuration - customer settings menu 2 P";
BA_ "FlexKomSigName" SG_ 948 VC_SPEED_CSO "VehCfgCSM2_Pkt";
BA_ "FlexKomSigLaenge" SG_ 948 VC_SPEED_CSO 64;
BA_ "FlexKomSigStartPos" SG_ 948 VC_SPEED_CSO 7;
BA_ "FlexKomSID" SG_ 948 VC_SPEED_CSO 2007;
BA_ "GenSigTimeout_IC" SG_ 948 VC_SPEED_CSO 21000;
BA_ "FlexKomSigStartValue" SG_ 948 VC_SPEED_CSO "0300000000000000h";
BA_ "GenSigCycleTime" SG_ 948 VC_SPEED_CSO 2000;
BA_ "GenSigSendType" SG_ 948 VC_SPEED_CSO 5;
BA_ "GenSigSNA" SG_ 948 VC_SLD_DR_CHM_CSO "0h";
BA_ "FlexKomIsMotorola" SG_ 948 VC_SLD_DR_CHM_CSO 1;
BA_ "FlexKomComment" SG_ 948 VC_SLD_DR_CHM_CSO "Vehicle configuration - customer settings menu 2 P";
BA_ "FlexKomSigName" SG_ 948 VC_SLD_DR_CHM_CSO "VehCfgCSM2_Pkt";
BA_ "FlexKomSigLaenge" SG_ 948 VC_SLD_DR_CHM_CSO 64;
BA_ "FlexKomSigStartPos" SG_ 948 VC_SLD_DR_CHM_CSO 7;
BA_ "FlexKomSID" SG_ 948 VC_SLD_DR_CHM_CSO 2007;
BA_ "GenSigTimeout_IC" SG_ 948 VC_SLD_DR_CHM_CSO 21000;
BA_ "FlexKomSigStartValue" SG_ 948 VC_SLD_DR_CHM_CSO "0300000000000000h";
BA_ "GenSigCycleTime" SG_ 948 VC_SLD_DR_CHM_CSO 2000;
BA_ "GenSigSendType" SG_ 948 VC_SLD_DR_CHM_CSO 5;
BA_ "GenSigSNA" SG_ 948 VC_SLD_DR_ALRT_CSO "0h";
BA_ "FlexKomIsMotorola" SG_ 948 VC_SLD_DR_ALRT_CSO 1;
BA_ "FlexKomComment" SG_ 948 VC_SLD_DR_ALRT_CSO "Vehicle configuration - customer settings menu 2 P";
BA_ "FlexKomSigName" SG_ 948 VC_SLD_DR_ALRT_CSO "VehCfgCSM2_Pkt";
BA_ "FlexKomSigLaenge" SG_ 948 VC_SLD_DR_ALRT_CSO 64;
BA_ "FlexKomSigStartPos" SG_ 948 VC_SLD_DR_ALRT_CSO 7;
BA_ "FlexKomSID" SG_ 948 VC_SLD_DR_ALRT_CSO 2007;
BA_ "GenSigTimeout_IC" SG_ 948 VC_SLD_DR_ALRT_CSO 21000;
BA_ "FlexKomSigStartValue" SG_ 948 VC_SLD_DR_ALRT_CSO "0300000000000000h";
BA_ "GenSigCycleTime" SG_ 948 VC_SLD_DR_ALRT_CSO 2000;
BA_ "GenSigSendType" SG_ 948 VC_SLD_DR_ALRT_CSO 5;
BA_ "GenSigSNA" SG_ 948 VC_RKE_UNLK_CSO "0h";
BA_ "FlexKomIsMotorola" SG_ 948 VC_RKE_UNLK_CSO 1;
BA_ "FlexKomComment" SG_ 948 VC_RKE_UNLK_CSO "Vehicle configuration - customer settings menu 2 P";
BA_ "FlexKomSigName" SG_ 948 VC_RKE_UNLK_CSO "VehCfgCSM2_Pkt";
BA_ "FlexKomSigLaenge" SG_ 948 VC_RKE_UNLK_CSO 64;
BA_ "FlexKomSigStartPos" SG_ 948 VC_RKE_UNLK_CSO 7;
BA_ "FlexKomSID" SG_ 948 VC_RKE_UNLK_CSO 2007;
BA_ "GenSigTimeout_IC" SG_ 948 VC_RKE_UNLK_CSO 21000;
BA_ "FlexKomSigStartValue" SG_ 948 VC_RKE_UNLK_CSO "0300000000000000h";
BA_ "GenSigCycleTime" SG_ 948 VC_RKE_UNLK_CSO 2000;
BA_ "GenSigSendType" SG_ 948 VC_RKE_UNLK_CSO 5;
BA_ "GenSigSNA" SG_ 948 VC_RKE_MEM_CSO "0h";
BA_ "FlexKomIsMotorola" SG_ 948 VC_RKE_MEM_CSO 1;
BA_ "FlexKomComment" SG_ 948 VC_RKE_MEM_CSO "Vehicle configuration - customer settings menu 2 P";
BA_ "FlexKomSigName" SG_ 948 VC_RKE_MEM_CSO "VehCfgCSM2_Pkt";
BA_ "FlexKomSigLaenge" SG_ 948 VC_RKE_MEM_CSO 64;
BA_ "FlexKomSigStartPos" SG_ 948 VC_RKE_MEM_CSO 7;
BA_ "FlexKomSID" SG_ 948 VC_RKE_MEM_CSO 2007;
BA_ "GenSigTimeout_IC" SG_ 948 VC_RKE_MEM_CSO 21000;
BA_ "FlexKomSigStartValue" SG_ 948 VC_RKE_MEM_CSO "0300000000000000h";
BA_ "GenSigCycleTime" SG_ 948 VC_RKE_MEM_CSO 2000;
BA_ "GenSigSendType" SG_ 948 VC_RKE_MEM_CSO 5;
BA_ "GenSigSNA" SG_ 948 VC_REAR_CMRA_DLY_CSO "0h";
BA_ "FlexKomIsMotorola" SG_ 948 VC_REAR_CMRA_DLY_CSO 1;
BA_ "FlexKomComment" SG_ 948 VC_REAR_CMRA_DLY_CSO "Vehicle configuration - customer settings menu 2 P";
BA_ "FlexKomSigName" SG_ 948 VC_REAR_CMRA_DLY_CSO "VehCfgCSM2_Pkt";
BA_ "FlexKomSigLaenge" SG_ 948 VC_REAR_CMRA_DLY_CSO 64;
BA_ "FlexKomSigStartPos" SG_ 948 VC_REAR_CMRA_DLY_CSO 7;
BA_ "FlexKomSID" SG_ 948 VC_REAR_CMRA_DLY_CSO 2007;
BA_ "GenSigTimeout_IC" SG_ 948 VC_REAR_CMRA_DLY_CSO 21000;
BA_ "FlexKomSigStartValue" SG_ 948 VC_REAR_CMRA_DLY_CSO "0300000000000000h";
BA_ "GenSigCycleTime" SG_ 948 VC_REAR_CMRA_DLY_CSO 2000;
BA_ "GenSigSendType" SG_ 948 VC_REAR_CMRA_DLY_CSO 5;
BA_ "GenSigSNA" SG_ 948 VC_RDY_DRV_CSO "0h";
BA_ "FlexKomIsMotorola" SG_ 948 VC_RDY_DRV_CSO 1;
BA_ "FlexKomSigName" SG_ 948 VC_RDY_DRV_CSO "VehCfgCSM2_Pkt";
BA_ "FlexKomSigLaenge" SG_ 948 VC_RDY_DRV_CSO 64;
BA_ "FlexKomSigStartPos" SG_ 948 VC_RDY_DRV_CSO 7;
BA_ "FlexKomSID" SG_ 948 VC_RDY_DRV_CSO 2007;
BA_ "GenSigTimeout_IC" SG_ 948 VC_RDY_DRV_CSO 21000;
BA_ "FlexKomSigStartValue" SG_ 948 VC_RDY_DRV_CSO "0300000000000000h";
BA_ "GenSigCycleTime" SG_ 948 VC_RDY_DRV_CSO 2000;
BA_ "GenSigSendType" SG_ 948 VC_RDY_DRV_CSO 5;
BA_ "FlexKomComment" SG_ 948 VC_RDY_DRV_CSO "Vehicle configuration - customer settings menu 2 P";
BA_ "GenSigSNA" SG_ 948 VC_PWR_FLD_MRR_CSO "0h";
BA_ "FlexKomIsMotorola" SG_ 948 VC_PWR_FLD_MRR_CSO 1;
BA_ "FlexKomComment" SG_ 948 VC_PWR_FLD_MRR_CSO "Vehicle configuration - customer settings menu 2 P";
BA_ "FlexKomSigName" SG_ 948 VC_PWR_FLD_MRR_CSO "VehCfgCSM2_Pkt";
BA_ "FlexKomSigLaenge" SG_ 948 VC_PWR_FLD_MRR_CSO 64;
BA_ "FlexKomSigStartPos" SG_ 948 VC_PWR_FLD_MRR_CSO 7;
BA_ "FlexKomSID" SG_ 948 VC_PWR_FLD_MRR_CSO 2007;
BA_ "GenSigTimeout_IC" SG_ 948 VC_PWR_FLD_MRR_CSO 21000;
BA_ "FlexKomSigStartValue" SG_ 948 VC_PWR_FLD_MRR_CSO "0300000000000000h";
BA_ "GenSigCycleTime" SG_ 948 VC_PWR_FLD_MRR_CSO 2000;
BA_ "GenSigSendType" SG_ 948 VC_PWR_FLD_MRR_CSO 5;
BA_ "GenSigSendType" SG_ 948 VC_PRK_ASST_TYPE_CSO 5;
BA_ "GenSigCycleTime" SG_ 948 VC_PRK_ASST_TYPE_CSO 2000;
BA_ "FlexKomSigStartValue" SG_ 948 VC_PRK_ASST_TYPE_CSO "0300000000000000h";
BA_ "GenSigTimeout_IC" SG_ 948 VC_PRK_ASST_TYPE_CSO 21000;
BA_ "FlexKomSID" SG_ 948 VC_PRK_ASST_TYPE_CSO 2007;
BA_ "FlexKomSigStartPos" SG_ 948 VC_PRK_ASST_TYPE_CSO 7;
BA_ "FlexKomSigLaenge" SG_ 948 VC_PRK_ASST_TYPE_CSO 64;
BA_ "FlexKomSigName" SG_ 948 VC_PRK_ASST_TYPE_CSO "VehCfgCSM2_Pkt";
BA_ "FlexKomIsMotorola" SG_ 948 VC_PRK_ASST_TYPE_CSO 1;
BA_ "GenSigSNA" SG_ 948 VC_PRK_ASST_TYPE_CSO "0h";
BA_ "FlexKomComment" SG_ 948 VC_PRK_ASST_TYPE_CSO "Vehicle configuration - customer settings menu 2 P";
BA_ "GenSigSendType" SG_ 948 VC_PADDLE_SHIFT_CSO 5;
BA_ "GenSigCycleTime" SG_ 948 VC_PADDLE_SHIFT_CSO 2000;
BA_ "FlexKomSigStartValue" SG_ 948 VC_PADDLE_SHIFT_CSO "0300000000000000h";
BA_ "GenSigTimeout_IC" SG_ 948 VC_PADDLE_SHIFT_CSO 21000;
BA_ "FlexKomSID" SG_ 948 VC_PADDLE_SHIFT_CSO 2007;
BA_ "FlexKomSigStartPos" SG_ 948 VC_PADDLE_SHIFT_CSO 7;
BA_ "FlexKomSigLaenge" SG_ 948 VC_PADDLE_SHIFT_CSO 64;
BA_ "FlexKomSigName" SG_ 948 VC_PADDLE_SHIFT_CSO "VehCfgCSM2_Pkt";
BA_ "FlexKomIsMotorola" SG_ 948 VC_PADDLE_SHIFT_CSO 1;
BA_ "GenSigSNA" SG_ 948 VC_PADDLE_SHIFT_CSO "0h";
BA_ "FlexKomComment" SG_ 948 VC_PADDLE_SHIFT_CSO "Vehicle configuration - customer settings menu 2 P";
BA_ "GenSigSendType" SG_ 948 VC_LDW_ON_CSO 5;
BA_ "GenSigCycleTime" SG_ 948 VC_LDW_ON_CSO 2000;
BA_ "FlexKomSigStartValue" SG_ 948 VC_LDW_ON_CSO "0300000000000000h";
BA_ "GenSigTimeout_IC" SG_ 948 VC_LDW_ON_CSO 21000;
BA_ "FlexKomSID" SG_ 948 VC_LDW_ON_CSO 2007;
BA_ "FlexKomSigStartPos" SG_ 948 VC_LDW_ON_CSO 7;
BA_ "FlexKomSigLaenge" SG_ 948 VC_LDW_ON_CSO 64;
BA_ "FlexKomSigName" SG_ 948 VC_LDW_ON_CSO "VehCfgCSM2_Pkt";
BA_ "FlexKomIsMotorola" SG_ 948 VC_LDW_ON_CSO 1;
BA_ "GenSigSNA" SG_ 948 VC_LDW_ON_CSO "0h";
BA_ "FlexKomComment" SG_ 948 VC_LDW_ON_CSO "Vehicle configuration - customer settings menu 2 P";
BA_ "GenSigSNA" SG_ 948 VC_HOLD_N_GO_CSO "0h";
BA_ "FlexKomIsMotorola" SG_ 948 VC_HOLD_N_GO_CSO 1;
BA_ "FlexKomComment" SG_ 948 VC_HOLD_N_GO_CSO "Vehicle configuration - customer settings menu 2 P";
BA_ "FlexKomSigName" SG_ 948 VC_HOLD_N_GO_CSO "VehCfgCSM2_Pkt";
BA_ "FlexKomSigLaenge" SG_ 948 VC_HOLD_N_GO_CSO 64;
BA_ "FlexKomSigStartPos" SG_ 948 VC_HOLD_N_GO_CSO 7;
BA_ "FlexKomSID" SG_ 948 VC_HOLD_N_GO_CSO 2007;
BA_ "GenSigTimeout_IC" SG_ 948 VC_HOLD_N_GO_CSO 21000;
BA_ "FlexKomSigStartValue" SG_ 948 VC_HOLD_N_GO_CSO "0300000000000000h";
BA_ "GenSigCycleTime" SG_ 948 VC_HOLD_N_GO_CSO 2000;
BA_ "GenSigSendType" SG_ 948 VC_HOLD_N_GO_CSO 5;
BA_ "GenSigSNA" SG_ 948 VC_HANDS_FREE_SLDR_CSO "0h";
BA_ "FlexKomIsMotorola" SG_ 948 VC_HANDS_FREE_SLDR_CSO 1;
BA_ "FlexKomComment" SG_ 948 VC_HANDS_FREE_SLDR_CSO "Vehicle configuration - customer settings menu 2 P";
BA_ "FlexKomSigName" SG_ 948 VC_HANDS_FREE_SLDR_CSO "VehCfgCSM2_Pkt";
BA_ "FlexKomSigLaenge" SG_ 948 VC_HANDS_FREE_SLDR_CSO 64;
BA_ "FlexKomSigStartPos" SG_ 948 VC_HANDS_FREE_SLDR_CSO 7;
BA_ "FlexKomSID" SG_ 948 VC_HANDS_FREE_SLDR_CSO 2007;
BA_ "GenSigTimeout_IC" SG_ 948 VC_HANDS_FREE_SLDR_CSO 21000;
BA_ "FlexKomSigStartValue" SG_ 948 VC_HANDS_FREE_SLDR_CSO "0300000000000000h";
BA_ "GenSigCycleTime" SG_ 948 VC_HANDS_FREE_SLDR_CSO 2000;
BA_ "GenSigSendType" SG_ 948 VC_HANDS_FREE_SLDR_CSO 5;
BA_ "GenSigSNA" SG_ 948 VC_HANDS_FREE_LFT_CSO "0h";
BA_ "FlexKomIsMotorola" SG_ 948 VC_HANDS_FREE_LFT_CSO 1;
BA_ "FlexKomComment" SG_ 948 VC_HANDS_FREE_LFT_CSO "Vehicle configuration - customer settings menu 2 P";
BA_ "FlexKomSigName" SG_ 948 VC_HANDS_FREE_LFT_CSO "VehCfgCSM2_Pkt";
BA_ "FlexKomSigLaenge" SG_ 948 VC_HANDS_FREE_LFT_CSO 64;
BA_ "FlexKomSigStartPos" SG_ 948 VC_HANDS_FREE_LFT_CSO 7;
BA_ "FlexKomSID" SG_ 948 VC_HANDS_FREE_LFT_CSO 2007;
BA_ "GenSigTimeout_IC" SG_ 948 VC_HANDS_FREE_LFT_CSO 21000;
BA_ "FlexKomSigStartValue" SG_ 948 VC_HANDS_FREE_LFT_CSO "0300000000000000h";
BA_ "GenSigCycleTime" SG_ 948 VC_HANDS_FREE_LFT_CSO 2000;
BA_ "GenSigSendType" SG_ 948 VC_HANDS_FREE_LFT_CSO 5;
BA_ "GenSigSNA" SG_ 948 VC_FUEL_SAV_CSO "0h";
BA_ "FlexKomIsMotorola" SG_ 948 VC_FUEL_SAV_CSO 1;
BA_ "FlexKomComment" SG_ 948 VC_FUEL_SAV_CSO "Vehicle configuration - customer settings menu 2 P";
BA_ "FlexKomSigName" SG_ 948 VC_FUEL_SAV_CSO "VehCfgCSM2_Pkt";
BA_ "FlexKomSigLaenge" SG_ 948 VC_FUEL_SAV_CSO 64;
BA_ "FlexKomSigStartPos" SG_ 948 VC_FUEL_SAV_CSO 7;
BA_ "FlexKomSID" SG_ 948 VC_FUEL_SAV_CSO 2007;
BA_ "GenSigTimeout_IC" SG_ 948 VC_FUEL_SAV_CSO 21000;
BA_ "FlexKomSigStartValue" SG_ 948 VC_FUEL_SAV_CSO "0300000000000000h";
BA_ "GenSigCycleTime" SG_ 948 VC_FUEL_SAV_CSO 2000;
BA_ "GenSigSendType" SG_ 948 VC_FUEL_SAV_CSO 5;
BA_ "GenSigSendType" SG_ 948 VC_FLSH_LMP_SLDR_CSO 5;
BA_ "GenSigCycleTime" SG_ 948 VC_FLSH_LMP_SLDR_CSO 2000;
BA_ "FlexKomSigStartValue" SG_ 948 VC_FLSH_LMP_SLDR_CSO "0300000000000000h";
BA_ "FlexKomSID" SG_ 948 VC_FLSH_LMP_SLDR_CSO 2007;
BA_ "FlexKomSigStartPos" SG_ 948 VC_FLSH_LMP_SLDR_CSO 7;
BA_ "FlexKomSigLaenge" SG_ 948 VC_FLSH_LMP_SLDR_CSO 64;
BA_ "FlexKomSigName" SG_ 948 VC_FLSH_LMP_SLDR_CSO "VehCfgCSM2_Pkt";
BA_ "FlexKomIsMotorola" SG_ 948 VC_FLSH_LMP_SLDR_CSO 1;
BA_ "GenSigSNA" SG_ 948 VC_FLSH_LMP_SLDR_CSO "0h";
BA_ "FlexKomComment" SG_ 948 VC_FLSH_LMP_SLDR_CSO "Vehicle configuration - customer settings menu 2 P";
BA_ "GenSigSendType" SG_ 948 VC_FCW_SW_CSO 5;
BA_ "GenSigCycleTime" SG_ 948 VC_FCW_SW_CSO 2000;
BA_ "FlexKomSigStartValue" SG_ 948 VC_FCW_SW_CSO "0300000000000000h";
BA_ "GenSigTimeout_IC" SG_ 948 VC_FCW_SW_CSO 21000;
BA_ "FlexKomSID" SG_ 948 VC_FCW_SW_CSO 2007;
BA_ "FlexKomSigStartPos" SG_ 948 VC_FCW_SW_CSO 7;
BA_ "FlexKomSigLaenge" SG_ 948 VC_FCW_SW_CSO 64;
BA_ "FlexKomSigName" SG_ 948 VC_FCW_SW_CSO "VehCfgCSM2_Pkt";
BA_ "FlexKomIsMotorola" SG_ 948 VC_FCW_SW_CSO 1;
BA_ "GenSigSNA" SG_ 948 VC_FCW_SW_CSO "0h";
BA_ "FlexKomComment" SG_ 948 VC_FCW_SW_CSO "Vehicle configuration - customer settings menu 2 P";
BA_ "GenSigSendType" SG_ 948 VC_EPB_ON_CSO 5;
BA_ "GenSigCycleTime" SG_ 948 VC_EPB_ON_CSO 2000;
BA_ "FlexKomSigStartValue" SG_ 948 VC_EPB_ON_CSO "0300000000000000h";
BA_ "GenSigTimeout_IC" SG_ 948 VC_EPB_ON_CSO 21000;
BA_ "FlexKomSID" SG_ 948 VC_EPB_ON_CSO 2007;
BA_ "FlexKomSigStartPos" SG_ 948 VC_EPB_ON_CSO 7;
BA_ "FlexKomSigLaenge" SG_ 948 VC_EPB_ON_CSO 64;
BA_ "FlexKomSigName" SG_ 948 VC_EPB_ON_CSO "VehCfgCSM2_Pkt";
BA_ "FlexKomIsMotorola" SG_ 948 VC_EPB_ON_CSO 1;
BA_ "GenSigSNA" SG_ 948 VC_EPB_ON_CSO "0h";
BA_ "FlexKomComment" SG_ 948 VC_EPB_ON_CSO "Vehicle configuration - customer settings menu 2 P";
BA_ "GenSigSendType" SG_ 948 VC_AIRBAG_ON_CSO 5;
BA_ "GenSigCycleTime" SG_ 948 VC_AIRBAG_ON_CSO 2000;
BA_ "FlexKomSigStartValue" SG_ 948 VC_AIRBAG_ON_CSO "0300000000000000h";
BA_ "GenSigTimeout_IC" SG_ 948 VC_AIRBAG_ON_CSO 21000;
BA_ "FlexKomSID" SG_ 948 VC_AIRBAG_ON_CSO 2007;
BA_ "FlexKomSigStartPos" SG_ 948 VC_AIRBAG_ON_CSO 7;
BA_ "FlexKomSigLaenge" SG_ 948 VC_AIRBAG_ON_CSO 64;
BA_ "FlexKomSigName" SG_ 948 VC_AIRBAG_ON_CSO "VehCfgCSM2_Pkt";
BA_ "FlexKomIsMotorola" SG_ 948 VC_AIRBAG_ON_CSO 1;
BA_ "GenSigSNA" SG_ 948 VC_AIRBAG_ON_CSO "0h";
BA_ "FlexKomComment" SG_ 948 VC_AIRBAG_ON_CSO "Vehicle configuration - customer settings menu 2 P";
BA_ "GenMsgStartDelayTime" BO_ 947 60;
BA_ "GenMsgStartValue" BO_ 947 "0300000000000000h";
BA_ "GenMsgNrOfRepetitions" BO_ 947 2;
BA_ "GenMsgDelayTime" BO_ 947 20;
BA_ "GenMsgCycleTime" BO_ 947 2000;
BA_ "GenMsgSendType" BO_ 947 5;
BA_ "GenSigSNA" SG_ 947 VC_VehCfgCSO1_Stat "3h";
BA_ "FlexKomIsMotorola" SG_ 947 VC_VehCfgCSO1_Stat 1;
BA_ "FlexKomComment" SG_ 947 VC_VehCfgCSO1_Stat "Vehicle configuration - customer settings menu 1 P";
BA_ "FlexKomSigName" SG_ 947 VC_VehCfgCSO1_Stat "VehCfgCSM1_Pkt";
BA_ "FlexKomSigLaenge" SG_ 947 VC_VehCfgCSO1_Stat 64;
BA_ "FlexKomSigStartPos" SG_ 947 VC_VehCfgCSO1_Stat 7;
BA_ "FlexKomSID" SG_ 947 VC_VehCfgCSO1_Stat 2006;
BA_ "GenSigTimeout_IC" SG_ 947 VC_VehCfgCSO1_Stat 21000;
BA_ "GenSigStartValue" SG_ 947 VC_VehCfgCSO1_Stat 3;
BA_ "FlexKomSigStartValue" SG_ 947 VC_VehCfgCSO1_Stat "0300000000000000h";
BA_ "GenSigCycleTime" SG_ 947 VC_VehCfgCSO1_Stat 2000;
BA_ "GenSigSendType" SG_ 947 VC_VehCfgCSO1_Stat 5;
BA_ "GenSigSNA" SG_ 947 VC_REAR_CMRA_CSO "0h";
BA_ "FlexKomIsMotorola" SG_ 947 VC_REAR_CMRA_CSO 1;
BA_ "FlexKomComment" SG_ 947 VC_REAR_CMRA_CSO "Vehicle configuration - customer settings menu 1 P";
BA_ "FlexKomSigName" SG_ 947 VC_REAR_CMRA_CSO "VehCfgCSM1_Pkt";
BA_ "FlexKomSigLaenge" SG_ 947 VC_REAR_CMRA_CSO 64;
BA_ "FlexKomSigStartPos" SG_ 947 VC_REAR_CMRA_CSO 7;
BA_ "FlexKomSID" SG_ 947 VC_REAR_CMRA_CSO 2006;
BA_ "GenSigTimeout_IC" SG_ 947 VC_REAR_CMRA_CSO 21000;
BA_ "FlexKomSigStartValue" SG_ 947 VC_REAR_CMRA_CSO "0300000000000000h";
BA_ "GenSigCycleTime" SG_ 947 VC_REAR_CMRA_CSO 2000;
BA_ "GenSigSendType" SG_ 947 VC_REAR_CMRA_CSO 5;
BA_ "GenSigSNA" SG_ 947 VC_RAIN_WPR_CSO "0h";
BA_ "FlexKomIsMotorola" SG_ 947 VC_RAIN_WPR_CSO 1;
BA_ "FlexKomComment" SG_ 947 VC_RAIN_WPR_CSO "Vehicle configuration - customer settings menu 1 P";
BA_ "FlexKomSigName" SG_ 947 VC_RAIN_WPR_CSO "VehCfgCSM1_Pkt";
BA_ "FlexKomSigLaenge" SG_ 947 VC_RAIN_WPR_CSO 64;
BA_ "FlexKomSigStartPos" SG_ 947 VC_RAIN_WPR_CSO 7;
BA_ "FlexKomSID" SG_ 947 VC_RAIN_WPR_CSO 2006;
BA_ "GenSigTimeout_IC" SG_ 947 VC_RAIN_WPR_CSO 21000;
BA_ "FlexKomSigStartValue" SG_ 947 VC_RAIN_WPR_CSO "0300000000000000h";
BA_ "GenSigCycleTime" SG_ 947 VC_RAIN_WPR_CSO 2000;
BA_ "GenSigSendType" SG_ 947 VC_RAIN_WPR_CSO 5;
BA_ "GenSigSNA" SG_ 947 VC_PTO_CSO "0h";
BA_ "FlexKomIsMotorola" SG_ 947 VC_PTO_CSO 1;
BA_ "FlexKomComment" SG_ 947 VC_PTO_CSO "Vehicle configuration - customer settings menu 1 P";
BA_ "FlexKomSigName" SG_ 947 VC_PTO_CSO "VehCfgCSM1_Pkt";
BA_ "FlexKomSigLaenge" SG_ 947 VC_PTO_CSO 64;
BA_ "FlexKomSigStartPos" SG_ 947 VC_PTO_CSO 7;
BA_ "FlexKomSID" SG_ 947 VC_PTO_CSO 2006;
BA_ "GenSigTimeout_IC" SG_ 947 VC_PTO_CSO 21000;
BA_ "FlexKomSigStartValue" SG_ 947 VC_PTO_CSO "0300000000000000h";
BA_ "GenSigCycleTime" SG_ 947 VC_PTO_CSO 2000;
BA_ "GenSigSendType" SG_ 947 VC_PTO_CSO 5;
BA_ "GenSigSNA" SG_ 947 VC_PRK_RR_VOL_CSO "0h";
BA_ "FlexKomIsMotorola" SG_ 947 VC_PRK_RR_VOL_CSO 1;
BA_ "FlexKomComment" SG_ 947 VC_PRK_RR_VOL_CSO "Vehicle configuration - customer settings menu 1 P";
BA_ "FlexKomSigName" SG_ 947 VC_PRK_RR_VOL_CSO "VehCfgCSM1_Pkt";
BA_ "FlexKomSigLaenge" SG_ 947 VC_PRK_RR_VOL_CSO 64;
BA_ "FlexKomSigStartPos" SG_ 947 VC_PRK_RR_VOL_CSO 7;
BA_ "FlexKomSID" SG_ 947 VC_PRK_RR_VOL_CSO 2006;
BA_ "GenSigTimeout_IC" SG_ 947 VC_PRK_RR_VOL_CSO 21000;
BA_ "FlexKomSigStartValue" SG_ 947 VC_PRK_RR_VOL_CSO "0300000000000000h";
BA_ "GenSigCycleTime" SG_ 947 VC_PRK_RR_VOL_CSO 2000;
BA_ "GenSigSendType" SG_ 947 VC_PRK_RR_VOL_CSO 5;
BA_ "GenSigSNA" SG_ 947 VC_PRK_FT_VOL_CSO "0h";
BA_ "FlexKomIsMotorola" SG_ 947 VC_PRK_FT_VOL_CSO 1;
BA_ "FlexKomComment" SG_ 947 VC_PRK_FT_VOL_CSO "Vehicle configuration - customer settings menu 1 P";
BA_ "FlexKomSigName" SG_ 947 VC_PRK_FT_VOL_CSO "VehCfgCSM1_Pkt";
BA_ "FlexKomSigLaenge" SG_ 947 VC_PRK_FT_VOL_CSO 64;
BA_ "FlexKomSigStartPos" SG_ 947 VC_PRK_FT_VOL_CSO 7;
BA_ "FlexKomSID" SG_ 947 VC_PRK_FT_VOL_CSO 2006;
BA_ "GenSigTimeout_IC" SG_ 947 VC_PRK_FT_VOL_CSO 21000;
BA_ "FlexKomSigStartValue" SG_ 947 VC_PRK_FT_VOL_CSO "0300000000000000h";
BA_ "GenSigCycleTime" SG_ 947 VC_PRK_FT_VOL_CSO 2000;
BA_ "GenSigSendType" SG_ 947 VC_PRK_FT_VOL_CSO 5;
BA_ "GenSigSNA" SG_ 947 VC_PRK_AST_CSO "0h";
BA_ "FlexKomIsMotorola" SG_ 947 VC_PRK_AST_CSO 1;
BA_ "FlexKomComment" SG_ 947 VC_PRK_AST_CSO "Vehicle configuration - customer settings menu 1 P";
BA_ "FlexKomSigName" SG_ 947 VC_PRK_AST_CSO "VehCfgCSM1_Pkt";
BA_ "FlexKomSigLaenge" SG_ 947 VC_PRK_AST_CSO 64;
BA_ "FlexKomSigStartPos" SG_ 947 VC_PRK_AST_CSO 7;
BA_ "FlexKomSID" SG_ 947 VC_PRK_AST_CSO 2006;
BA_ "GenSigTimeout_IC" SG_ 947 VC_PRK_AST_CSO 21000;
BA_ "FlexKomSigStartValue" SG_ 947 VC_PRK_AST_CSO "0300000000000000h";
BA_ "GenSigCycleTime" SG_ 947 VC_PRK_AST_CSO 2000;
BA_ "GenSigSendType" SG_ 947 VC_PRK_AST_CSO 5;
BA_ "GenSigSNA" SG_ 947 VC_PRK_AST_BRK_CSO "0h";
BA_ "FlexKomIsMotorola" SG_ 947 VC_PRK_AST_BRK_CSO 1;
BA_ "FlexKomComment" SG_ 947 VC_PRK_AST_BRK_CSO "Vehicle configuration - customer settings menu 1 P";
BA_ "FlexKomSigName" SG_ 947 VC_PRK_AST_BRK_CSO "VehCfgCSM1_Pkt";
BA_ "FlexKomSigLaenge" SG_ 947 VC_PRK_AST_BRK_CSO 64;
BA_ "FlexKomSigStartPos" SG_ 947 VC_PRK_AST_BRK_CSO 7;
BA_ "FlexKomSID" SG_ 947 VC_PRK_AST_BRK_CSO 2006;
BA_ "GenSigTimeout_IC" SG_ 947 VC_PRK_AST_BRK_CSO 21000;
BA_ "FlexKomSigStartValue" SG_ 947 VC_PRK_AST_BRK_CSO "0300000000000000h";
BA_ "GenSigCycleTime" SG_ 947 VC_PRK_AST_BRK_CSO 2000;
BA_ "GenSigSendType" SG_ 947 VC_PRK_AST_BRK_CSO 5;
BA_ "GenSigSNA" SG_ 947 VC_PRESSURE_CSO "0h";
BA_ "FlexKomIsMotorola" SG_ 947 VC_PRESSURE_CSO 1;
BA_ "FlexKomComment" SG_ 947 VC_PRESSURE_CSO "Vehicle configuration - customer settings menu 1 P";
BA_ "FlexKomSigName" SG_ 947 VC_PRESSURE_CSO "VehCfgCSM1_Pkt";
BA_ "FlexKomSigLaenge" SG_ 947 VC_PRESSURE_CSO 64;
BA_ "FlexKomSigStartPos" SG_ 947 VC_PRESSURE_CSO 7;
BA_ "FlexKomSID" SG_ 947 VC_PRESSURE_CSO 2006;
BA_ "GenSigTimeout_IC" SG_ 947 VC_PRESSURE_CSO 21000;
BA_ "FlexKomSigStartValue" SG_ 947 VC_PRESSURE_CSO "0300000000000000h";
BA_ "GenSigCycleTime" SG_ 947 VC_PRESSURE_CSO 2000;
BA_ "GenSigSendType" SG_ 947 VC_PRESSURE_CSO 5;
BA_ "GenSigSNA" SG_ 947 VC_POWER_CSO "0h";
BA_ "FlexKomIsMotorola" SG_ 947 VC_POWER_CSO 1;
BA_ "FlexKomComment" SG_ 947 VC_POWER_CSO "Vehicle configuration - customer settings menu 1 P";
BA_ "FlexKomSigName" SG_ 947 VC_POWER_CSO "VehCfgCSM1_Pkt";
BA_ "FlexKomSigLaenge" SG_ 947 VC_POWER_CSO 64;
BA_ "FlexKomSigStartPos" SG_ 947 VC_POWER_CSO 7;
BA_ "FlexKomSID" SG_ 947 VC_POWER_CSO 2006;
BA_ "GenSigTimeout_IC" SG_ 947 VC_POWER_CSO 21000;
BA_ "FlexKomSigStartValue" SG_ 947 VC_POWER_CSO "0300000000000000h";
BA_ "GenSigCycleTime" SG_ 947 VC_POWER_CSO 2000;
BA_ "GenSigSendType" SG_ 947 VC_POWER_CSO 5;
BA_ "GenSigSNA" SG_ 947 VC_POLICE_PE_CSO "0h";
BA_ "FlexKomIsMotorola" SG_ 947 VC_POLICE_PE_CSO 1;
BA_ "FlexKomComment" SG_ 947 VC_POLICE_PE_CSO "Vehicle configuration - customer settings menu 1 P";
BA_ "FlexKomSigName" SG_ 947 VC_POLICE_PE_CSO "VehCfgCSM1_Pkt";
BA_ "FlexKomSigLaenge" SG_ 947 VC_POLICE_PE_CSO 64;
BA_ "FlexKomSigStartPos" SG_ 947 VC_POLICE_PE_CSO 7;
BA_ "FlexKomSID" SG_ 947 VC_POLICE_PE_CSO 2006;
BA_ "GenSigTimeout_IC" SG_ 947 VC_POLICE_PE_CSO 21000;
BA_ "FlexKomSigStartValue" SG_ 947 VC_POLICE_PE_CSO "0300000000000000h";
BA_ "GenSigCycleTime" SG_ 947 VC_POLICE_PE_CSO 2000;
BA_ "GenSigSendType" SG_ 947 VC_POLICE_PE_CSO 5;
BA_ "GenSigSNA" SG_ 947 VC_PLG_CHM_CSO "0h";
BA_ "FlexKomIsMotorola" SG_ 947 VC_PLG_CHM_CSO 1;
BA_ "FlexKomComment" SG_ 947 VC_PLG_CHM_CSO "Vehicle configuration - customer settings menu 1 P";
BA_ "FlexKomSigName" SG_ 947 VC_PLG_CHM_CSO "VehCfgCSM1_Pkt";
BA_ "FlexKomSigLaenge" SG_ 947 VC_PLG_CHM_CSO 64;
BA_ "FlexKomSigStartPos" SG_ 947 VC_PLG_CHM_CSO 7;
BA_ "FlexKomSID" SG_ 947 VC_PLG_CHM_CSO 2006;
BA_ "GenSigTimeout_IC" SG_ 947 VC_PLG_CHM_CSO 21000;
BA_ "FlexKomSigStartValue" SG_ 947 VC_PLG_CHM_CSO "0300000000000000h";
BA_ "GenSigCycleTime" SG_ 947 VC_PLG_CHM_CSO 2000;
BA_ "GenSigSendType" SG_ 947 VC_PLG_CHM_CSO 5;
BA_ "GenSigSNA" SG_ 947 VC_PER_SHFT_RPM_CSO "0h";
BA_ "FlexKomIsMotorola" SG_ 947 VC_PER_SHFT_RPM_CSO 1;
BA_ "FlexKomComment" SG_ 947 VC_PER_SHFT_RPM_CSO "Vehicle configuration - customer settings menu 1 P";
BA_ "FlexKomSigName" SG_ 947 VC_PER_SHFT_RPM_CSO "VehCfgCSM1_Pkt";
BA_ "FlexKomSigLaenge" SG_ 947 VC_PER_SHFT_RPM_CSO 64;
BA_ "FlexKomSigStartPos" SG_ 947 VC_PER_SHFT_RPM_CSO 7;
BA_ "FlexKomSID" SG_ 947 VC_PER_SHFT_RPM_CSO 2006;
BA_ "GenSigTimeout_IC" SG_ 947 VC_PER_SHFT_RPM_CSO 21000;
BA_ "FlexKomSigStartValue" SG_ 947 VC_PER_SHFT_RPM_CSO "0300000000000000h";
BA_ "GenSigCycleTime" SG_ 947 VC_PER_SHFT_RPM_CSO 2000;
BA_ "GenSigSendType" SG_ 947 VC_PER_SHFT_RPM_CSO 5;
BA_ "GenSigSNA" SG_ 947 VC_PER_SHFT_ENBL_CSO "0h";
BA_ "FlexKomIsMotorola" SG_ 947 VC_PER_SHFT_ENBL_CSO 1;
BA_ "FlexKomComment" SG_ 947 VC_PER_SHFT_ENBL_CSO "Vehicle configuration - customer settings menu 1 P";
BA_ "FlexKomSigName" SG_ 947 VC_PER_SHFT_ENBL_CSO "VehCfgCSM1_Pkt";
BA_ "FlexKomSigLaenge" SG_ 947 VC_PER_SHFT_ENBL_CSO 64;
BA_ "FlexKomSigStartPos" SG_ 947 VC_PER_SHFT_ENBL_CSO 7;
BA_ "FlexKomSID" SG_ 947 VC_PER_SHFT_ENBL_CSO 2006;
BA_ "GenSigTimeout_IC" SG_ 947 VC_PER_SHFT_ENBL_CSO 21000;
BA_ "FlexKomSigStartValue" SG_ 947 VC_PER_SHFT_ENBL_CSO "0300000000000000h";
BA_ "GenSigCycleTime" SG_ 947 VC_PER_SHFT_ENBL_CSO 2000;
BA_ "GenSigSendType" SG_ 947 VC_PER_SHFT_ENBL_CSO 5;
BA_ "GenSigSNA" SG_ 947 VC_PE_CSO "0h";
BA_ "FlexKomIsMotorola" SG_ 947 VC_PE_CSO 1;
BA_ "FlexKomComment" SG_ 947 VC_PE_CSO "Vehicle configuration - customer settings menu 1 P";
BA_ "FlexKomSigName" SG_ 947 VC_PE_CSO "VehCfgCSM1_Pkt";
BA_ "FlexKomSigLaenge" SG_ 947 VC_PE_CSO 64;
BA_ "FlexKomSigStartPos" SG_ 947 VC_PE_CSO 7;
BA_ "FlexKomSID" SG_ 947 VC_PE_CSO 2006;
BA_ "GenSigTimeout_IC" SG_ 947 VC_PE_CSO 21000;
BA_ "FlexKomSigStartValue" SG_ 947 VC_PE_CSO "0300000000000000h";
BA_ "GenSigCycleTime" SG_ 947 VC_PE_CSO 2000;
BA_ "GenSigSendType" SG_ 947 VC_PE_CSO 5;
BA_ "GenSigSNA" SG_ 947 VC_NAV_TRN_CSO "0h";
BA_ "FlexKomIsMotorola" SG_ 947 VC_NAV_TRN_CSO 1;
BA_ "FlexKomComment" SG_ 947 VC_NAV_TRN_CSO "Vehicle configuration - customer settings menu 1 P";
BA_ "FlexKomSigName" SG_ 947 VC_NAV_TRN_CSO "VehCfgCSM1_Pkt";
BA_ "FlexKomSigLaenge" SG_ 947 VC_NAV_TRN_CSO 64;
BA_ "FlexKomSigStartPos" SG_ 947 VC_NAV_TRN_CSO 7;
BA_ "FlexKomSID" SG_ 947 VC_NAV_TRN_CSO 2006;
BA_ "GenSigTimeout_IC" SG_ 947 VC_NAV_TRN_CSO 21000;
BA_ "FlexKomSigStartValue" SG_ 947 VC_NAV_TRN_CSO "0300000000000000h";
BA_ "GenSigCycleTime" SG_ 947 VC_NAV_TRN_CSO 2000;
BA_ "GenSigSendType" SG_ 947 VC_NAV_TRN_CSO 5;
BA_ "GenSigSNA" SG_ 947 VC_LGHT_RMT_LWR_CSO "0h";
BA_ "FlexKomIsMotorola" SG_ 947 VC_LGHT_RMT_LWR_CSO 1;
BA_ "FlexKomComment" SG_ 947 VC_LGHT_RMT_LWR_CSO "Vehicle configuration - customer settings menu 1 P";
BA_ "FlexKomSigName" SG_ 947 VC_LGHT_RMT_LWR_CSO "VehCfgCSM1_Pkt";
BA_ "FlexKomSigLaenge" SG_ 947 VC_LGHT_RMT_LWR_CSO 64;
BA_ "FlexKomSigStartPos" SG_ 947 VC_LGHT_RMT_LWR_CSO 7;
BA_ "FlexKomSID" SG_ 947 VC_LGHT_RMT_LWR_CSO 2006;
BA_ "GenSigTimeout_IC" SG_ 947 VC_LGHT_RMT_LWR_CSO 21000;
BA_ "FlexKomSigStartValue" SG_ 947 VC_LGHT_RMT_LWR_CSO "0300000000000000h";
BA_ "GenSigCycleTime" SG_ 947 VC_LGHT_RMT_LWR_CSO 2000;
BA_ "GenSigSendType" SG_ 947 VC_LGHT_RMT_LWR_CSO 5;
BA_ "GenSigSNA" SG_ 947 VC_LDW_WRN_CSO "0h";
BA_ "FlexKomIsMotorola" SG_ 947 VC_LDW_WRN_CSO 1;
BA_ "FlexKomComment" SG_ 947 VC_LDW_WRN_CSO "Vehicle configuration - customer settings menu 1 P";
BA_ "FlexKomSigName" SG_ 947 VC_LDW_WRN_CSO "VehCfgCSM1_Pkt";
BA_ "FlexKomSigLaenge" SG_ 947 VC_LDW_WRN_CSO 64;
BA_ "FlexKomSigStartPos" SG_ 947 VC_LDW_WRN_CSO 7;
BA_ "FlexKomSID" SG_ 947 VC_LDW_WRN_CSO 2006;
BA_ "GenSigTimeout_IC" SG_ 947 VC_LDW_WRN_CSO 21000;
BA_ "FlexKomSigStartValue" SG_ 947 VC_LDW_WRN_CSO "0300000000000000h";
BA_ "GenSigCycleTime" SG_ 947 VC_LDW_WRN_CSO 2000;
BA_ "GenSigSendType" SG_ 947 VC_LDW_WRN_CSO 5;
BA_ "GenSigSNA" SG_ 947 VC_LDW_TRQ_CSO "0h";
BA_ "FlexKomIsMotorola" SG_ 947 VC_LDW_TRQ_CSO 1;
BA_ "FlexKomComment" SG_ 947 VC_LDW_TRQ_CSO "Vehicle configuration - customer settings menu 1 P";
BA_ "FlexKomSigName" SG_ 947 VC_LDW_TRQ_CSO "VehCfgCSM1_Pkt";
BA_ "FlexKomSigLaenge" SG_ 947 VC_LDW_TRQ_CSO 64;
BA_ "FlexKomSigStartPos" SG_ 947 VC_LDW_TRQ_CSO 7;
BA_ "FlexKomSID" SG_ 947 VC_LDW_TRQ_CSO 2006;
BA_ "GenSigTimeout_IC" SG_ 947 VC_LDW_TRQ_CSO 21000;
BA_ "FlexKomSigStartValue" SG_ 947 VC_LDW_TRQ_CSO "0300000000000000h";
BA_ "GenSigCycleTime" SG_ 947 VC_LDW_TRQ_CSO 2000;
BA_ "GenSigSendType" SG_ 947 VC_LDW_TRQ_CSO 5;
BA_ "GenSigSNA" SG_ 947 VC_ILL_APPRCH_CSO "0h";
BA_ "FlexKomIsMotorola" SG_ 947 VC_ILL_APPRCH_CSO 1;
BA_ "FlexKomComment" SG_ 947 VC_ILL_APPRCH_CSO "Vehicle configuration - customer settings menu 1 P";
BA_ "FlexKomSigName" SG_ 947 VC_ILL_APPRCH_CSO "VehCfgCSM1_Pkt";
BA_ "FlexKomSigLaenge" SG_ 947 VC_ILL_APPRCH_CSO 64;
BA_ "FlexKomSigStartPos" SG_ 947 VC_ILL_APPRCH_CSO 7;
BA_ "FlexKomSID" SG_ 947 VC_ILL_APPRCH_CSO 2006;
BA_ "GenSigTimeout_IC" SG_ 947 VC_ILL_APPRCH_CSO 21000;
BA_ "FlexKomSigStartValue" SG_ 947 VC_ILL_APPRCH_CSO "0300000000000000h";
BA_ "GenSigCycleTime" SG_ 947 VC_ILL_APPRCH_CSO 2000;
BA_ "GenSigSendType" SG_ 947 VC_ILL_APPRCH_CSO 5;
BA_ "GenSigSNA" SG_ 947 VC_HSA_CSO "0h";
BA_ "FlexKomIsMotorola" SG_ 947 VC_HSA_CSO 1;
BA_ "FlexKomComment" SG_ 947 VC_HSA_CSO "Vehicle configuration - customer settings menu 1 P";
BA_ "FlexKomSigName" SG_ 947 VC_HSA_CSO "VehCfgCSM1_Pkt";
BA_ "FlexKomSigLaenge" SG_ 947 VC_HSA_CSO 64;
BA_ "FlexKomSigStartPos" SG_ 947 VC_HSA_CSO 7;
BA_ "FlexKomSID" SG_ 947 VC_HSA_CSO 2006;
BA_ "GenSigTimeout_IC" SG_ 947 VC_HSA_CSO 21000;
BA_ "FlexKomSigStartValue" SG_ 947 VC_HSA_CSO "0300000000000000h";
BA_ "GenSigCycleTime" SG_ 947 VC_HSA_CSO 2000;
BA_ "GenSigSendType" SG_ 947 VC_HSA_CSO 5;
BA_ "GenSigSNA" SG_ 947 VC_HRN_RMT_ST_CSO "0h";
BA_ "FlexKomIsMotorola" SG_ 947 VC_HRN_RMT_ST_CSO 1;
BA_ "FlexKomComment" SG_ 947 VC_HRN_RMT_ST_CSO "Vehicle configuration - customer settings menu 1 P";
BA_ "FlexKomSigName" SG_ 947 VC_HRN_RMT_ST_CSO "VehCfgCSM1_Pkt";
BA_ "FlexKomSigLaenge" SG_ 947 VC_HRN_RMT_ST_CSO 64;
BA_ "FlexKomSigStartPos" SG_ 947 VC_HRN_RMT_ST_CSO 7;
BA_ "FlexKomSID" SG_ 947 VC_HRN_RMT_ST_CSO 2006;
BA_ "GenSigTimeout_IC" SG_ 947 VC_HRN_RMT_ST_CSO 21000;
BA_ "FlexKomSigStartValue" SG_ 947 VC_HRN_RMT_ST_CSO "0300000000000000h";
BA_ "GenSigCycleTime" SG_ 947 VC_HRN_RMT_ST_CSO 2000;
BA_ "GenSigSendType" SG_ 947 VC_HRN_RMT_ST_CSO 5;
BA_ "GenSigSNA" SG_ 947 VC_HRN_RMT_LWR_CSO "0h";
BA_ "FlexKomIsMotorola" SG_ 947 VC_HRN_RMT_LWR_CSO 1;
BA_ "FlexKomComment" SG_ 947 VC_HRN_RMT_LWR_CSO "Vehicle configuration - customer settings menu 1 P";
BA_ "FlexKomSigName" SG_ 947 VC_HRN_RMT_LWR_CSO "VehCfgCSM1_Pkt";
BA_ "FlexKomSigLaenge" SG_ 947 VC_HRN_RMT_LWR_CSO 64;
BA_ "FlexKomSigStartPos" SG_ 947 VC_HRN_RMT_LWR_CSO 7;
BA_ "FlexKomSID" SG_ 947 VC_HRN_RMT_LWR_CSO 2006;
BA_ "GenSigTimeout_IC" SG_ 947 VC_HRN_RMT_LWR_CSO 21000;
BA_ "FlexKomSigStartValue" SG_ 947 VC_HRN_RMT_LWR_CSO "0300000000000000h";
BA_ "GenSigCycleTime" SG_ 947 VC_HRN_RMT_LWR_CSO 2000;
BA_ "GenSigSendType" SG_ 947 VC_HRN_RMT_LWR_CSO 5;
BA_ "GenSigSNA" SG_ 947 VC_HRN_RMT_LK_CSO "0h";
BA_ "FlexKomIsMotorola" SG_ 947 VC_HRN_RMT_LK_CSO 1;
BA_ "FlexKomComment" SG_ 947 VC_HRN_RMT_LK_CSO "Vehicle configuration - customer settings menu 1 P";
BA_ "FlexKomSigName" SG_ 947 VC_HRN_RMT_LK_CSO "VehCfgCSM1_Pkt";
BA_ "FlexKomSigLaenge" SG_ 947 VC_HRN_RMT_LK_CSO 64;
BA_ "FlexKomSigStartPos" SG_ 947 VC_HRN_RMT_LK_CSO 7;
BA_ "FlexKomSID" SG_ 947 VC_HRN_RMT_LK_CSO 2006;
BA_ "GenSigTimeout_IC" SG_ 947 VC_HRN_RMT_LK_CSO 21000;
BA_ "FlexKomSigStartValue" SG_ 947 VC_HRN_RMT_LK_CSO "0300000000000000h";
BA_ "GenSigCycleTime" SG_ 947 VC_HRN_RMT_LK_CSO 2000;
BA_ "GenSigSendType" SG_ 947 VC_HRN_RMT_LK_CSO 5;
BA_ "GenSigSNA" SG_ 947 VC_HL_WPR_CSO "0h";
BA_ "FlexKomIsMotorola" SG_ 947 VC_HL_WPR_CSO 1;
BA_ "FlexKomComment" SG_ 947 VC_HL_WPR_CSO "Vehicle configuration - customer settings menu 1 P";
BA_ "FlexKomSigName" SG_ 947 VC_HL_WPR_CSO "VehCfgCSM1_Pkt";
BA_ "FlexKomSigLaenge" SG_ 947 VC_HL_WPR_CSO 64;
BA_ "FlexKomSigStartPos" SG_ 947 VC_HL_WPR_CSO 7;
BA_ "FlexKomSID" SG_ 947 VC_HL_WPR_CSO 2006;
BA_ "GenSigTimeout_IC" SG_ 947 VC_HL_WPR_CSO 21000;
BA_ "FlexKomSigStartValue" SG_ 947 VC_HL_WPR_CSO "0300000000000000h";
BA_ "GenSigCycleTime" SG_ 947 VC_HL_WPR_CSO 2000;
BA_ "GenSigSendType" SG_ 947 VC_HL_WPR_CSO 5;
BA_ "GenSigSNA" SG_ 947 VC_HL_OFF_DLY_CSO "0h";
BA_ "FlexKomIsMotorola" SG_ 947 VC_HL_OFF_DLY_CSO 1;
BA_ "FlexKomComment" SG_ 947 VC_HL_OFF_DLY_CSO "Vehicle configuration - customer settings menu 1 P";
BA_ "FlexKomSigName" SG_ 947 VC_HL_OFF_DLY_CSO "VehCfgCSM1_Pkt";
BA_ "FlexKomSigLaenge" SG_ 947 VC_HL_OFF_DLY_CSO 64;
BA_ "FlexKomSigStartPos" SG_ 947 VC_HL_OFF_DLY_CSO 7;
BA_ "FlexKomSID" SG_ 947 VC_HL_OFF_DLY_CSO 2006;
BA_ "GenSigTimeout_IC" SG_ 947 VC_HL_OFF_DLY_CSO 21000;
BA_ "FlexKomSigStartValue" SG_ 947 VC_HL_OFF_DLY_CSO "0300000000000000h";
BA_ "GenSigCycleTime" SG_ 947 VC_HL_OFF_DLY_CSO 2000;
BA_ "GenSigSendType" SG_ 947 VC_HL_OFF_DLY_CSO 5;
BA_ "GenSigSNA" SG_ 947 VC_HL_DRP_CSO "0h";
BA_ "FlexKomIsMotorola" SG_ 947 VC_HL_DRP_CSO 1;
BA_ "FlexKomComment" SG_ 947 VC_HL_DRP_CSO "Vehicle configuration - customer settings menu 1 P";
BA_ "FlexKomSigName" SG_ 947 VC_HL_DRP_CSO "VehCfgCSM1_Pkt";
BA_ "FlexKomSigLaenge" SG_ 947 VC_HL_DRP_CSO 64;
BA_ "FlexKomSigStartPos" SG_ 947 VC_HL_DRP_CSO 7;
BA_ "FlexKomSID" SG_ 947 VC_HL_DRP_CSO 2006;
BA_ "GenSigTimeout_IC" SG_ 947 VC_HL_DRP_CSO 21000;
BA_ "FlexKomSigStartValue" SG_ 947 VC_HL_DRP_CSO "0300000000000000h";
BA_ "GenSigCycleTime" SG_ 947 VC_HL_DRP_CSO 2000;
BA_ "GenSigSendType" SG_ 947 VC_HL_DRP_CSO 5;
BA_ "GenSigSNA" SG_ 947 VC_FLSH_LMP_LK_CSO "0h";
BA_ "FlexKomIsMotorola" SG_ 947 VC_FLSH_LMP_LK_CSO 1;
BA_ "FlexKomComment" SG_ 947 VC_FLSH_LMP_LK_CSO "Vehicle configuration - customer settings menu 1 P";
BA_ "FlexKomSigName" SG_ 947 VC_FLSH_LMP_LK_CSO "VehCfgCSM1_Pkt";
BA_ "FlexKomSigLaenge" SG_ 947 VC_FLSH_LMP_LK_CSO 64;
BA_ "FlexKomSigStartPos" SG_ 947 VC_FLSH_LMP_LK_CSO 7;
BA_ "FlexKomSID" SG_ 947 VC_FLSH_LMP_LK_CSO 2006;
BA_ "GenSigTimeout_IC" SG_ 947 VC_FLSH_LMP_LK_CSO 21000;
BA_ "FlexKomSigStartValue" SG_ 947 VC_FLSH_LMP_LK_CSO "0300000000000000h";
BA_ "GenSigCycleTime" SG_ 947 VC_FLSH_LMP_LK_CSO 2000;
BA_ "GenSigSendType" SG_ 947 VC_FLSH_LMP_LK_CSO 5;
BA_ "GenSigSNA" SG_ 947 VC_FCW_CSO "0h";
BA_ "FlexKomIsMotorola" SG_ 947 VC_FCW_CSO 1;
BA_ "FlexKomComment" SG_ 947 VC_FCW_CSO "Vehicle configuration - customer settings menu 1 P";
BA_ "FlexKomSigName" SG_ 947 VC_FCW_CSO "VehCfgCSM1_Pkt";
BA_ "FlexKomSigLaenge" SG_ 947 VC_FCW_CSO 64;
BA_ "FlexKomSigStartPos" SG_ 947 VC_FCW_CSO 7;
BA_ "FlexKomSID" SG_ 947 VC_FCW_CSO 2006;
BA_ "GenSigTimeout_IC" SG_ 947 VC_FCW_CSO 21000;
BA_ "FlexKomSigStartValue" SG_ 947 VC_FCW_CSO "0300000000000000h";
BA_ "GenSigCycleTime" SG_ 947 VC_FCW_CSO 2000;
BA_ "GenSigSendType" SG_ 947 VC_FCW_CSO 5;
BA_ "GenSigSNA" SG_ 947 VC_FCW_BRK_CSO "0h";
BA_ "FlexKomIsMotorola" SG_ 947 VC_FCW_BRK_CSO 1;
BA_ "FlexKomComment" SG_ 947 VC_FCW_BRK_CSO "Vehicle configuration - customer settings menu 1 P";
BA_ "FlexKomSigName" SG_ 947 VC_FCW_BRK_CSO "VehCfgCSM1_Pkt";
BA_ "FlexKomSigLaenge" SG_ 947 VC_FCW_BRK_CSO 64;
BA_ "FlexKomSigStartPos" SG_ 947 VC_FCW_BRK_CSO 7;
BA_ "FlexKomSID" SG_ 947 VC_FCW_BRK_CSO 2006;
BA_ "GenSigTimeout_IC" SG_ 947 VC_FCW_BRK_CSO 21000;
BA_ "FlexKomSigStartValue" SG_ 947 VC_FCW_BRK_CSO "0300000000000000h";
BA_ "GenSigCycleTime" SG_ 947 VC_FCW_BRK_CSO 2000;
BA_ "GenSigSendType" SG_ 947 VC_FCW_BRK_CSO 5;
BA_ "GenSigSNA" SG_ 947 VC_EPS_CSO "0h";
BA_ "FlexKomIsMotorola" SG_ 947 VC_EPS_CSO 1;
BA_ "FlexKomComment" SG_ 947 VC_EPS_CSO "Vehicle configuration - customer settings menu 1 P";
BA_ "FlexKomSigName" SG_ 947 VC_EPS_CSO "VehCfgCSM1_Pkt";
BA_ "FlexKomSigLaenge" SG_ 947 VC_EPS_CSO 64;
BA_ "FlexKomSigStartPos" SG_ 947 VC_EPS_CSO 7;
BA_ "FlexKomSID" SG_ 947 VC_EPS_CSO 2006;
BA_ "GenSigTimeout_IC" SG_ 947 VC_EPS_CSO 21000;
BA_ "FlexKomSigStartValue" SG_ 947 VC_EPS_CSO "0300000000000000h";
BA_ "GenSigCycleTime" SG_ 947 VC_EPS_CSO 2000;
BA_ "GenSigSendType" SG_ 947 VC_EPS_CSO 5;
BA_ "GenSigSNA" SG_ 947 VC_EPB_SERV_CSO "0h";
BA_ "FlexKomIsMotorola" SG_ 947 VC_EPB_SERV_CSO 1;
BA_ "FlexKomComment" SG_ 947 VC_EPB_SERV_CSO "Vehicle configuration - customer settings menu 1 P";
BA_ "FlexKomSigName" SG_ 947 VC_EPB_SERV_CSO "VehCfgCSM1_Pkt";
BA_ "FlexKomSigLaenge" SG_ 947 VC_EPB_SERV_CSO 64;
BA_ "FlexKomSigStartPos" SG_ 947 VC_EPB_SERV_CSO 7;
BA_ "FlexKomSID" SG_ 947 VC_EPB_SERV_CSO 2006;
BA_ "GenSigTimeout_IC" SG_ 947 VC_EPB_SERV_CSO 21000;
BA_ "FlexKomSigStartValue" SG_ 947 VC_EPB_SERV_CSO "0300000000000000h";
BA_ "GenSigCycleTime" SG_ 947 VC_EPB_SERV_CSO 2000;
BA_ "GenSigSendType" SG_ 947 VC_EPB_SERV_CSO 5;
BA_ "GenSigSNA" SG_ 947 VC_ENTRY_EXIT_CSO "0h";
BA_ "FlexKomIsMotorola" SG_ 947 VC_ENTRY_EXIT_CSO 1;
BA_ "FlexKomComment" SG_ 947 VC_ENTRY_EXIT_CSO "Vehicle configuration - customer settings menu 1 P";
BA_ "FlexKomSigName" SG_ 947 VC_ENTRY_EXIT_CSO "VehCfgCSM1_Pkt";
BA_ "FlexKomSigLaenge" SG_ 947 VC_ENTRY_EXIT_CSO 64;
BA_ "FlexKomSigStartPos" SG_ 947 VC_ENTRY_EXIT_CSO 7;
BA_ "FlexKomSID" SG_ 947 VC_ENTRY_EXIT_CSO 2006;
BA_ "GenSigTimeout_IC" SG_ 947 VC_ENTRY_EXIT_CSO 21000;
BA_ "FlexKomSigStartValue" SG_ 947 VC_ENTRY_EXIT_CSO "0300000000000000h";
BA_ "GenSigCycleTime" SG_ 947 VC_ENTRY_EXIT_CSO 2000;
BA_ "GenSigSendType" SG_ 947 VC_ENTRY_EXIT_CSO 5;
BA_ "GenSigSNA" SG_ 947 VC_EASY_EXIT_CSO "0h";
BA_ "FlexKomIsMotorola" SG_ 947 VC_EASY_EXIT_CSO 1;
BA_ "FlexKomComment" SG_ 947 VC_EASY_EXIT_CSO "Vehicle configuration - customer settings menu 1 P";
BA_ "FlexKomSigName" SG_ 947 VC_EASY_EXIT_CSO "VehCfgCSM1_Pkt";
BA_ "FlexKomSigLaenge" SG_ 947 VC_EASY_EXIT_CSO 64;
BA_ "FlexKomSigStartPos" SG_ 947 VC_EASY_EXIT_CSO 7;
BA_ "FlexKomSID" SG_ 947 VC_EASY_EXIT_CSO 2006;
BA_ "GenSigTimeout_IC" SG_ 947 VC_EASY_EXIT_CSO 21000;
BA_ "FlexKomSigStartValue" SG_ 947 VC_EASY_EXIT_CSO "0300000000000000h";
BA_ "GenSigCycleTime" SG_ 947 VC_EASY_EXIT_CSO 2000;
BA_ "GenSigSendType" SG_ 947 VC_EASY_EXIT_CSO 5;
BA_ "GenSigSNA" SG_ 947 VC_DRL_CSO "0h";
BA_ "FlexKomIsMotorola" SG_ 947 VC_DRL_CSO 1;
BA_ "FlexKomComment" SG_ 947 VC_DRL_CSO "Vehicle configuration - customer settings menu 1 P";
BA_ "FlexKomSigName" SG_ 947 VC_DRL_CSO "VehCfgCSM1_Pkt";
BA_ "FlexKomSigLaenge" SG_ 947 VC_DRL_CSO 64;
BA_ "FlexKomSigStartPos" SG_ 947 VC_DRL_CSO 7;
BA_ "FlexKomSID" SG_ 947 VC_DRL_CSO 2006;
BA_ "GenSigTimeout_IC" SG_ 947 VC_DRL_CSO 21000;
BA_ "FlexKomSigStartValue" SG_ 947 VC_DRL_CSO "0300000000000000h";
BA_ "GenSigCycleTime" SG_ 947 VC_DRL_CSO 2000;
BA_ "GenSigSendType" SG_ 947 VC_DRL_CSO 5;
BA_ "GenSigSNA" SG_ 947 VC_DR_UNLK_CSO "0h";
BA_ "FlexKomIsMotorola" SG_ 947 VC_DR_UNLK_CSO 1;
BA_ "FlexKomComment" SG_ 947 VC_DR_UNLK_CSO "Vehicle configuration - customer settings menu 1 P";
BA_ "FlexKomSigName" SG_ 947 VC_DR_UNLK_CSO "VehCfgCSM1_Pkt";
BA_ "FlexKomSigLaenge" SG_ 947 VC_DR_UNLK_CSO 64;
BA_ "FlexKomSigStartPos" SG_ 947 VC_DR_UNLK_CSO 7;
BA_ "FlexKomSID" SG_ 947 VC_DR_UNLK_CSO 2006;
BA_ "GenSigTimeout_IC" SG_ 947 VC_DR_UNLK_CSO 21000;
BA_ "FlexKomSigStartValue" SG_ 947 VC_DR_UNLK_CSO "0300000000000000h";
BA_ "GenSigCycleTime" SG_ 947 VC_DR_UNLK_CSO 2000;
BA_ "GenSigSendType" SG_ 947 VC_DR_UNLK_CSO 5;
BA_ "GenSigSNA" SG_ 947 VC_DR_LK_CSO "0h";
BA_ "FlexKomIsMotorola" SG_ 947 VC_DR_LK_CSO 1;
BA_ "FlexKomComment" SG_ 947 VC_DR_LK_CSO "Vehicle configuration - customer settings menu 1 P";
BA_ "FlexKomSigName" SG_ 947 VC_DR_LK_CSO "VehCfgCSM1_Pkt";
BA_ "FlexKomSigLaenge" SG_ 947 VC_DR_LK_CSO 64;
BA_ "FlexKomSigStartPos" SG_ 947 VC_DR_LK_CSO 7;
BA_ "FlexKomSID" SG_ 947 VC_DR_LK_CSO 2006;
BA_ "GenSigTimeout_IC" SG_ 947 VC_DR_LK_CSO 21000;
BA_ "FlexKomSigStartValue" SG_ 947 VC_DR_LK_CSO "0300000000000000h";
BA_ "GenSigCycleTime" SG_ 947 VC_DR_LK_CSO 2000;
BA_ "GenSigSendType" SG_ 947 VC_DR_LK_CSO 5;
BA_ "GenSigSNA" SG_ 947 VC_DISTANCE_CSO "0h";
BA_ "FlexKomIsMotorola" SG_ 947 VC_DISTANCE_CSO 1;
BA_ "FlexKomComment" SG_ 947 VC_DISTANCE_CSO "Vehicle configuration - customer settings menu 1 P";
BA_ "FlexKomSigName" SG_ 947 VC_DISTANCE_CSO "VehCfgCSM1_Pkt";
BA_ "FlexKomSigLaenge" SG_ 947 VC_DISTANCE_CSO 64;
BA_ "FlexKomSigStartPos" SG_ 947 VC_DISTANCE_CSO 7;
BA_ "FlexKomSID" SG_ 947 VC_DISTANCE_CSO 2006;
BA_ "GenSigTimeout_IC" SG_ 947 VC_DISTANCE_CSO 21000;
BA_ "FlexKomSigStartValue" SG_ 947 VC_DISTANCE_CSO "0300000000000000h";
BA_ "GenSigCycleTime" SG_ 947 VC_DISTANCE_CSO 2000;
BA_ "GenSigSendType" SG_ 947 VC_DISTANCE_CSO 5;
BA_ "GenSigSNA" SG_ 947 VC_DCS_CSO "0h";
BA_ "FlexKomIsMotorola" SG_ 947 VC_DCS_CSO 1;
BA_ "FlexKomComment" SG_ 947 VC_DCS_CSO "Vehicle configuration - customer settings menu 1 P";
BA_ "FlexKomSigName" SG_ 947 VC_DCS_CSO "VehCfgCSM1_Pkt";
BA_ "FlexKomSigLaenge" SG_ 947 VC_DCS_CSO 64;
BA_ "FlexKomSigStartPos" SG_ 947 VC_DCS_CSO 7;
BA_ "FlexKomSID" SG_ 947 VC_DCS_CSO 2006;
BA_ "GenSigTimeout_IC" SG_ 947 VC_DCS_CSO 21000;
BA_ "FlexKomSigStartValue" SG_ 947 VC_DCS_CSO "0300000000000000h";
BA_ "GenSigCycleTime" SG_ 947 VC_DCS_CSO 2000;
BA_ "GenSigSendType" SG_ 947 VC_DCS_CSO 5;
BA_ "GenSigSNA" SG_ 947 VC_CONS_CSO "0h";
BA_ "FlexKomIsMotorola" SG_ 947 VC_CONS_CSO 1;
BA_ "FlexKomComment" SG_ 947 VC_CONS_CSO "Vehicle configuration - customer settings menu 1 P";
BA_ "FlexKomSigName" SG_ 947 VC_CONS_CSO "VehCfgCSM1_Pkt";
BA_ "FlexKomSigLaenge" SG_ 947 VC_CONS_CSO 64;
BA_ "FlexKomSigStartPos" SG_ 947 VC_CONS_CSO 7;
BA_ "FlexKomSID" SG_ 947 VC_CONS_CSO 2006;
BA_ "GenSigTimeout_IC" SG_ 947 VC_CONS_CSO 21000;
BA_ "FlexKomSigStartValue" SG_ 947 VC_CONS_CSO "0300000000000000h";
BA_ "GenSigCycleTime" SG_ 947 VC_CONS_CSO 2000;
BA_ "GenSigSendType" SG_ 947 VC_CONS_CSO 5;
BA_ "GenSigSNA" SG_ 947 VC_CMRA_GRDLNS_CSO "0h";
BA_ "FlexKomIsMotorola" SG_ 947 VC_CMRA_GRDLNS_CSO 1;
BA_ "FlexKomComment" SG_ 947 VC_CMRA_GRDLNS_CSO "Vehicle configuration - customer settings menu 1 P";
BA_ "FlexKomSigName" SG_ 947 VC_CMRA_GRDLNS_CSO "VehCfgCSM1_Pkt";
BA_ "FlexKomSigLaenge" SG_ 947 VC_CMRA_GRDLNS_CSO 64;
BA_ "FlexKomSigStartPos" SG_ 947 VC_CMRA_GRDLNS_CSO 7;
BA_ "FlexKomSID" SG_ 947 VC_CMRA_GRDLNS_CSO 2006;
BA_ "GenSigTimeout_IC" SG_ 947 VC_CMRA_GRDLNS_CSO 21000;
BA_ "FlexKomSigStartValue" SG_ 947 VC_CMRA_GRDLNS_CSO "0300000000000000h";
BA_ "GenSigCycleTime" SG_ 947 VC_CMRA_GRDLNS_CSO 2000;
BA_ "GenSigSendType" SG_ 947 VC_CMRA_GRDLNS_CSO 5;
BA_ "GenSigSNA" SG_ 947 VC_CMP_VAR_CSO "0h";
BA_ "FlexKomIsMotorola" SG_ 947 VC_CMP_VAR_CSO 1;
BA_ "FlexKomComment" SG_ 947 VC_CMP_VAR_CSO "Vehicle configuration - customer settings menu 1 P";
BA_ "FlexKomSigName" SG_ 947 VC_CMP_VAR_CSO "VehCfgCSM1_Pkt";
BA_ "FlexKomSigLaenge" SG_ 947 VC_CMP_VAR_CSO 64;
BA_ "FlexKomSigStartPos" SG_ 947 VC_CMP_VAR_CSO 7;
BA_ "FlexKomSID" SG_ 947 VC_CMP_VAR_CSO 2006;
BA_ "GenSigTimeout_IC" SG_ 947 VC_CMP_VAR_CSO 21000;
BA_ "FlexKomSigStartValue" SG_ 947 VC_CMP_VAR_CSO "0300000000000000h";
BA_ "GenSigCycleTime" SG_ 947 VC_CMP_VAR_CSO 2000;
BA_ "GenSigSendType" SG_ 947 VC_CMP_VAR_CSO 5;
BA_ "GenSigSNA" SG_ 947 VC_CMP_CAL_CSO "0h";
BA_ "FlexKomIsMotorola" SG_ 947 VC_CMP_CAL_CSO 1;
BA_ "FlexKomComment" SG_ 947 VC_CMP_CAL_CSO "Vehicle configuration - customer settings menu 1 P";
BA_ "FlexKomSigName" SG_ 947 VC_CMP_CAL_CSO "VehCfgCSM1_Pkt";
BA_ "FlexKomSigLaenge" SG_ 947 VC_CMP_CAL_CSO 64;
BA_ "FlexKomSigStartPos" SG_ 947 VC_CMP_CAL_CSO 7;
BA_ "FlexKomSID" SG_ 947 VC_CMP_CAL_CSO 2006;
BA_ "GenSigTimeout_IC" SG_ 947 VC_CMP_CAL_CSO 21000;
BA_ "FlexKomSigStartValue" SG_ 947 VC_CMP_CAL_CSO "0300000000000000h";
BA_ "GenSigCycleTime" SG_ 947 VC_CMP_CAL_CSO 2000;
BA_ "GenSigSendType" SG_ 947 VC_CMP_CAL_CSO 5;
BA_ "GenSigSNA" SG_ 947 VC_CLK_DSP_CSO "0h";
BA_ "FlexKomIsMotorola" SG_ 947 VC_CLK_DSP_CSO 1;
BA_ "FlexKomComment" SG_ 947 VC_CLK_DSP_CSO "Vehicle configuration - customer settings menu 1 P";
BA_ "FlexKomSigName" SG_ 947 VC_CLK_DSP_CSO "VehCfgCSM1_Pkt";
BA_ "FlexKomSigLaenge" SG_ 947 VC_CLK_DSP_CSO 64;
BA_ "FlexKomSigStartPos" SG_ 947 VC_CLK_DSP_CSO 7;
BA_ "FlexKomSID" SG_ 947 VC_CLK_DSP_CSO 2006;
BA_ "GenSigTimeout_IC" SG_ 947 VC_CLK_DSP_CSO 21000;
BA_ "FlexKomSigStartValue" SG_ 947 VC_CLK_DSP_CSO "0300000000000000h";
BA_ "GenSigCycleTime" SG_ 947 VC_CLK_DSP_CSO 2000;
BA_ "GenSigSendType" SG_ 947 VC_CLK_DSP_CSO 5;
BA_ "GenSigSNA" SG_ 947 VC_CHMSL_LINE_CSO "0h";
BA_ "FlexKomIsMotorola" SG_ 947 VC_CHMSL_LINE_CSO 1;
BA_ "FlexKomComment" SG_ 947 VC_CHMSL_LINE_CSO "Vehicle configuration - customer settings menu 1 P";
BA_ "FlexKomSigName" SG_ 947 VC_CHMSL_LINE_CSO "VehCfgCSM1_Pkt";
BA_ "FlexKomSigLaenge" SG_ 947 VC_CHMSL_LINE_CSO 64;
BA_ "FlexKomSigStartPos" SG_ 947 VC_CHMSL_LINE_CSO 7;
BA_ "FlexKomSID" SG_ 947 VC_CHMSL_LINE_CSO 2006;
BA_ "GenSigTimeout_IC" SG_ 947 VC_CHMSL_LINE_CSO 21000;
BA_ "FlexKomSigStartValue" SG_ 947 VC_CHMSL_LINE_CSO "0300000000000000h";
BA_ "GenSigCycleTime" SG_ 947 VC_CHMSL_LINE_CSO 2000;
BA_ "GenSigSendType" SG_ 947 VC_CHMSL_LINE_CSO 5;
BA_ "GenSigSNA" SG_ 947 VC_CAPACITY_CSO "0h";
BA_ "FlexKomIsMotorola" SG_ 947 VC_CAPACITY_CSO 1;
BA_ "FlexKomComment" SG_ 947 VC_CAPACITY_CSO "Vehicle configuration - customer settings menu 1 P";
BA_ "FlexKomSigName" SG_ 947 VC_CAPACITY_CSO "VehCfgCSM1_Pkt";
BA_ "FlexKomSigLaenge" SG_ 947 VC_CAPACITY_CSO 64;
BA_ "FlexKomSigStartPos" SG_ 947 VC_CAPACITY_CSO 7;
BA_ "FlexKomSID" SG_ 947 VC_CAPACITY_CSO 2006;
BA_ "GenSigTimeout_IC" SG_ 947 VC_CAPACITY_CSO 21000;
BA_ "FlexKomSigStartValue" SG_ 947 VC_CAPACITY_CSO "0300000000000000h";
BA_ "GenSigCycleTime" SG_ 947 VC_CAPACITY_CSO 2000;
BA_ "GenSigSendType" SG_ 947 VC_CAPACITY_CSO 5;
BA_ "GenSigSNA" SG_ 947 VC_BLIND_SPOT_CSO "0h";
BA_ "FlexKomIsMotorola" SG_ 947 VC_BLIND_SPOT_CSO 1;
BA_ "FlexKomComment" SG_ 947 VC_BLIND_SPOT_CSO "Vehicle configuration - customer settings menu 1 P";
BA_ "FlexKomSigName" SG_ 947 VC_BLIND_SPOT_CSO "VehCfgCSM1_Pkt";
BA_ "FlexKomSigLaenge" SG_ 947 VC_BLIND_SPOT_CSO 64;
BA_ "FlexKomSigStartPos" SG_ 947 VC_BLIND_SPOT_CSO 7;
BA_ "FlexKomSID" SG_ 947 VC_BLIND_SPOT_CSO 2006;
BA_ "GenSigTimeout_IC" SG_ 947 VC_BLIND_SPOT_CSO 21000;
BA_ "FlexKomSigStartValue" SG_ 947 VC_BLIND_SPOT_CSO "0300000000000000h";
BA_ "GenSigCycleTime" SG_ 947 VC_BLIND_SPOT_CSO 2000;
BA_ "GenSigSendType" SG_ 947 VC_BLIND_SPOT_CSO 5;
BA_ "GenSigSNA" SG_ 947 VC_AUX_SWS_CSO "0h";
BA_ "FlexKomIsMotorola" SG_ 947 VC_AUX_SWS_CSO 1;
BA_ "FlexKomComment" SG_ 947 VC_AUX_SWS_CSO "Vehicle configuration - customer settings menu 1 P";
BA_ "FlexKomSigName" SG_ 947 VC_AUX_SWS_CSO "VehCfgCSM1_Pkt";
BA_ "FlexKomSigLaenge" SG_ 947 VC_AUX_SWS_CSO 64;
BA_ "FlexKomSigStartPos" SG_ 947 VC_AUX_SWS_CSO 7;
BA_ "FlexKomSID" SG_ 947 VC_AUX_SWS_CSO 2006;
BA_ "GenSigTimeout_IC" SG_ 947 VC_AUX_SWS_CSO 21000;
BA_ "FlexKomSigStartValue" SG_ 947 VC_AUX_SWS_CSO "0300000000000000h";
BA_ "GenSigCycleTime" SG_ 947 VC_AUX_SWS_CSO 2000;
BA_ "GenSigSendType" SG_ 947 VC_AUX_SWS_CSO 5;
BA_ "GenSigSNA" SG_ 947 VC_AUTO_PRK_CSO "0h";
BA_ "FlexKomIsMotorola" SG_ 947 VC_AUTO_PRK_CSO 1;
BA_ "FlexKomComment" SG_ 947 VC_AUTO_PRK_CSO "Vehicle configuration - customer settings menu 1 P";
BA_ "FlexKomSigName" SG_ 947 VC_AUTO_PRK_CSO "VehCfgCSM1_Pkt";
BA_ "FlexKomSigLaenge" SG_ 947 VC_AUTO_PRK_CSO 64;
BA_ "FlexKomSigStartPos" SG_ 947 VC_AUTO_PRK_CSO 7;
BA_ "FlexKomSID" SG_ 947 VC_AUTO_PRK_CSO 2006;
BA_ "GenSigTimeout_IC" SG_ 947 VC_AUTO_PRK_CSO 21000;
BA_ "FlexKomSigStartValue" SG_ 947 VC_AUTO_PRK_CSO "0300000000000000h";
BA_ "GenSigCycleTime" SG_ 947 VC_AUTO_PRK_CSO 2000;
BA_ "GenSigSendType" SG_ 947 VC_AUTO_PRK_CSO 5;
BA_ "GenSigSNA" SG_ 947 VC_AUTO_HB_CSO "0h";
BA_ "FlexKomIsMotorola" SG_ 947 VC_AUTO_HB_CSO 1;
BA_ "FlexKomComment" SG_ 947 VC_AUTO_HB_CSO "Vehicle configuration - customer settings menu 1 P";
BA_ "FlexKomSigName" SG_ 947 VC_AUTO_HB_CSO "VehCfgCSM1_Pkt";
BA_ "FlexKomSigLaenge" SG_ 947 VC_AUTO_HB_CSO 64;
BA_ "FlexKomSigStartPos" SG_ 947 VC_AUTO_HB_CSO 7;
BA_ "FlexKomSID" SG_ 947 VC_AUTO_HB_CSO 2006;
BA_ "GenSigTimeout_IC" SG_ 947 VC_AUTO_HB_CSO 21000;
BA_ "FlexKomSigStartValue" SG_ 947 VC_AUTO_HB_CSO "0300000000000000h";
BA_ "GenSigCycleTime" SG_ 947 VC_AUTO_HB_CSO 2000;
BA_ "GenSigSendType" SG_ 947 VC_AUTO_HB_CSO 5;
BA_ "GenSigSNA" SG_ 947 VC_AUTO_AERO_CSO "0h";
BA_ "FlexKomIsMotorola" SG_ 947 VC_AUTO_AERO_CSO 1;
BA_ "FlexKomComment" SG_ 947 VC_AUTO_AERO_CSO "Vehicle configuration - customer settings menu 1 P";
BA_ "FlexKomSigName" SG_ 947 VC_AUTO_AERO_CSO "VehCfgCSM1_Pkt";
BA_ "FlexKomSigLaenge" SG_ 947 VC_AUTO_AERO_CSO 64;
BA_ "FlexKomSigStartPos" SG_ 947 VC_AUTO_AERO_CSO 7;
BA_ "FlexKomSID" SG_ 947 VC_AUTO_AERO_CSO 2006;
BA_ "GenSigTimeout_IC" SG_ 947 VC_AUTO_AERO_CSO 21000;
BA_ "FlexKomSigStartValue" SG_ 947 VC_AUTO_AERO_CSO "0300000000000000h";
BA_ "GenSigCycleTime" SG_ 947 VC_AUTO_AERO_CSO 2000;
BA_ "GenSigSendType" SG_ 947 VC_AUTO_AERO_CSO 5;
BA_ "GenSigSNA" SG_ 947 VC_ASCM_WRN_CSO "0h";
BA_ "FlexKomIsMotorola" SG_ 947 VC_ASCM_WRN_CSO 1;
BA_ "FlexKomComment" SG_ 947 VC_ASCM_WRN_CSO "Vehicle configuration - customer settings menu 1 P";
BA_ "FlexKomSigName" SG_ 947 VC_ASCM_WRN_CSO "VehCfgCSM1_Pkt";
BA_ "FlexKomSigLaenge" SG_ 947 VC_ASCM_WRN_CSO 64;
BA_ "FlexKomSigStartPos" SG_ 947 VC_ASCM_WRN_CSO 7;
BA_ "FlexKomSID" SG_ 947 VC_ASCM_WRN_CSO 2006;
BA_ "GenSigTimeout_IC" SG_ 947 VC_ASCM_WRN_CSO 21000;
BA_ "FlexKomSigStartValue" SG_ 947 VC_ASCM_WRN_CSO "0300000000000000h";
BA_ "GenSigCycleTime" SG_ 947 VC_ASCM_WRN_CSO 2000;
BA_ "GenSigSendType" SG_ 947 VC_ASCM_WRN_CSO 5;
BA_ "GenSigSNA" SG_ 947 VC_ASCM_TJ_CSO "0h";
BA_ "FlexKomIsMotorola" SG_ 947 VC_ASCM_TJ_CSO 1;
BA_ "FlexKomComment" SG_ 947 VC_ASCM_TJ_CSO "Vehicle configuration - customer settings menu 1 P";
BA_ "FlexKomSigName" SG_ 947 VC_ASCM_TJ_CSO "VehCfgCSM1_Pkt";
BA_ "FlexKomSigLaenge" SG_ 947 VC_ASCM_TJ_CSO 64;
BA_ "FlexKomSigStartPos" SG_ 947 VC_ASCM_TJ_CSO 7;
BA_ "FlexKomSID" SG_ 947 VC_ASCM_TJ_CSO 2006;
BA_ "GenSigTimeout_IC" SG_ 947 VC_ASCM_TJ_CSO 21000;
BA_ "FlexKomSigStartValue" SG_ 947 VC_ASCM_TJ_CSO "0300000000000000h";
BA_ "GenSigCycleTime" SG_ 947 VC_ASCM_TJ_CSO 2000;
BA_ "GenSigSendType" SG_ 947 VC_ASCM_TJ_CSO 5;
BA_ "GenSigSNA" SG_ 947 VC_AMB_DMR_CSO "0h";
BA_ "FlexKomIsMotorola" SG_ 947 VC_AMB_DMR_CSO 1;
BA_ "FlexKomComment" SG_ 947 VC_AMB_DMR_CSO "Vehicle configuration - customer settings menu 1 P";
BA_ "FlexKomSigName" SG_ 947 VC_AMB_DMR_CSO "VehCfgCSM1_Pkt";
BA_ "FlexKomSigLaenge" SG_ 947 VC_AMB_DMR_CSO 64;
BA_ "FlexKomSigStartPos" SG_ 947 VC_AMB_DMR_CSO 7;
BA_ "FlexKomSID" SG_ 947 VC_AMB_DMR_CSO 2006;
BA_ "GenSigTimeout_IC" SG_ 947 VC_AMB_DMR_CSO 21000;
BA_ "FlexKomSigStartValue" SG_ 947 VC_AMB_DMR_CSO "0300000000000000h";
BA_ "GenSigCycleTime" SG_ 947 VC_AMB_DMR_CSO 2000;
BA_ "GenSigSendType" SG_ 947 VC_AMB_DMR_CSO 5;
BA_ "GenSigSNA" SG_ 947 VC_AFLS_CSO "0h";
BA_ "FlexKomIsMotorola" SG_ 947 VC_AFLS_CSO 1;
BA_ "FlexKomComment" SG_ 947 VC_AFLS_CSO "Vehicle configuration - customer settings menu 1 P";
BA_ "FlexKomSigName" SG_ 947 VC_AFLS_CSO "VehCfgCSM1_Pkt";
BA_ "FlexKomSigLaenge" SG_ 947 VC_AFLS_CSO 64;
BA_ "FlexKomSigStartPos" SG_ 947 VC_AFLS_CSO 7;
BA_ "FlexKomSID" SG_ 947 VC_AFLS_CSO 2006;
BA_ "GenSigTimeout_IC" SG_ 947 VC_AFLS_CSO 21000;
BA_ "FlexKomSigStartValue" SG_ 947 VC_AFLS_CSO "0300000000000000h";
BA_ "GenSigCycleTime" SG_ 947 VC_AFLS_CSO 2000;
BA_ "GenSigSendType" SG_ 947 VC_AFLS_CSO 5;
BA_ "GenSigSNA" SG_ 947 VC_ACC_DLY_CSO "0h";
BA_ "FlexKomIsMotorola" SG_ 947 VC_ACC_DLY_CSO 1;
BA_ "FlexKomComment" SG_ 947 VC_ACC_DLY_CSO "Vehicle configuration - customer settings menu 1 P";
BA_ "FlexKomSigName" SG_ 947 VC_ACC_DLY_CSO "VehCfgCSM1_Pkt";
BA_ "FlexKomSigLaenge" SG_ 947 VC_ACC_DLY_CSO 64;
BA_ "FlexKomSigStartPos" SG_ 947 VC_ACC_DLY_CSO 7;
BA_ "FlexKomSID" SG_ 947 VC_ACC_DLY_CSO 2006;
BA_ "GenSigTimeout_IC" SG_ 947 VC_ACC_DLY_CSO 21000;
BA_ "FlexKomSigStartValue" SG_ 947 VC_ACC_DLY_CSO "0300000000000000h";
BA_ "GenSigCycleTime" SG_ 947 VC_ACC_DLY_CSO 2000;
BA_ "GenSigSendType" SG_ 947 VC_ACC_DLY_CSO 5;
BA_ "GenMsgCycleTime" BO_ 943 1000;
BA_ "GenMsgDelayTime" BO_ 943 20;
BA_ "GenMsgNrOfRepetitions" BO_ 943 2;
BA_ "GenMsgStartValue" BO_ 943 "0000000000000000h";
BA_ "GenMsgStartDelayTime" BO_ 943 250;
BA_ "GenSigCycleTime" SG_ 943 B_Total_Dist_Miles 1000;
BA_ "FlexKomSigStartValue" SG_ 943 B_Total_Dist_Miles "0000000000000000h";
BA_ "GenSigTimeout_ETM" SG_ 943 B_Total_Dist_Miles 10500;
BA_ "FlexKomSID" SG_ 943 B_Total_Dist_Miles 2580;
BA_ "FlexKomSigStartPos" SG_ 943 B_Total_Dist_Miles 7;
BA_ "FlexKomSigLaenge" SG_ 943 B_Total_Dist_Miles 64;
BA_ "FlexKomSigName" SG_ 943 B_Total_Dist_Miles "IC_TripData_Pkt_6";
BA_ "FlexKomComment" SG_ 943 B_Total_Dist_Miles "IC Trip data packet 6";
BA_ "FlexKomIsMotorola" SG_ 943 B_Total_Dist_Miles 1;
BA_ "GenSigSNA" SG_ 943 B_Total_Dist_Miles "FFFFFFh";
BA_ "GenSigCycleTime" SG_ 943 B_Total_Dist_Kilometers 1000;
BA_ "FlexKomSigStartValue" SG_ 943 B_Total_Dist_Kilometers "0000000000000000h";
BA_ "GenSigTimeout_ETM" SG_ 943 B_Total_Dist_Kilometers 10500;
BA_ "FlexKomSID" SG_ 943 B_Total_Dist_Kilometers 2580;
BA_ "FlexKomSigStartPos" SG_ 943 B_Total_Dist_Kilometers 7;
BA_ "FlexKomSigLaenge" SG_ 943 B_Total_Dist_Kilometers 64;
BA_ "FlexKomSigName" SG_ 943 B_Total_Dist_Kilometers "IC_TripData_Pkt_6";
BA_ "FlexKomComment" SG_ 943 B_Total_Dist_Kilometers "IC Trip data packet 6";
BA_ "FlexKomIsMotorola" SG_ 943 B_Total_Dist_Kilometers 1;
BA_ "GenSigSNA" SG_ 943 B_Total_Dist_Kilometers "FFFFFFh";
BA_ "GenMsgCycleTime" BO_ 942 1000;
BA_ "GenMsgDelayTime" BO_ 942 20;
BA_ "GenMsgNrOfRepetitions" BO_ 942 2;
BA_ "GenMsgStartValue" BO_ 942 "0000000000000000h";
BA_ "GenMsgStartDelayTime" BO_ 942 200;
BA_ "GenSigCycleTime" SG_ 942 B_KMpL 1000;
BA_ "FlexKomSigStartValue" SG_ 942 B_KMpL "0000000000000000h";
BA_ "GenSigTimeout_ETM" SG_ 942 B_KMpL 10500;
BA_ "FlexKomSID" SG_ 942 B_KMpL 2581;
BA_ "FlexKomSigStartPos" SG_ 942 B_KMpL 7;
BA_ "FlexKomSigLaenge" SG_ 942 B_KMpL 64;
BA_ "FlexKomSigName" SG_ 942 B_KMpL "IC_TripData_Pkt_5";
BA_ "FlexKomComment" SG_ 942 B_KMpL "IC Trip data packet 5";
BA_ "FlexKomIsMotorola" SG_ 942 B_KMpL 1;
BA_ "GenSigSNA" SG_ 942 B_KMpL "3FFh";
BA_ "GenSigCycleTime" SG_ 942 B_Hybrid_Miles 1000;
BA_ "FlexKomSigStartValue" SG_ 942 B_Hybrid_Miles "0000000000000000h";
BA_ "GenSigTimeout_ETM" SG_ 942 B_Hybrid_Miles 10500;
BA_ "FlexKomSID" SG_ 942 B_Hybrid_Miles 2581;
BA_ "FlexKomSigStartPos" SG_ 942 B_Hybrid_Miles 7;
BA_ "FlexKomSigLaenge" SG_ 942 B_Hybrid_Miles 64;
BA_ "FlexKomSigName" SG_ 942 B_Hybrid_Miles "IC_TripData_Pkt_5";
BA_ "FlexKomComment" SG_ 942 B_Hybrid_Miles "IC Trip data packet 5";
BA_ "FlexKomIsMotorola" SG_ 942 B_Hybrid_Miles 1;
BA_ "GenSigSNA" SG_ 942 B_Hybrid_Miles "FFFFFFh";
BA_ "GenSigCycleTime" SG_ 942 B_Hybrid_Kilometers 1000;
BA_ "FlexKomSigStartValue" SG_ 942 B_Hybrid_Kilometers "0000000000000000h";
BA_ "GenSigTimeout_ETM" SG_ 942 B_Hybrid_Kilometers 10500;
BA_ "FlexKomSID" SG_ 942 B_Hybrid_Kilometers 2581;
BA_ "FlexKomSigStartPos" SG_ 942 B_Hybrid_Kilometers 7;
BA_ "FlexKomSigLaenge" SG_ 942 B_Hybrid_Kilometers 64;
BA_ "FlexKomSigName" SG_ 942 B_Hybrid_Kilometers "IC_TripData_Pkt_5";
BA_ "FlexKomComment" SG_ 942 B_Hybrid_Kilometers "IC Trip data packet 5";
BA_ "FlexKomIsMotorola" SG_ 942 B_Hybrid_Kilometers 1;
BA_ "GenSigSNA" SG_ 942 B_Hybrid_Kilometers "FFFFFFh";
BA_ "GenMsgCycleTime" BO_ 941 1000;
BA_ "GenMsgDelayTime" BO_ 941 20;
BA_ "GenMsgNrOfRepetitions" BO_ 941 2;
BA_ "GenMsgStartValue" BO_ 941 "0000000000000000h";
BA_ "GenMsgStartDelayTime" BO_ 941 150;
BA_ "GenSigCycleTime" SG_ 941 B_MPG 1000;
BA_ "FlexKomSigStartValue" SG_ 941 B_MPG "0000000000000000h";
BA_ "GenSigTimeout_ETM" SG_ 941 B_MPG 10500;
BA_ "FlexKomSID" SG_ 941 B_MPG 2582;
BA_ "FlexKomSigStartPos" SG_ 941 B_MPG 7;
BA_ "FlexKomSigLaenge" SG_ 941 B_MPG 64;
BA_ "FlexKomSigName" SG_ 941 B_MPG "IC_TripData_Pkt_4";
BA_ "FlexKomComment" SG_ 941 B_MPG "IC Trip data packet 4";
BA_ "FlexKomIsMotorola" SG_ 941 B_MPG 1;
BA_ "GenSigSNA" SG_ 941 B_MPG "3FFh";
BA_ "GenSigCycleTime" SG_ 941 B_EV_Miles 1000;
BA_ "FlexKomSigStartValue" SG_ 941 B_EV_Miles "0000000000000000h";
BA_ "GenSigTimeout_ETM" SG_ 941 B_EV_Miles 10500;
BA_ "FlexKomSID" SG_ 941 B_EV_Miles 2582;
BA_ "FlexKomSigStartPos" SG_ 941 B_EV_Miles 7;
BA_ "FlexKomSigLaenge" SG_ 941 B_EV_Miles 64;
BA_ "FlexKomSigName" SG_ 941 B_EV_Miles "IC_TripData_Pkt_4";
BA_ "FlexKomComment" SG_ 941 B_EV_Miles "IC Trip data packet 4";
BA_ "FlexKomIsMotorola" SG_ 941 B_EV_Miles 1;
BA_ "GenSigSNA" SG_ 941 B_EV_Miles "FFFFFFh";
BA_ "GenSigCycleTime" SG_ 941 B_EV_Kilometers 1000;
BA_ "FlexKomSigStartValue" SG_ 941 B_EV_Kilometers "0000000000000000h";
BA_ "GenSigTimeout_ETM" SG_ 941 B_EV_Kilometers 10500;
BA_ "FlexKomSID" SG_ 941 B_EV_Kilometers 2582;
BA_ "FlexKomSigStartPos" SG_ 941 B_EV_Kilometers 7;
BA_ "FlexKomSigLaenge" SG_ 941 B_EV_Kilometers 64;
BA_ "FlexKomSigName" SG_ 941 B_EV_Kilometers "IC_TripData_Pkt_4";
BA_ "FlexKomComment" SG_ 941 B_EV_Kilometers "IC Trip data packet 4";
BA_ "FlexKomIsMotorola" SG_ 941 B_EV_Kilometers 1;
BA_ "GenSigSNA" SG_ 941 B_EV_Kilometers "FFFFFFh";
BA_ "GenMsgCycleTime" BO_ 940 1000;
BA_ "GenMsgDelayTime" BO_ 940 20;
BA_ "GenMsgNrOfRepetitions" BO_ 940 2;
BA_ "GenMsgStartValue" BO_ 940 "0000000000000000h";
BA_ "GenMsgStartDelayTime" BO_ 940 100;
BA_ "GenSigCycleTime" SG_ 940 A_Total_Dist_Miles 1000;
BA_ "FlexKomSigStartValue" SG_ 940 A_Total_Dist_Miles "0000000000000000h";
BA_ "GenSigTimeout_ETM" SG_ 940 A_Total_Dist_Miles 10500;
BA_ "FlexKomSID" SG_ 940 A_Total_Dist_Miles 2583;
BA_ "FlexKomSigStartPos" SG_ 940 A_Total_Dist_Miles 7;
BA_ "FlexKomSigLaenge" SG_ 940 A_Total_Dist_Miles 64;
BA_ "FlexKomSigName" SG_ 940 A_Total_Dist_Miles "IC_TripData_Pkt_3";
BA_ "FlexKomComment" SG_ 940 A_Total_Dist_Miles "IC Trip data packet 3";
BA_ "FlexKomIsMotorola" SG_ 940 A_Total_Dist_Miles 1;
BA_ "GenSigSNA" SG_ 940 A_Total_Dist_Miles "FFFFFFh";
BA_ "GenSigCycleTime" SG_ 940 A_Total_Dist_Kilometers 1000;
BA_ "FlexKomSigStartValue" SG_ 940 A_Total_Dist_Kilometers "0000000000000000h";
BA_ "GenSigTimeout_ETM" SG_ 940 A_Total_Dist_Kilometers 10500;
BA_ "FlexKomSID" SG_ 940 A_Total_Dist_Kilometers 2583;
BA_ "FlexKomSigStartPos" SG_ 940 A_Total_Dist_Kilometers 7;
BA_ "FlexKomSigLaenge" SG_ 940 A_Total_Dist_Kilometers 64;
BA_ "FlexKomSigName" SG_ 940 A_Total_Dist_Kilometers "IC_TripData_Pkt_3";
BA_ "FlexKomComment" SG_ 940 A_Total_Dist_Kilometers "IC Trip data packet 3";
BA_ "FlexKomIsMotorola" SG_ 940 A_Total_Dist_Kilometers 1;
BA_ "GenSigSNA" SG_ 940 A_Total_Dist_Kilometers "FFFFFFh";
BA_ "GenMsgCycleTime" BO_ 939 1000;
BA_ "GenMsgDelayTime" BO_ 939 20;
BA_ "GenMsgNrOfRepetitions" BO_ 939 2;
BA_ "GenMsgStartValue" BO_ 939 "0000000000000000h";
BA_ "GenMsgStartDelayTime" BO_ 939 50;
BA_ "GenSigCycleTime" SG_ 939 A_KMpL 1000;
BA_ "FlexKomSigStartValue" SG_ 939 A_KMpL "0000000000000000h";
BA_ "GenSigTimeout_ETM" SG_ 939 A_KMpL 10500;
BA_ "FlexKomSID" SG_ 939 A_KMpL 2584;
BA_ "FlexKomSigStartPos" SG_ 939 A_KMpL 7;
BA_ "FlexKomSigLaenge" SG_ 939 A_KMpL 64;
BA_ "FlexKomSigName" SG_ 939 A_KMpL "IC_TripData_Pkt_2";
BA_ "FlexKomComment" SG_ 939 A_KMpL "IC Trip data packet 2";
BA_ "FlexKomIsMotorola" SG_ 939 A_KMpL 1;
BA_ "GenSigSNA" SG_ 939 A_KMpL "3FFh";
BA_ "GenSigCycleTime" SG_ 939 A_Hybrid_Miles 1000;
BA_ "FlexKomSigStartValue" SG_ 939 A_Hybrid_Miles "0000000000000000h";
BA_ "GenSigTimeout_ETM" SG_ 939 A_Hybrid_Miles 10500;
BA_ "FlexKomSID" SG_ 939 A_Hybrid_Miles 2584;
BA_ "FlexKomSigStartPos" SG_ 939 A_Hybrid_Miles 7;
BA_ "FlexKomSigLaenge" SG_ 939 A_Hybrid_Miles 64;
BA_ "FlexKomSigName" SG_ 939 A_Hybrid_Miles "IC_TripData_Pkt_2";
BA_ "FlexKomComment" SG_ 939 A_Hybrid_Miles "IC Trip data packet 2";
BA_ "FlexKomIsMotorola" SG_ 939 A_Hybrid_Miles 1;
BA_ "GenSigSNA" SG_ 939 A_Hybrid_Miles "FFFFFFh";
BA_ "GenSigCycleTime" SG_ 939 A_Hybrid_Kilometers 1000;
BA_ "FlexKomSigStartValue" SG_ 939 A_Hybrid_Kilometers "0000000000000000h";
BA_ "GenSigTimeout_ETM" SG_ 939 A_Hybrid_Kilometers 10500;
BA_ "FlexKomSID" SG_ 939 A_Hybrid_Kilometers 2584;
BA_ "FlexKomSigStartPos" SG_ 939 A_Hybrid_Kilometers 7;
BA_ "FlexKomSigLaenge" SG_ 939 A_Hybrid_Kilometers 64;
BA_ "FlexKomSigName" SG_ 939 A_Hybrid_Kilometers "IC_TripData_Pkt_2";
BA_ "FlexKomComment" SG_ 939 A_Hybrid_Kilometers "IC Trip data packet 2";
BA_ "FlexKomIsMotorola" SG_ 939 A_Hybrid_Kilometers 1;
BA_ "GenSigSNA" SG_ 939 A_Hybrid_Kilometers "FFFFFFh";
BA_ "GenMsgCycleTime" BO_ 938 1000;
BA_ "GenMsgDelayTime" BO_ 938 20;
BA_ "GenMsgNrOfRepetitions" BO_ 938 2;
BA_ "GenMsgStartValue" BO_ 938 "0000000000000000h";
BA_ "GenSigCycleTime" SG_ 938 A_MPG 1000;
BA_ "FlexKomSigStartValue" SG_ 938 A_MPG "0000000000000000h";
BA_ "GenSigTimeout_ETM" SG_ 938 A_MPG 10500;
BA_ "FlexKomSID" SG_ 938 A_MPG 2585;
BA_ "FlexKomSigStartPos" SG_ 938 A_MPG 7;
BA_ "FlexKomSigLaenge" SG_ 938 A_MPG 64;
BA_ "FlexKomSigName" SG_ 938 A_MPG "IC_TripData_Pkt_1";
BA_ "FlexKomComment" SG_ 938 A_MPG "IC Trip data packet 1";
BA_ "FlexKomIsMotorola" SG_ 938 A_MPG 1;
BA_ "GenSigSNA" SG_ 938 A_MPG "3FFh";
BA_ "GenSigCycleTime" SG_ 938 A_EV_Miles 1000;
BA_ "FlexKomSigStartValue" SG_ 938 A_EV_Miles "0000000000000000h";
BA_ "GenSigTimeout_ETM" SG_ 938 A_EV_Miles 10500;
BA_ "FlexKomSID" SG_ 938 A_EV_Miles 2585;
BA_ "FlexKomSigStartPos" SG_ 938 A_EV_Miles 7;
BA_ "FlexKomSigLaenge" SG_ 938 A_EV_Miles 64;
BA_ "FlexKomSigName" SG_ 938 A_EV_Miles "IC_TripData_Pkt_1";
BA_ "FlexKomComment" SG_ 938 A_EV_Miles "IC Trip data packet 1";
BA_ "FlexKomIsMotorola" SG_ 938 A_EV_Miles 1;
BA_ "GenSigSNA" SG_ 938 A_EV_Miles "FFFFFFh";
BA_ "GenSigCycleTime" SG_ 938 A_EV_Kilometers 1000;
BA_ "FlexKomSigStartValue" SG_ 938 A_EV_Kilometers "0000000000000000h";
BA_ "GenSigTimeout_ETM" SG_ 938 A_EV_Kilometers 10500;
BA_ "FlexKomSID" SG_ 938 A_EV_Kilometers 2585;
BA_ "FlexKomSigStartPos" SG_ 938 A_EV_Kilometers 7;
BA_ "FlexKomSigLaenge" SG_ 938 A_EV_Kilometers 64;
BA_ "FlexKomSigName" SG_ 938 A_EV_Kilometers "IC_TripData_Pkt_1";
BA_ "FlexKomComment" SG_ 938 A_EV_Kilometers "IC Trip data packet 1";
BA_ "FlexKomIsMotorola" SG_ 938 A_EV_Kilometers 1;
BA_ "GenSigSNA" SG_ 938 A_EV_Kilometers "FFFFFFh";
BA_ "GenMsgStartDelayTime" BO_ 937 10;
BA_ "GenMsgStartValue" BO_ 937 "00FFFFFFFF00C003h";
BA_ "GenMsgNrOfRepetitions" BO_ 937 2;
BA_ "GenMsgDelayTime" BO_ 937 20;
BA_ "GenMsgCycleTime" BO_ 937 1000;
BA_ "GenMsgSendType" BO_ 937 5;
BA_ "GenSigSNA" SG_ 937 SOUND_RS "0h";
BA_ "FlexKomIsMotorola" SG_ 937 SOUND_RS 1;
BA_ "FlexKomComment" SG_ 937 SOUND_RS "Sound horn on Remote Start ; no = [0], yes = [1]";
BA_ "FlexKomSigName" SG_ 937 SOUND_RS "SOUND_RS";
BA_ "FlexKomSigLaenge" SG_ 937 SOUND_RS 1;
BA_ "FlexKomSigStartPos" SG_ 937 SOUND_RS 52;
BA_ "FlexKomSID" SG_ 937 SOUND_RS 966;
BA_ "GenSigTimeout_IC" SG_ 937 SOUND_RS 10500;
BA_ "FlexKomSigStartValue" SG_ 937 SOUND_RS "00h";
BA_ "GenSigCycleTime" SG_ 937 SOUND_RS 1000;
BA_ "GenSigSendType" SG_ 937 SOUND_RS 5;
BA_ "GenSigSNA" SG_ 937 SOUND_LK_1ST_2ND "3h";
BA_ "FlexKomIsMotorola" SG_ 937 SOUND_LK_1ST_2ND 1;
BA_ "FlexKomComment" SG_ 937 SOUND_LK_1ST_2ND "Sound horn on lock status";
BA_ "FlexKomSigName" SG_ 937 SOUND_LK_1ST_2ND "SOUND_LK_1ST_2ND";
BA_ "FlexKomSigLaenge" SG_ 937 SOUND_LK_1ST_2ND 2;
BA_ "FlexKomSigStartPos" SG_ 937 SOUND_LK_1ST_2ND 57;
BA_ "FlexKomSID" SG_ 937 SOUND_LK_1ST_2ND 1956;
BA_ "GenSigTimeout_IC" SG_ 937 SOUND_LK_1ST_2ND 10500;
BA_ "GenSigStartValue" SG_ 937 SOUND_LK_1ST_2ND 3;
BA_ "FlexKomSigStartValue" SG_ 937 SOUND_LK_1ST_2ND "03h";
BA_ "GenSigCycleTime" SG_ 937 SOUND_LK_1ST_2ND 1000;
BA_ "GenSigSendType" SG_ 937 SOUND_LK_1ST_2ND 5;
BA_ "GenSigSNA" SG_ 937 SOUND_LK "0h";
BA_ "FlexKomIsMotorola" SG_ 937 SOUND_LK 1;
BA_ "FlexKomComment" SG_ 937 SOUND_LK "Configuration status CBC";
BA_ "FlexKomSigName" SG_ 937 SOUND_LK "CBC_CFG_STAT";
BA_ "FlexKomSigLaenge" SG_ 937 SOUND_LK 48;
BA_ "FlexKomSigStartPos" SG_ 937 SOUND_LK 7;
BA_ "FlexKomSID" SG_ 937 SOUND_LK 843;
BA_ "GenSigTimeout_IC" SG_ 937 SOUND_LK 10500;
BA_ "FlexKomSigStartValue" SG_ 937 SOUND_LK "00FFFFFFFF00h";
BA_ "GenSigCycleTime" SG_ 937 SOUND_LK 1000;
BA_ "GenSigSendType" SG_ 937 SOUND_LK 5;
BA_ "GenSigSNA" SG_ 937 ILL_APRCH_TIME "FFh";
BA_ "FlexKomIsMotorola" SG_ 937 ILL_APRCH_TIME 1;
BA_ "FlexKomComment" SG_ 937 ILL_APRCH_TIME "Configuration status CBC";
BA_ "FlexKomSigName" SG_ 937 ILL_APRCH_TIME "CBC_CFG_STAT";
BA_ "FlexKomSigLaenge" SG_ 937 ILL_APRCH_TIME 48;
BA_ "FlexKomSigStartPos" SG_ 937 ILL_APRCH_TIME 7;
BA_ "FlexKomSID" SG_ 937 ILL_APRCH_TIME 843;
BA_ "GenSigTimeout_IC" SG_ 937 ILL_APRCH_TIME 10500;
BA_ "GenSigStartValue" SG_ 937 ILL_APRCH_TIME 255;
BA_ "FlexKomSigStartValue" SG_ 937 ILL_APRCH_TIME "00FFFFFFFF00h";
BA_ "GenSigCycleTime" SG_ 937 ILL_APRCH_TIME 1000;
BA_ "GenSigSendType" SG_ 937 ILL_APRCH_TIME 5;
BA_ "GenSigSNA" SG_ 937 HL_WPR "0h";
BA_ "FlexKomIsMotorola" SG_ 937 HL_WPR 1;
BA_ "FlexKomComment" SG_ 937 HL_WPR "Configuration status CBC";
BA_ "FlexKomSigName" SG_ 937 HL_WPR "CBC_CFG_STAT";
BA_ "FlexKomSigLaenge" SG_ 937 HL_WPR 48;
BA_ "FlexKomSigStartPos" SG_ 937 HL_WPR 7;
BA_ "FlexKomSID" SG_ 937 HL_WPR 843;
BA_ "GenSigTimeout_IC" SG_ 937 HL_WPR 10500;
BA_ "FlexKomSigStartValue" SG_ 937 HL_WPR "00FFFFFFFF00h";
BA_ "GenSigCycleTime" SG_ 937 HL_WPR 1000;
BA_ "GenSigSendType" SG_ 937 HL_WPR 5;
BA_ "GenSigSNA" SG_ 937 HL_DLY_TIME "FFh";
BA_ "FlexKomIsMotorola" SG_ 937 HL_DLY_TIME 1;
BA_ "FlexKomComment" SG_ 937 HL_DLY_TIME "Configuration status CBC";
BA_ "FlexKomSigName" SG_ 937 HL_DLY_TIME "CBC_CFG_STAT";
BA_ "FlexKomSigLaenge" SG_ 937 HL_DLY_TIME 48;
BA_ "FlexKomSigStartPos" SG_ 937 HL_DLY_TIME 7;
BA_ "FlexKomSID" SG_ 937 HL_DLY_TIME 843;
BA_ "GenSigTimeout_IC" SG_ 937 HL_DLY_TIME 10500;
BA_ "GenSigStartValue" SG_ 937 HL_DLY_TIME 255;
BA_ "FlexKomSigStartValue" SG_ 937 HL_DLY_TIME "00FFFFFFFF00h";
BA_ "GenSigCycleTime" SG_ 937 HL_DLY_TIME 1000;
BA_ "GenSigSendType" SG_ 937 HL_DLY_TIME 5;
BA_ "GenSigSNA" SG_ 937 FLASH_LK "0h";
BA_ "FlexKomIsMotorola" SG_ 937 FLASH_LK 1;
BA_ "FlexKomComment" SG_ 937 FLASH_LK "Configuration status CBC";
BA_ "FlexKomSigName" SG_ 937 FLASH_LK "CBC_CFG_STAT";
BA_ "FlexKomSigLaenge" SG_ 937 FLASH_LK 48;
BA_ "FlexKomSigStartPos" SG_ 937 FLASH_LK 7;
BA_ "FlexKomSID" SG_ 937 FLASH_LK 843;
BA_ "GenSigTimeout_IC" SG_ 937 FLASH_LK 10500;
BA_ "FlexKomSigStartValue" SG_ 937 FLASH_LK "00FFFFFFFF00h";
BA_ "GenSigCycleTime" SG_ 937 FLASH_LK 1000;
BA_ "GenSigSendType" SG_ 937 FLASH_LK 5;
BA_ "GenSigSNA" SG_ 937 DRL_ON "0h";
BA_ "FlexKomIsMotorola" SG_ 937 DRL_ON 1;
BA_ "FlexKomComment" SG_ 937 DRL_ON "Configuration status CBC";
BA_ "FlexKomSigName" SG_ 937 DRL_ON "CBC_CFG_STAT";
BA_ "FlexKomSigLaenge" SG_ 937 DRL_ON 48;
BA_ "FlexKomSigStartPos" SG_ 937 DRL_ON 7;
BA_ "FlexKomSID" SG_ 937 DRL_ON 843;
BA_ "GenSigTimeout_IC" SG_ 937 DRL_ON 10500;
BA_ "FlexKomSigStartValue" SG_ 937 DRL_ON "00FFFFFFFF00h";
BA_ "GenSigCycleTime" SG_ 937 DRL_ON 1000;
BA_ "GenSigSendType" SG_ 937 DRL_ON 5;
BA_ "GenSigSNA" SG_ 937 CFG_AUTO_WPR "0h";
BA_ "FlexKomIsMotorola" SG_ 937 CFG_AUTO_WPR 1;
BA_ "FlexKomComment" SG_ 937 CFG_AUTO_WPR "Configuration status CBC";
BA_ "FlexKomSigName" SG_ 937 CFG_AUTO_WPR "CBC_CFG_STAT";
BA_ "FlexKomSigLaenge" SG_ 937 CFG_AUTO_WPR 48;
BA_ "FlexKomSigStartPos" SG_ 937 CFG_AUTO_WPR 7;
BA_ "FlexKomSID" SG_ 937 CFG_AUTO_WPR 843;
BA_ "GenSigTimeout_IC" SG_ 937 CFG_AUTO_WPR 10500;
BA_ "FlexKomSigStartValue" SG_ 937 CFG_AUTO_WPR "00FFFFFFFF00h";
BA_ "GenSigCycleTime" SG_ 937 CFG_AUTO_WPR 1000;
BA_ "GenSigSendType" SG_ 937 CFG_AUTO_WPR 5;
BA_ "GenMsgStartValue" BO_ 924 "000000h";
BA_ "GenMsgNrOfRepetitions" BO_ 924 2;
BA_ "GenMsgDelayTime" BO_ 924 20;
BA_ "GenMsgCycleTime" BO_ 924 1000;
BA_ "GenMsgSendType" BO_ 924 5;
BA_ "GenSigSNA" SG_ 924 MsgServPEKG "3h";
BA_ "FlexKomIsMotorola" SG_ 924 MsgServPEKG 1;
BA_ "FlexKomComment" SG_ 924 MsgServPEKG "RF message packet";
BA_ "FlexKomSigName" SG_ 924 MsgServPEKG "RFMsgPkt";
BA_ "FlexKomSigLaenge" SG_ 924 MsgServPEKG 24;
BA_ "FlexKomSigStartPos" SG_ 924 MsgServPEKG 7;
BA_ "FlexKomSID" SG_ 924 MsgServPEKG 1038;
BA_ "GenSigTimeout_IC" SG_ 924 MsgServPEKG 10500;
BA_ "FlexKomSigStartValue" SG_ 924 MsgServPEKG "000000h";
BA_ "GenSigCycleTime" SG_ 924 MsgServPEKG 1000;
BA_ "GenSigSendType" SG_ 924 MsgServPEKG 5;
BA_ "GenSigSNA" SG_ 924 MsgNotInPark "3h";
BA_ "FlexKomIsMotorola" SG_ 924 MsgNotInPark 1;
BA_ "FlexKomComment" SG_ 924 MsgNotInPark "RF message packet";
BA_ "FlexKomSigName" SG_ 924 MsgNotInPark "RFMsgPkt";
BA_ "FlexKomSigLaenge" SG_ 924 MsgNotInPark 24;
BA_ "FlexKomSigStartPos" SG_ 924 MsgNotInPark 7;
BA_ "FlexKomSID" SG_ 924 MsgNotInPark 1038;
BA_ "GenSigTimeout_IC" SG_ 924 MsgNotInPark 10500;
BA_ "FlexKomSigStartValue" SG_ 924 MsgNotInPark "000000h";
BA_ "GenSigCycleTime" SG_ 924 MsgNotInPark 1000;
BA_ "GenSigSendType" SG_ 924 MsgNotInPark 5;
BA_ "GenSigSendType" SG_ 924 MsgKG2 5;
BA_ "GenSigCycleTime" SG_ 924 MsgKG2 1000;
BA_ "FlexKomSigStartValue" SG_ 924 MsgKG2 "000000h";
BA_ "GenSigTimeout_IC" SG_ 924 MsgKG2 10500;
BA_ "FlexKomSID" SG_ 924 MsgKG2 1038;
BA_ "FlexKomSigStartPos" SG_ 924 MsgKG2 7;
BA_ "FlexKomSigLaenge" SG_ 924 MsgKG2 24;
BA_ "FlexKomSigName" SG_ 924 MsgKG2 "RFMsgPkt";
BA_ "FlexKomComment" SG_ 924 MsgKG2 "RF message packet";
BA_ "FlexKomIsMotorola" SG_ 924 MsgKG2 1;
BA_ "GenSigSNA" SG_ 924 MsgKG2 "3h";
BA_ "GenSigSNA" SG_ 924 MsgKG1 "3h";
BA_ "FlexKomIsMotorola" SG_ 924 MsgKG1 1;
BA_ "FlexKomComment" SG_ 924 MsgKG1 "RF message packet";
BA_ "FlexKomSigName" SG_ 924 MsgKG1 "RFMsgPkt";
BA_ "FlexKomSigLaenge" SG_ 924 MsgKG1 24;
BA_ "FlexKomSigStartPos" SG_ 924 MsgKG1 7;
BA_ "FlexKomSID" SG_ 924 MsgKG1 1038;
BA_ "GenSigTimeout_IC" SG_ 924 MsgKG1 10500;
BA_ "FlexKomSigStartValue" SG_ 924 MsgKG1 "000000h";
BA_ "GenSigCycleTime" SG_ 924 MsgKG1 1000;
BA_ "GenSigSendType" SG_ 924 MsgKG1 5;
BA_ "GenSigSNA" SG_ 924 MsgFobNotFnd "3h";
BA_ "FlexKomIsMotorola" SG_ 924 MsgFobNotFnd 1;
BA_ "FlexKomComment" SG_ 924 MsgFobNotFnd "RF message packet";
BA_ "FlexKomSigName" SG_ 924 MsgFobNotFnd "RFMsgPkt";
BA_ "FlexKomSigLaenge" SG_ 924 MsgFobNotFnd 24;
BA_ "FlexKomSigStartPos" SG_ 924 MsgFobNotFnd 7;
BA_ "FlexKomSID" SG_ 924 MsgFobNotFnd 1038;
BA_ "GenSigTimeout_IC" SG_ 924 MsgFobNotFnd 10500;
BA_ "FlexKomSigStartValue" SG_ 924 MsgFobNotFnd "000000h";
BA_ "GenSigCycleTime" SG_ 924 MsgFobNotFnd 1000;
BA_ "GenSigSendType" SG_ 924 MsgFobNotFnd 5;
BA_ "GenSigSNA" SG_ 924 MsgFobBattLow "3h";
BA_ "FlexKomIsMotorola" SG_ 924 MsgFobBattLow 1;
BA_ "FlexKomComment" SG_ 924 MsgFobBattLow "RF message packet";
BA_ "FlexKomSigName" SG_ 924 MsgFobBattLow "RFMsgPkt";
BA_ "FlexKomSigLaenge" SG_ 924 MsgFobBattLow 24;
BA_ "FlexKomSigStartPos" SG_ 924 MsgFobBattLow 7;
BA_ "FlexKomSID" SG_ 924 MsgFobBattLow 1038;
BA_ "GenSigTimeout_IC" SG_ 924 MsgFobBattLow 10500;
BA_ "FlexKomSigStartValue" SG_ 924 MsgFobBattLow "000000h";
BA_ "GenSigCycleTime" SG_ 924 MsgFobBattLow 1000;
BA_ "GenSigSendType" SG_ 924 MsgFobBattLow 5;
BA_ "GenSigSNA" SG_ 924 FOBinTRUNK "0h";
BA_ "FlexKomIsMotorola" SG_ 924 FOBinTRUNK 1;
BA_ "FlexKomComment" SG_ 924 FOBinTRUNK "RF message packet";
BA_ "FlexKomSigName" SG_ 924 FOBinTRUNK "RFMsgPkt";
BA_ "FlexKomSigLaenge" SG_ 924 FOBinTRUNK 24;
BA_ "FlexKomSigStartPos" SG_ 924 FOBinTRUNK 7;
BA_ "FlexKomSID" SG_ 924 FOBinTRUNK 1038;
BA_ "FlexKomSigStartValue" SG_ 924 FOBinTRUNK "000000h";
BA_ "GenSigCycleTime" SG_ 924 FOBinTRUNK 1000;
BA_ "GenSigSendType" SG_ 924 FOBinTRUNK 5;
BA_ "GenSigSNA" SG_ 924 FOBinINT "0h";
BA_ "FlexKomIsMotorola" SG_ 924 FOBinINT 1;
BA_ "FlexKomComment" SG_ 924 FOBinINT "RF message packet";
BA_ "FlexKomSigName" SG_ 924 FOBinINT "RFMsgPkt";
BA_ "FlexKomSigLaenge" SG_ 924 FOBinINT 24;
BA_ "FlexKomSigStartPos" SG_ 924 FOBinINT 7;
BA_ "FlexKomSID" SG_ 924 FOBinINT 1038;
BA_ "FlexKomSigStartValue" SG_ 924 FOBinINT "000000h";
BA_ "GenSigCycleTime" SG_ 924 FOBinINT 1000;
BA_ "GenSigSendType" SG_ 924 FOBinINT 5;
BA_ "GenSigSNA" SG_ 924 FOB_SrchRslt "0h";
BA_ "FlexKomIsMotorola" SG_ 924 FOB_SrchRslt 1;
BA_ "FlexKomComment" SG_ 924 FOB_SrchRslt "RF message packet";
BA_ "FlexKomSigName" SG_ 924 FOB_SrchRslt "RFMsgPkt";
BA_ "FlexKomSigLaenge" SG_ 924 FOB_SrchRslt 24;
BA_ "FlexKomSigStartPos" SG_ 924 FOB_SrchRslt 7;
BA_ "FlexKomSID" SG_ 924 FOB_SrchRslt 1038;
BA_ "GenSigTimeout_CBC" SG_ 924 FOB_SrchRslt 10500;
BA_ "FlexKomSigStartValue" SG_ 924 FOB_SrchRslt "000000h";
BA_ "GenSigCycleTime" SG_ 924 FOB_SrchRslt 1000;
BA_ "GenSigSendType" SG_ 924 FOB_SrchRslt 5;
BA_ "GenSigSNA" SG_ 924 FOB_SrchFLT "0h";
BA_ "FlexKomIsMotorola" SG_ 924 FOB_SrchFLT 1;
BA_ "FlexKomComment" SG_ 924 FOB_SrchFLT "RF message packet";
BA_ "FlexKomSigName" SG_ 924 FOB_SrchFLT "RFMsgPkt";
BA_ "FlexKomSigLaenge" SG_ 924 FOB_SrchFLT 24;
BA_ "FlexKomSigStartPos" SG_ 924 FOB_SrchFLT 7;
BA_ "FlexKomSID" SG_ 924 FOB_SrchFLT 1038;
BA_ "FlexKomSigStartValue" SG_ 924 FOB_SrchFLT "000000h";
BA_ "GenSigCycleTime" SG_ 924 FOB_SrchFLT 1000;
BA_ "GenSigSendType" SG_ 924 FOB_SrchFLT 5;
BA_ "GenSigSNA" SG_ 924 FOB_ExtRT "0h";
BA_ "FlexKomIsMotorola" SG_ 924 FOB_ExtRT 1;
BA_ "FlexKomComment" SG_ 924 FOB_ExtRT "RF message packet";
BA_ "FlexKomSigName" SG_ 924 FOB_ExtRT "RFMsgPkt";
BA_ "FlexKomSigLaenge" SG_ 924 FOB_ExtRT 24;
BA_ "FlexKomSigStartPos" SG_ 924 FOB_ExtRT 7;
BA_ "FlexKomSID" SG_ 924 FOB_ExtRT 1038;
BA_ "FlexKomSigStartValue" SG_ 924 FOB_ExtRT "000000h";
BA_ "GenSigCycleTime" SG_ 924 FOB_ExtRT 1000;
BA_ "GenSigSendType" SG_ 924 FOB_ExtRT 5;
BA_ "GenSigSNA" SG_ 924 FOB_ExtRR "0h";
BA_ "FlexKomIsMotorola" SG_ 924 FOB_ExtRR 1;
BA_ "FlexKomComment" SG_ 924 FOB_ExtRR "RF message packet";
BA_ "FlexKomSigName" SG_ 924 FOB_ExtRR "RFMsgPkt";
BA_ "FlexKomSigLaenge" SG_ 924 FOB_ExtRR 24;
BA_ "FlexKomSigStartPos" SG_ 924 FOB_ExtRR 7;
BA_ "FlexKomSID" SG_ 924 FOB_ExtRR 1038;
BA_ "FlexKomSigStartValue" SG_ 924 FOB_ExtRR "000000h";
BA_ "GenSigCycleTime" SG_ 924 FOB_ExtRR 1000;
BA_ "GenSigSendType" SG_ 924 FOB_ExtRR 5;
BA_ "GenSigSNA" SG_ 924 FOB_ExtLT "0h";
BA_ "FlexKomIsMotorola" SG_ 924 FOB_ExtLT 1;
BA_ "FlexKomComment" SG_ 924 FOB_ExtLT "RF message packet";
BA_ "FlexKomSigName" SG_ 924 FOB_ExtLT "RFMsgPkt";
BA_ "FlexKomSigLaenge" SG_ 924 FOB_ExtLT 24;
BA_ "FlexKomSigStartPos" SG_ 924 FOB_ExtLT 7;
BA_ "FlexKomSID" SG_ 924 FOB_ExtLT 1038;
BA_ "FlexKomSigStartValue" SG_ 924 FOB_ExtLT "000000h";
BA_ "GenSigCycleTime" SG_ 924 FOB_ExtLT 1000;
BA_ "GenSigSendType" SG_ 924 FOB_ExtLT 5;
BA_ "GenMsgStartValue" BO_ 897 "033F000000000000h";
BA_ "GenMsgNrOfRepetitions" BO_ 897 2;
BA_ "GenMsgDelayTime" BO_ 897 20;
BA_ "GenMsgCycleTime" BO_ 897 2000;
BA_ "GenMsgSendType" BO_ 897 5;
BA_ "GenSigSNA" SG_ 897 VC_VehCfg7_Stat "3h";
BA_ "FlexKomIsMotorola" SG_ 897 VC_VehCfg7_Stat 1;
BA_ "FlexKomComment" SG_ 897 VC_VehCfg7_Stat "Vehicle Configuration 7 Packet";
BA_ "FlexKomSigName" SG_ 897 VC_VehCfg7_Stat "VehCfg7_Pkt";
BA_ "FlexKomSigLaenge" SG_ 897 VC_VehCfg7_Stat 64;
BA_ "FlexKomSigStartPos" SG_ 897 VC_VehCfg7_Stat 7;
BA_ "FlexKomSID" SG_ 897 VC_VehCfg7_Stat 2026;
BA_ "GenSigTimeout_ORC" SG_ 897 VC_VehCfg7_Stat 7000;
BA_ "GenSigTimeout_IC" SG_ 897 VC_VehCfg7_Stat 21000;
BA_ "GenSigStartValue" SG_ 897 VC_VehCfg7_Stat 3;
BA_ "FlexKomSigStartValue" SG_ 897 VC_VehCfg7_Stat "033F000000000000h";
BA_ "GenSigCycleTime" SG_ 897 VC_VehCfg7_Stat 2000;
BA_ "GenSigSendType" SG_ 897 VC_VehCfg7_Stat 5;
BA_ "GenSigSNA" SG_ 897 VC_TSBM_Prsnt "0h";
BA_ "FlexKomIsMotorola" SG_ 897 VC_TSBM_Prsnt 1;
BA_ "FlexKomComment" SG_ 897 VC_TSBM_Prsnt "Vehicle Configuration 7 Packet";
BA_ "FlexKomSigName" SG_ 897 VC_TSBM_Prsnt "VehCfg7_Pkt";
BA_ "FlexKomSigLaenge" SG_ 897 VC_TSBM_Prsnt 64;
BA_ "FlexKomSigStartPos" SG_ 897 VC_TSBM_Prsnt 7;
BA_ "FlexKomSID" SG_ 897 VC_TSBM_Prsnt 2026;
BA_ "FlexKomSigStartValue" SG_ 897 VC_TSBM_Prsnt "033F000000000000h";
BA_ "GenSigCycleTime" SG_ 897 VC_TSBM_Prsnt 2000;
BA_ "GenSigSendType" SG_ 897 VC_TSBM_Prsnt 5;
BA_ "GenSigSNA" SG_ 897 VC_TrnsDrvMdPrsnt "0h";
BA_ "FlexKomIsMotorola" SG_ 897 VC_TrnsDrvMdPrsnt 1;
BA_ "FlexKomComment" SG_ 897 VC_TrnsDrvMdPrsnt "Vehicle Configuration 7 Packet";
BA_ "FlexKomSigName" SG_ 897 VC_TrnsDrvMdPrsnt "VehCfg7_Pkt";
BA_ "FlexKomSigLaenge" SG_ 897 VC_TrnsDrvMdPrsnt 64;
BA_ "FlexKomSigStartPos" SG_ 897 VC_TrnsDrvMdPrsnt 7;
BA_ "FlexKomSID" SG_ 897 VC_TrnsDrvMdPrsnt 2026;
BA_ "GenSigTimeout_IC" SG_ 897 VC_TrnsDrvMdPrsnt 21000;
BA_ "FlexKomSigStartValue" SG_ 897 VC_TrnsDrvMdPrsnt "033F000000000000h";
BA_ "GenSigCycleTime" SG_ 897 VC_TrnsDrvMdPrsnt 2000;
BA_ "GenSigSendType" SG_ 897 VC_TrnsDrvMdPrsnt 5;
BA_ "GenSigSNA" SG_ 897 VC_TransType "3Fh";
BA_ "FlexKomIsMotorola" SG_ 897 VC_TransType 1;
BA_ "FlexKomComment" SG_ 897 VC_TransType "Vehicle Configuration 7 Packet";
BA_ "FlexKomSigName" SG_ 897 VC_TransType "VehCfg7_Pkt";
BA_ "FlexKomSigLaenge" SG_ 897 VC_TransType 64;
BA_ "FlexKomSigStartPos" SG_ 897 VC_TransType 7;
BA_ "FlexKomSID" SG_ 897 VC_TransType 2026;
BA_ "GenSigTimeout_IC" SG_ 897 VC_TransType 21000;
BA_ "GenSigStartValue" SG_ 897 VC_TransType 63;
BA_ "FlexKomSigStartValue" SG_ 897 VC_TransType "033F000000000000h";
BA_ "GenSigCycleTime" SG_ 897 VC_TransType 2000;
BA_ "GenSigSendType" SG_ 897 VC_TransType 5;
BA_ "GenSigSNA" SG_ 897 VC_Trans_N_Hold_Prsnt "0h";
BA_ "FlexKomIsMotorola" SG_ 897 VC_Trans_N_Hold_Prsnt 1;
BA_ "FlexKomComment" SG_ 897 VC_Trans_N_Hold_Prsnt "Vehicle Configuration 7 Packet";
BA_ "FlexKomSigName" SG_ 897 VC_Trans_N_Hold_Prsnt "VehCfg7_Pkt";
BA_ "FlexKomSigLaenge" SG_ 897 VC_Trans_N_Hold_Prsnt 64;
BA_ "FlexKomSigStartPos" SG_ 897 VC_Trans_N_Hold_Prsnt 7;
BA_ "FlexKomSID" SG_ 897 VC_Trans_N_Hold_Prsnt 2026;
BA_ "FlexKomSigStartValue" SG_ 897 VC_Trans_N_Hold_Prsnt "033F000000000000h";
BA_ "GenSigCycleTime" SG_ 897 VC_Trans_N_Hold_Prsnt 2000;
BA_ "GenSigSendType" SG_ 897 VC_Trans_N_Hold_Prsnt 5;
BA_ "GenSigSNA" SG_ 897 VC_Trans_Equipped "0h";
BA_ "FlexKomIsMotorola" SG_ 897 VC_Trans_Equipped 1;
BA_ "FlexKomComment" SG_ 897 VC_Trans_Equipped "Vehicle Configuration 7 Packet";
BA_ "FlexKomSigName" SG_ 897 VC_Trans_Equipped "VehCfg7_Pkt";
BA_ "FlexKomSigLaenge" SG_ 897 VC_Trans_Equipped 64;
BA_ "FlexKomSigStartPos" SG_ 897 VC_Trans_Equipped 7;
BA_ "FlexKomSID" SG_ 897 VC_Trans_Equipped 2026;
BA_ "GenSigTimeout_ORC" SG_ 897 VC_Trans_Equipped 7000;
BA_ "FlexKomSigStartValue" SG_ 897 VC_Trans_Equipped "033F000000000000h";
BA_ "GenSigCycleTime" SG_ 897 VC_Trans_Equipped 2000;
BA_ "GenSigSendType" SG_ 897 VC_Trans_Equipped 5;
BA_ "GenSigSendType" SG_ 897 VC_TPMS_Configuration 5;
BA_ "GenSigCycleTime" SG_ 897 VC_TPMS_Configuration 2000;
BA_ "FlexKomSigStartValue" SG_ 897 VC_TPMS_Configuration "033F000000000000h";
BA_ "GenSigTimeout_IC" SG_ 897 VC_TPMS_Configuration 21000;
BA_ "FlexKomSID" SG_ 897 VC_TPMS_Configuration 2026;
BA_ "FlexKomSigStartPos" SG_ 897 VC_TPMS_Configuration 7;
BA_ "FlexKomSigLaenge" SG_ 897 VC_TPMS_Configuration 64;
BA_ "FlexKomSigName" SG_ 897 VC_TPMS_Configuration "VehCfg7_Pkt";
BA_ "FlexKomComment" SG_ 897 VC_TPMS_Configuration "Vehicle Configuration 7 Packet";
BA_ "FlexKomIsMotorola" SG_ 897 VC_TPMS_Configuration 1;
BA_ "GenSigSNA" SG_ 897 VC_TPMS_Configuration "7h";
BA_ "GenSigSNA" SG_ 897 VC_TeenKey "0h";
BA_ "FlexKomIsMotorola" SG_ 897 VC_TeenKey 1;
BA_ "FlexKomComment" SG_ 897 VC_TeenKey "Vehicle Configuration 7 Packet";
BA_ "FlexKomSigName" SG_ 897 VC_TeenKey "VehCfg7_Pkt";
BA_ "FlexKomSigLaenge" SG_ 897 VC_TeenKey 64;
BA_ "FlexKomSigStartPos" SG_ 897 VC_TeenKey 7;
BA_ "FlexKomSID" SG_ 897 VC_TeenKey 2026;
BA_ "GenSigTimeout_RF_HUB" SG_ 897 VC_TeenKey 21000;
BA_ "FlexKomSigStartValue" SG_ 897 VC_TeenKey "033F000000000000h";
BA_ "GenSigCycleTime" SG_ 897 VC_TeenKey 2000;
BA_ "GenSigSendType" SG_ 897 VC_TeenKey 5;
BA_ "GenSigSNA" SG_ 897 VC_SVC_Prsnt "0h";
BA_ "FlexKomIsMotorola" SG_ 897 VC_SVC_Prsnt 1;
BA_ "FlexKomComment" SG_ 897 VC_SVC_Prsnt "Vehicle Configuration 7 Packet";
BA_ "FlexKomSigName" SG_ 897 VC_SVC_Prsnt "VehCfg7_Pkt";
BA_ "FlexKomSigLaenge" SG_ 897 VC_SVC_Prsnt 64;
BA_ "FlexKomSigStartPos" SG_ 897 VC_SVC_Prsnt 7;
BA_ "FlexKomSID" SG_ 897 VC_SVC_Prsnt 2026;
BA_ "FlexKomSigStartValue" SG_ 897 VC_SVC_Prsnt "033F000000000000h";
BA_ "GenSigCycleTime" SG_ 897 VC_SVC_Prsnt 2000;
BA_ "GenSigSendType" SG_ 897 VC_SVC_Prsnt 5;
BA_ "GenSigSNA" SG_ 897 VC_SuspPrsnt "0h";
BA_ "FlexKomIsMotorola" SG_ 897 VC_SuspPrsnt 1;
BA_ "FlexKomComment" SG_ 897 VC_SuspPrsnt "Vehicle Configuration 7 Packet";
BA_ "FlexKomSigName" SG_ 897 VC_SuspPrsnt "VehCfg7_Pkt";
BA_ "FlexKomSigLaenge" SG_ 897 VC_SuspPrsnt 64;
BA_ "FlexKomSigStartPos" SG_ 897 VC_SuspPrsnt 7;
BA_ "FlexKomSID" SG_ 897 VC_SuspPrsnt 2026;
BA_ "GenSigTimeout_IC" SG_ 897 VC_SuspPrsnt 21000;
BA_ "FlexKomSigStartValue" SG_ 897 VC_SuspPrsnt "033F000000000000h";
BA_ "GenSigCycleTime" SG_ 897 VC_SuspPrsnt 2000;
BA_ "GenSigSendType" SG_ 897 VC_SuspPrsnt 5;
BA_ "GenSigSendType" SG_ 897 VC_SUNR_Prsnt 5;
BA_ "GenSigCycleTime" SG_ 897 VC_SUNR_Prsnt 2000;
BA_ "FlexKomSigStartValue" SG_ 897 VC_SUNR_Prsnt "033F000000000000h";
BA_ "FlexKomSID" SG_ 897 VC_SUNR_Prsnt 2026;
BA_ "FlexKomSigStartPos" SG_ 897 VC_SUNR_Prsnt 7;
BA_ "FlexKomSigLaenge" SG_ 897 VC_SUNR_Prsnt 64;
BA_ "FlexKomSigName" SG_ 897 VC_SUNR_Prsnt "VehCfg7_Pkt";
BA_ "FlexKomComment" SG_ 897 VC_SUNR_Prsnt "Vehicle Configuration 7 Packet";
BA_ "FlexKomIsMotorola" SG_ 897 VC_SUNR_Prsnt 1;
BA_ "GenSigSNA" SG_ 897 VC_SUNR_Prsnt "0h";
BA_ "GenSigSNA" SG_ 897 VC_STP_PRSNT "0h";
BA_ "FlexKomIsMotorola" SG_ 897 VC_STP_PRSNT 1;
BA_ "FlexKomComment" SG_ 897 VC_STP_PRSNT "Vehicle Configuration 7 Packet";
BA_ "FlexKomSigName" SG_ 897 VC_STP_PRSNT "VehCfg7_Pkt";
BA_ "FlexKomSigLaenge" SG_ 897 VC_STP_PRSNT 64;
BA_ "FlexKomSigStartPos" SG_ 897 VC_STP_PRSNT 7;
BA_ "FlexKomSID" SG_ 897 VC_STP_PRSNT 2026;
BA_ "GenSigTimeout_IC" SG_ 897 VC_STP_PRSNT 21000;
BA_ "FlexKomSigStartValue" SG_ 897 VC_STP_PRSNT "033F000000000000h";
BA_ "GenSigCycleTime" SG_ 897 VC_STP_PRSNT 2000;
BA_ "GenSigSendType" SG_ 897 VC_STP_PRSNT 5;
BA_ "GenSigSNA" SG_ 897 VC_RedKey "0h";
BA_ "FlexKomIsMotorola" SG_ 897 VC_RedKey 1;
BA_ "FlexKomComment" SG_ 897 VC_RedKey "Vehicle Configuration 7 Packet";
BA_ "FlexKomSigName" SG_ 897 VC_RedKey "VehCfg7_Pkt";
BA_ "FlexKomSigLaenge" SG_ 897 VC_RedKey 64;
BA_ "FlexKomSigStartPos" SG_ 897 VC_RedKey 7;
BA_ "FlexKomSID" SG_ 897 VC_RedKey 2026;
BA_ "GenSigTimeout_RF_HUB" SG_ 897 VC_RedKey 21000;
BA_ "FlexKomSigStartValue" SG_ 897 VC_RedKey "033F000000000000h";
BA_ "GenSigCycleTime" SG_ 897 VC_RedKey 2000;
BA_ "GenSigSendType" SG_ 897 VC_RedKey 5;
BA_ "GenSigSNA" SG_ 897 VC_PdlsMdPrsnt "0h";
BA_ "FlexKomIsMotorola" SG_ 897 VC_PdlsMdPrsnt 1;
BA_ "FlexKomComment" SG_ 897 VC_PdlsMdPrsnt "Vehicle Configuration 7 Packet";
BA_ "FlexKomSigName" SG_ 897 VC_PdlsMdPrsnt "VehCfg7_Pkt";
BA_ "FlexKomSigLaenge" SG_ 897 VC_PdlsMdPrsnt 64;
BA_ "FlexKomSigStartPos" SG_ 897 VC_PdlsMdPrsnt 7;
BA_ "FlexKomSID" SG_ 897 VC_PdlsMdPrsnt 2026;
BA_ "GenSigTimeout_IC" SG_ 897 VC_PdlsMdPrsnt 21000;
BA_ "FlexKomSigStartValue" SG_ 897 VC_PdlsMdPrsnt "033F000000000000h";
BA_ "GenSigCycleTime" SG_ 897 VC_PdlsMdPrsnt 2000;
BA_ "GenSigSendType" SG_ 897 VC_PdlsMdPrsnt 5;
BA_ "GenSigSNA" SG_ 897 VC_PBTyp "7h";
BA_ "FlexKomIsMotorola" SG_ 897 VC_PBTyp 1;
BA_ "FlexKomComment" SG_ 897 VC_PBTyp "Vehicle Configuration 7 Packet";
BA_ "FlexKomSigName" SG_ 897 VC_PBTyp "VehCfg7_Pkt";
BA_ "FlexKomSigLaenge" SG_ 897 VC_PBTyp 64;
BA_ "FlexKomSigStartPos" SG_ 897 VC_PBTyp 7;
BA_ "FlexKomSID" SG_ 897 VC_PBTyp 2026;
BA_ "GenSigTimeout_ORC" SG_ 897 VC_PBTyp 7000;
BA_ "FlexKomSigStartValue" SG_ 897 VC_PBTyp "033F000000000000h";
BA_ "GenSigCycleTime" SG_ 897 VC_PBTyp 2000;
BA_ "GenSigSendType" SG_ 897 VC_PBTyp 5;
BA_ "GenSigSNA" SG_ 897 VC_LDW "0h";
BA_ "FlexKomIsMotorola" SG_ 897 VC_LDW 1;
BA_ "FlexKomComment" SG_ 897 VC_LDW "Vehicle Configuration 7 Packet";
BA_ "FlexKomSigName" SG_ 897 VC_LDW "VehCfg7_Pkt";
BA_ "FlexKomSigLaenge" SG_ 897 VC_LDW 64;
BA_ "FlexKomSigStartPos" SG_ 897 VC_LDW 7;
BA_ "FlexKomSID" SG_ 897 VC_LDW 2026;
BA_ "GenSigTimeout_ORC" SG_ 897 VC_LDW 7000;
BA_ "FlexKomSigStartValue" SG_ 897 VC_LDW "033F000000000000h";
BA_ "GenSigCycleTime" SG_ 897 VC_LDW 2000;
BA_ "GenSigSendType" SG_ 897 VC_LDW 5;
BA_ "GenSigSNA" SG_ 897 VC_HybridType "0h";
BA_ "FlexKomIsMotorola" SG_ 897 VC_HybridType 1;
BA_ "FlexKomComment" SG_ 897 VC_HybridType "Vehicle Configuration 7 Packet";
BA_ "FlexKomSigName" SG_ 897 VC_HybridType "VehCfg7_Pkt";
BA_ "FlexKomSigLaenge" SG_ 897 VC_HybridType 64;
BA_ "FlexKomSigStartPos" SG_ 897 VC_HybridType 7;
BA_ "FlexKomSID" SG_ 897 VC_HybridType 2026;
BA_ "FlexKomSigStartValue" SG_ 897 VC_HybridType "033F000000000000h";
BA_ "GenSigCycleTime" SG_ 897 VC_HybridType 2000;
BA_ "GenSigSendType" SG_ 897 VC_HybridType 5;
BA_ "GenSigTimeout_ORC" SG_ 897 VC_HybridType 7000;
BA_ "GenSigSNA" SG_ 897 VC_FullSpeedRange_FCW "0h";
BA_ "FlexKomIsMotorola" SG_ 897 VC_FullSpeedRange_FCW 1;
BA_ "FlexKomComment" SG_ 897 VC_FullSpeedRange_FCW "Vehicle Configuration 7 Packet";
BA_ "FlexKomSigName" SG_ 897 VC_FullSpeedRange_FCW "VehCfg7_Pkt";
BA_ "FlexKomSigLaenge" SG_ 897 VC_FullSpeedRange_FCW 64;
BA_ "FlexKomSigStartPos" SG_ 897 VC_FullSpeedRange_FCW 7;
BA_ "FlexKomSID" SG_ 897 VC_FullSpeedRange_FCW 2026;
BA_ "GenSigTimeout_ORC" SG_ 897 VC_FullSpeedRange_FCW 7000;
BA_ "FlexKomSigStartValue" SG_ 897 VC_FullSpeedRange_FCW "033F000000000000h";
BA_ "GenSigCycleTime" SG_ 897 VC_FullSpeedRange_FCW 2000;
BA_ "GenSigSendType" SG_ 897 VC_FullSpeedRange_FCW 5;
BA_ "GenSigSNA" SG_ 897 VC_eShifter_Prsnt "0h";
BA_ "FlexKomIsMotorola" SG_ 897 VC_eShifter_Prsnt 1;
BA_ "FlexKomComment" SG_ 897 VC_eShifter_Prsnt "Vehicle Configuration 7 Packet";
BA_ "FlexKomSigName" SG_ 897 VC_eShifter_Prsnt "VehCfg7_Pkt";
BA_ "FlexKomSigLaenge" SG_ 897 VC_eShifter_Prsnt 64;
BA_ "FlexKomSigStartPos" SG_ 897 VC_eShifter_Prsnt 7;
BA_ "FlexKomSID" SG_ 897 VC_eShifter_Prsnt 2026;
BA_ "GenSigTimeout_RF_HUB" SG_ 897 VC_eShifter_Prsnt 21000;
BA_ "FlexKomSigStartValue" SG_ 897 VC_eShifter_Prsnt "033F000000000000h";
BA_ "GenSigCycleTime" SG_ 897 VC_eShifter_Prsnt 2000;
BA_ "GenSigSendType" SG_ 897 VC_eShifter_Prsnt 5;
BA_ "GenSigSNA" SG_ 897 VC_DST_Present "0h";
BA_ "FlexKomIsMotorola" SG_ 897 VC_DST_Present 1;
BA_ "FlexKomComment" SG_ 897 VC_DST_Present "Vehicle Configuration 7 Packet";
BA_ "FlexKomSigName" SG_ 897 VC_DST_Present "VehCfg7_Pkt";
BA_ "FlexKomSigLaenge" SG_ 897 VC_DST_Present 64;
BA_ "FlexKomSigStartPos" SG_ 897 VC_DST_Present 7;
BA_ "FlexKomSID" SG_ 897 VC_DST_Present 2026;
BA_ "GenSigTimeout_ORC" SG_ 897 VC_DST_Present 7000;
BA_ "FlexKomSigStartValue" SG_ 897 VC_DST_Present "033F000000000000h";
BA_ "GenSigCycleTime" SG_ 897 VC_DST_Present 2000;
BA_ "GenSigSendType" SG_ 897 VC_DST_Present 5;
BA_ "GenSigSNA" SG_ 897 VC_DampingPrsnt "0h";
BA_ "FlexKomIsMotorola" SG_ 897 VC_DampingPrsnt 1;
BA_ "FlexKomComment" SG_ 897 VC_DampingPrsnt "Vehicle Configuration 7 Packet";
BA_ "FlexKomSigName" SG_ 897 VC_DampingPrsnt "VehCfg7_Pkt";
BA_ "FlexKomSigLaenge" SG_ 897 VC_DampingPrsnt 64;
BA_ "FlexKomSigStartPos" SG_ 897 VC_DampingPrsnt 7;
BA_ "FlexKomSID" SG_ 897 VC_DampingPrsnt 2026;
BA_ "GenSigTimeout_IC" SG_ 897 VC_DampingPrsnt 21000;
BA_ "FlexKomSigStartValue" SG_ 897 VC_DampingPrsnt "033F000000000000h";
BA_ "GenSigCycleTime" SG_ 897 VC_DampingPrsnt 2000;
BA_ "GenSigSendType" SG_ 897 VC_DampingPrsnt 5;
BA_ "GenSigSNA" SG_ 897 VC_AxleLockerPrsnt "0h";
BA_ "FlexKomIsMotorola" SG_ 897 VC_AxleLockerPrsnt 1;
BA_ "FlexKomComment" SG_ 897 VC_AxleLockerPrsnt "Vehicle Configuration 7 Packet";
BA_ "FlexKomSigName" SG_ 897 VC_AxleLockerPrsnt "VehCfg7_Pkt";
BA_ "FlexKomSigLaenge" SG_ 897 VC_AxleLockerPrsnt 64;
BA_ "FlexKomSigStartPos" SG_ 897 VC_AxleLockerPrsnt 7;
BA_ "FlexKomSID" SG_ 897 VC_AxleLockerPrsnt 2026;
BA_ "FlexKomSigStartValue" SG_ 897 VC_AxleLockerPrsnt "033F000000000000h";
BA_ "GenSigCycleTime" SG_ 897 VC_AxleLockerPrsnt 2000;
BA_ "GenSigSendType" SG_ 897 VC_AxleLockerPrsnt 5;
BA_ "GenSigSNA" SG_ 897 VC_AS_ERS "3h";
BA_ "FlexKomIsMotorola" SG_ 897 VC_AS_ERS 1;
BA_ "FlexKomComment" SG_ 897 VC_AS_ERS "Vehicle Configuration 7 Packet";
BA_ "FlexKomSigName" SG_ 897 VC_AS_ERS "VehCfg7_Pkt";
BA_ "FlexKomSigLaenge" SG_ 897 VC_AS_ERS 64;
BA_ "FlexKomSigStartPos" SG_ 897 VC_AS_ERS 7;
BA_ "FlexKomSID" SG_ 897 VC_AS_ERS 2026;
BA_ "GenSigTimeout_IC" SG_ 897 VC_AS_ERS 21000;
BA_ "FlexKomSigStartValue" SG_ 897 VC_AS_ERS "033F000000000000h";
BA_ "GenSigCycleTime" SG_ 897 VC_AS_ERS 2000;
BA_ "GenSigSendType" SG_ 897 VC_AS_ERS 5;
BA_ "GenSigSNA" SG_ 897 VC_ACC_Type "0h";
BA_ "FlexKomIsMotorola" SG_ 897 VC_ACC_Type 1;
BA_ "FlexKomComment" SG_ 897 VC_ACC_Type "Vehicle Configuration 7 Packet";
BA_ "FlexKomSigName" SG_ 897 VC_ACC_Type "VehCfg7_Pkt";
BA_ "FlexKomSigLaenge" SG_ 897 VC_ACC_Type 64;
BA_ "FlexKomSigStartPos" SG_ 897 VC_ACC_Type 7;
BA_ "FlexKomSID" SG_ 897 VC_ACC_Type 2026;
BA_ "GenSigTimeout_ORC" SG_ 897 VC_ACC_Type 7000;
BA_ "FlexKomSigStartValue" SG_ 897 VC_ACC_Type "033F000000000000h";
BA_ "GenSigCycleTime" SG_ 897 VC_ACC_Type 2000;
BA_ "GenSigSendType" SG_ 897 VC_ACC_Type 5;
BA_ "GenSigSNA" SG_ 897 VC_ABSM "0h";
BA_ "FlexKomIsMotorola" SG_ 897 VC_ABSM 1;
BA_ "FlexKomComment" SG_ 897 VC_ABSM "Vehicle Configuration 7 Packet";
BA_ "FlexKomSigName" SG_ 897 VC_ABSM "VehCfg7_Pkt";
BA_ "FlexKomSigLaenge" SG_ 897 VC_ABSM 64;
BA_ "FlexKomSigStartPos" SG_ 897 VC_ABSM 7;
BA_ "FlexKomSID" SG_ 897 VC_ABSM 2026;
BA_ "GenSigTimeout_HaLF" SG_ 897 VC_ABSM 21000;
BA_ "GenSigTimeout_IC" SG_ 897 VC_ABSM 21000;
BA_ "FlexKomSigStartValue" SG_ 897 VC_ABSM "033F000000000000h";
BA_ "GenSigCycleTime" SG_ 897 VC_ABSM 2000;
BA_ "GenSigSendType" SG_ 897 VC_ABSM 5;
BA_ "GenMsgStartValue" BO_ 882 "00F8FCF001FE01FEh";
BA_ "GenMsgNrOfRepetitions" BO_ 882 2;
BA_ "GenMsgDelayTime" BO_ 882 20;
BA_ "GenMsgCycleTime" BO_ 882 1000;
BA_ "GenMsgSendType" BO_ 882 5;
BA_ "GenSigSNA" SG_ 882 TorqueUnit "0h";
BA_ "FlexKomIsMotorola" SG_ 882 TorqueUnit 1;
BA_ "FlexKomComment" SG_ 882 TorqueUnit "Torque units; Foot Pounds (ft-lb) = [1]";
BA_ "FlexKomSigName" SG_ 882 TorqueUnit "TorqueUnit";
BA_ "FlexKomSigLaenge" SG_ 882 TorqueUnit 1;
BA_ "FlexKomSigStartPos" SG_ 882 TorqueUnit 7;
BA_ "FlexKomSID" SG_ 882 TorqueUnit 1998;
BA_ "FlexKomSigStartValue" SG_ 882 TorqueUnit "00h";
BA_ "GenSigCycleTime" SG_ 882 TorqueUnit 1000;
BA_ "GenSigSendType" SG_ 882 TorqueUnit 5;
BA_ "GenSigSNA" SG_ 882 TemperatureUnit "0h";
BA_ "FlexKomIsMotorola" SG_ 882 TemperatureUnit 1;
BA_ "FlexKomComment" SG_ 882 TemperatureUnit "Temperature units; Farenheit = [1]";
BA_ "FlexKomSigName" SG_ 882 TemperatureUnit "TemperatureUnit";
BA_ "FlexKomSigLaenge" SG_ 882 TemperatureUnit 1;
BA_ "FlexKomSigStartPos" SG_ 882 TemperatureUnit 52;
BA_ "FlexKomSID" SG_ 882 TemperatureUnit 2003;
BA_ "FlexKomSigStartValue" SG_ 882 TemperatureUnit "00h";
BA_ "GenSigCycleTime" SG_ 882 TemperatureUnit 1000;
BA_ "GenSigSendType" SG_ 882 TemperatureUnit 5;
BA_ "GenSigSNA" SG_ 882 SpeedUnit "0h";
BA_ "FlexKomIsMotorola" SG_ 882 SpeedUnit 1;
BA_ "FlexKomComment" SG_ 882 SpeedUnit "Speed (speedometer) units; Miles = [1]";
BA_ "FlexKomSigName" SG_ 882 SpeedUnit "SpeedUnit";
BA_ "FlexKomSigLaenge" SG_ 882 SpeedUnit 1;
BA_ "FlexKomSigStartPos" SG_ 882 SpeedUnit 51;
BA_ "FlexKomSID" SG_ 882 SpeedUnit 2004;
BA_ "FlexKomSigStartValue" SG_ 882 SpeedUnit "00h";
BA_ "GenSigCycleTime" SG_ 882 SpeedUnit 1000;
BA_ "GenSigSendType" SG_ 882 SpeedUnit 5;
BA_ "GenSigSNA" SG_ 882 RDY_DRV_STAT_CSO "0h";
BA_ "FlexKomIsMotorola" SG_ 882 RDY_DRV_STAT_CSO 1;
BA_ "FlexKomSigName" SG_ 882 RDY_DRV_STAT_CSO "RDY_DRV_STAT_CSO";
BA_ "FlexKomSigLaenge" SG_ 882 RDY_DRV_STAT_CSO 1;
BA_ "FlexKomSigStartPos" SG_ 882 RDY_DRV_STAT_CSO 17;
BA_ "FlexKomSID" SG_ 882 RDY_DRV_STAT_CSO 2592;
BA_ "FlexKomSigStartValue" SG_ 882 RDY_DRV_STAT_CSO "00h";
BA_ "GenSigCycleTime" SG_ 882 RDY_DRV_STAT_CSO 1000;
BA_ "GenSigSendType" SG_ 882 RDY_DRV_STAT_CSO 5;
BA_ "FlexKomComment" SG_ 882 RDY_DRV_STAT_CSO "Ready to drive popup status enable/disable; Disabl";
BA_ "GenSigSNA" SG_ 882 PressureUnit "0h";
BA_ "FlexKomIsMotorola" SG_ 882 PressureUnit 1;
BA_ "FlexKomComment" SG_ 882 PressureUnit "Pressure units";
BA_ "FlexKomSigName" SG_ 882 PressureUnit "PressureUnit";
BA_ "FlexKomSigLaenge" SG_ 882 PressureUnit 2;
BA_ "FlexKomSigStartPos" SG_ 882 PressureUnit 37;
BA_ "FlexKomSID" SG_ 882 PressureUnit 2000;
BA_ "GenSigTimeout_CBC" SG_ 882 PressureUnit 10500;
BA_ "FlexKomSigStartValue" SG_ 882 PressureUnit "00h";
BA_ "GenSigCycleTime" SG_ 882 PressureUnit 1000;
BA_ "GenSigSendType" SG_ 882 PressureUnit 5;
BA_ "GenSigSNA" SG_ 882 PowerUnit "0h";
BA_ "FlexKomIsMotorola" SG_ 882 PowerUnit 1;
BA_ "FlexKomComment" SG_ 882 PowerUnit "Power units";
BA_ "FlexKomSigName" SG_ 882 PowerUnit "PowerUnit";
BA_ "FlexKomSigLaenge" SG_ 882 PowerUnit 2;
BA_ "FlexKomSigStartPos" SG_ 882 PowerUnit 35;
BA_ "FlexKomSID" SG_ 882 PowerUnit 1999;
BA_ "GenSigTimeout_CBC" SG_ 882 PowerUnit 10500;
BA_ "FlexKomSigStartValue" SG_ 882 PowerUnit "00h";
BA_ "GenSigCycleTime" SG_ 882 PowerUnit 1000;
BA_ "GenSigSendType" SG_ 882 PowerUnit 5;
BA_ "GenSigSNA" SG_ 882 LANG_C "1Fh";
BA_ "FlexKomIsMotorola" SG_ 882 LANG_C 1;
BA_ "FlexKomComment" SG_ 882 LANG_C "Configuration status";
BA_ "FlexKomSigName" SG_ 882 LANG_C "CFG_STAT_C";
BA_ "FlexKomSigLaenge" SG_ 882 LANG_C 6;
BA_ "FlexKomSigStartPos" SG_ 882 LANG_C 15;
BA_ "FlexKomSID" SG_ 882 LANG_C 1804;
BA_ "GenSigTimeout_CBC" SG_ 882 LANG_C 10500;
BA_ "GenSigStartValue" SG_ 882 LANG_C 31;
BA_ "FlexKomSigStartValue" SG_ 882 LANG_C "3Eh";
BA_ "GenSigCycleTime" SG_ 882 LANG_C 1000;
BA_ "GenSigSendType" SG_ 882 LANG_C 5;
BA_ "GenSigSNA" SG_ 882 DistanceUnit "0h";
BA_ "FlexKomIsMotorola" SG_ 882 DistanceUnit 1;
BA_ "FlexKomComment" SG_ 882 DistanceUnit "Distance (odometer) units; Miles = [1]";
BA_ "FlexKomSigName" SG_ 882 DistanceUnit "DistanceUnit";
BA_ "FlexKomSigLaenge" SG_ 882 DistanceUnit 1;
BA_ "FlexKomSigStartPos" SG_ 882 DistanceUnit 50;
BA_ "FlexKomSID" SG_ 882 DistanceUnit 2002;
BA_ "FlexKomSigStartValue" SG_ 882 DistanceUnit "00h";
BA_ "GenSigCycleTime" SG_ 882 DistanceUnit 1000;
BA_ "GenSigSendType" SG_ 882 DistanceUnit 5;
BA_ "GenSigSNA" SG_ 882 ConsumptionUnit "7h";
BA_ "FlexKomIsMotorola" SG_ 882 ConsumptionUnit 1;
BA_ "FlexKomComment" SG_ 882 ConsumptionUnit "Fuel consumption units";
BA_ "FlexKomSigName" SG_ 882 ConsumptionUnit "ConsumptionUnit";
BA_ "FlexKomSigLaenge" SG_ 882 ConsumptionUnit 3;
BA_ "FlexKomSigStartPos" SG_ 882 ConsumptionUnit 55;
BA_ "FlexKomSID" SG_ 882 ConsumptionUnit 2005;
BA_ "GenSigTimeout_CBC" SG_ 882 ConsumptionUnit 10500;
BA_ "FlexKomSigStartValue" SG_ 882 ConsumptionUnit "00h";
BA_ "GenSigCycleTime" SG_ 882 ConsumptionUnit 1000;
BA_ "GenSigSendType" SG_ 882 ConsumptionUnit 5;
BA_ "GenSigSNA" SG_ 882 CapacityUnit "0h";
BA_ "FlexKomIsMotorola" SG_ 882 CapacityUnit 1;
BA_ "FlexKomComment" SG_ 882 CapacityUnit "Fuel capacity units";
BA_ "FlexKomSigName" SG_ 882 CapacityUnit "CapacityUnit";
BA_ "FlexKomSigLaenge" SG_ 882 CapacityUnit 2;
BA_ "FlexKomSigStartPos" SG_ 882 CapacityUnit 39;
BA_ "FlexKomSID" SG_ 882 CapacityUnit 2001;
BA_ "GenSigTimeout_CBC" SG_ 882 CapacityUnit 10500;
BA_ "FlexKomSigStartValue" SG_ 882 CapacityUnit "00h";
BA_ "GenSigCycleTime" SG_ 882 CapacityUnit 1000;
BA_ "GenSigSendType" SG_ 882 CapacityUnit 5;
VAL_ 993 NUM_VALVE 7 "SNA" ;
VAL_ 993 NUM_CYL 15 "SNA" ;
VAL_ 993 Manufacture 7 "ENG_NP" 3 "ENG_HY" 2 "ENG_MMC" 1 "ENG_DCS" 0 "ENG_DCA" ;
VAL_ 993 FUEL_TYPE 7 "SNA" 3 "CNG" 2 "FLEX" 1 "DIESEL" 0 "UNLEADED" ;
VAL_ 993 EngStyle 7 "SNA" 5 "CHOICE6" 4 "CHOICE5" 3 "CHOICE4" 2 "CHOICE3" 1 "CHOICE2" 0 "CHOICE1" ;
VAL_ 993 ENG_ASP 7 "SNA" 3 "SUPER" 2 "TURBO2" 1 "TURBO1" 0 "INTAKE_NORM" ;
VAL_ 993 ECM_Vehi_Type 3 "SNA" 1 "EVEHICLE" 0 "STANDARD" ;
VAL_ 993 DISPLACEMENT 255 "SNA" ;
VAL_ 992 VIN_MSG 3 "SNA" 2 "VIN_HI" 1 "VIN_MID" 0 "VIN_LO" ;
VAL_ 984 EC_ECUCfg9_Stat 3 "SNA" 2 "REQUEST_DATA" 1 "PROGAMMED" 0 "NA" ;
VAL_ 983 EC_ECUCfg10_Stat 3 "SNA" 2 "REQUEST_DATA" 1 "PROGAMMED" 0 "NA" ;
VAL_ 982 EC_ECUCfg11_Stat 3 "SNA" 2 "REQUEST_DATA" 1 "PROGAMMED" 0 "NA" ;
VAL_ 981 EC_ECUCfg12_Stat 3 "SNA" 2 "REQUEST_DATA" 1 "PROGAMMED" 0 "NA" ;
VAL_ 980 EC_ECUCfg13_Stat 3 "SNA" 2 "REQUEST_DATA" 1 "PROGAMMED" 0 "NA" ;
VAL_ 979 EC_ECUCfg14_Stat 3 "SNA" 2 "REQUEST_DATA" 1 "PROGAMMED" 0 "NA" ;
VAL_ 974 PAS_TEMP_DR_POS 127 "SNA" ;
VAL_ 974 FT_HVAC_BLW_FN_SP 127 "SNA" ;
VAL_ 974 DRV_TEMP_DR_POS 127 "SNA" ;
VAL_ 969 AMB_TEMP_AVG_F 255 "SNA" ;
VAL_ 969 AMB_TEMP_AVG_C 255 "SNA" ;
VAL_ 956 NAV_GrpTyp 63 "SNA" 0 "NO_TEXT" ;
VAL_ 948 VC_VehCfgCSO2_Stat 3 "SNA" 2 "REQUEST_DATA" 1 "PROGAMMED" 0 "NA" ;
VAL_ 948 VC_SPEED_WARNING_CSO 2 "FIVE" 1 "ONE" 0 "ABSENT" ;
VAL_ 947 VC_VehCfgCSO1_Stat 3 "SNA" 2 "REQUEST_DATA" 1 "PROGAMMED" 0 "NA" ;
VAL_ 947 VC_PRK_AST_CSO 2 "Option_2_3" 1 "Option_1_2" 0 "Absent" ;
VAL_ 947 VC_HRN_RMT_LK_CSO 2 "Option_2_3" 1 "Option_1_2" 0 "Absent" ;
VAL_ 947 VC_FCW_CSO 2 "Option_2_3" 1 "Option_1_2" 0 "Absent" ;
VAL_ 947 VC_DCS_CSO 2 "Option_2_3" 1 "Option_1_2" 0 "Absent" ;
VAL_ 947 VC_CMRA_GRDLNS_CSO 3 "STATIC_DYNAMIC" 2 "DYNAMIC" 1 "STATIC" 0 "Absent" ;
VAL_ 947 VC_AUX_SWS_CSO 2 "SWITCH_2_5" 1 "SWITCH_1_4" 0 "Absent" ;
VAL_ 943 B_Total_Dist_Miles 16777215 "SNA" ;
VAL_ 943 B_Total_Dist_Kilometers 16777215 "SNA" ;
VAL_ 942 B_KMpL 1023 "SNA" ;
VAL_ 942 B_Hybrid_Miles 16777215 "SNA" ;
VAL_ 942 B_Hybrid_Kilometers 16777215 "SNA" ;
VAL_ 941 B_MPG 1023 "SNA" ;
VAL_ 941 B_EV_Miles 16777215 "SNA" ;
VAL_ 941 B_EV_Kilometers 16777215 "SNA" ;
VAL_ 940 A_Total_Dist_Miles 16777215 "SNA" ;
VAL_ 940 A_Total_Dist_Kilometers 16777215 "SNA" ;
VAL_ 939 A_KMpL 1023 "SNA" ;
VAL_ 939 A_Hybrid_Miles 16777215 "SNA" ;
VAL_ 939 A_Hybrid_Kilometers 16777215 "SNA" ;
VAL_ 938 A_MPG 1023 "SNA" ;
VAL_ 938 A_EV_Miles 16777215 "SNA" ;
VAL_ 938 A_EV_Kilometers 16777215 "SNA" ;
VAL_ 937 SOUND_LK_1ST_2ND 3 "SNA" 2 "SECOND" 1 "FIRST" 0 "OFF" ;
VAL_ 937 ILL_APRCH_TIME 255 "SNA" ;
VAL_ 937 HL_DLY_TIME 255 "SNA" ;
VAL_ 924 MsgServPEKG 3 "SNA" 1 "MSG_ACTIVE" 0 "MSG_DEFAULT" ;
VAL_ 924 MsgNotInPark 3 "SNA" 1 "MSG_ACTIVE" 0 "MSG_DEFAULT" ;
VAL_ 924 MsgKG2 3 "SNA" 1 "MSG_ACTIVE" 0 "MSG_DEFAULT" ;
VAL_ 924 MsgKG1 3 "SNA" 1 "MSG_ACTIVE" 0 "MSG_DEFAULT" ;
VAL_ 924 MsgFobNotFnd 3 "SNA" 1 "MSG_ACTIVE" 0 "MSG_DEFAULT" ;
VAL_ 924 MsgFobBattLow 3 "SNA" 1 "MSG_ACTIVE" 0 "MSG_DEFAULT" ;
VAL_ 924 FOB_SrchRslt 3 "TIMEOUT" 2 "COMPLETE" 1 "SIP" 0 "NO_ACT" ;
VAL_ 897 VC_VehCfg7_Stat 3 "SNA" 2 "REQUEST_DATA" 1 "PROGAMMED" 0 "NA" ;
VAL_ 897 VC_TransType 1 "SI_EVT_Hybrid_Trans" 63 "SNA" 14 "ZF_9Spd" 13 "ZF_8Spd" 12 "HPT_6F24" 11 "DDCT_C635" 10 "AISIN_HD" 9 "c68RFE" 8 "c66RFE" 7 "c65RFE" 6 "c62TE" 5 "W5A580" 4 "Aisin_LD" 3 "c40TES" 2 "MTA" 0 "NP" ;
VAL_ 897 VC_TPMS_Configuration 7 "SNA" 4 "CHINA" 3 "OTHER" 2 "ECE" 1 "NAFTA" 0 "NHTSA" ;
VAL_ 897 VC_PBTyp 7 "SNA" 4 "ICP" 3 "IMOC" 2 "EPB_CP" 1 "EPB_MOC" 0 "MECH" ;
VAL_ 897 VC_HybridType 4 "BSG48" 3 "PHEV" 2 "HEV" 1 "BEV" 0 "NONE" ;
VAL_ 897 VC_AxleLockerPrsnt 2 "FTRR" 1 "REAR" 0 "NONE" ;
VAL_ 897 VC_AS_ERS 3 "SNA" 2 "AS" 1 "ERS" 0 "NONE" ;
VAL_ 897 VC_ACC_Type 3 "GO" 2 "STOP" 1 "ACC" 0 "NONE" ;
VAL_ 882 PressureUnit 2 "PSI" 1 "BAR" 0 "KPA" ;
VAL_ 882 PowerUnit 2 "HP_US" 1 "HP_UK" 0 "KW" ;
VAL_ 882 LANG_C 31 "LANG_NO_CHG" 17 "POLISH" 16 "TURKISH" 15 "HINDI" 14 "MANDARIN_T" 13 "BRAZILIAN" 12 "ARABIC" 11 "KOREAN" 10 "RUSSIAN" 9 "MANDARIN_S" 8 "UK_ENGLISH" 7 "DUTCH" 6 "PORTUGESE" 5 "JAPANESE" 4 "SPANISH" 3 "ITALIAN" 2 "FRENCH" 1 "US_ENGLISH" 0 "GERMAN" ;
VAL_ 882 ConsumptionUnit 7 "SNA" 3 "MPG_US" 2 "MPG_UK" 1 "LP100KM" 0 "KMPL" ;
VAL_ 882 CapacityUnit 2 "G_US" 1 "G_UK" 0 "L" ;
